VERSION ""

NS_ :

BS_:

BU_: PowertrainControlModule AtmosphericSensor SafetyRestraintSystem2 Aftertreatment_2_GasOutlet Aftertreatment_2_GasIntake DieselParticulateFilterControl Turbocharger SafetyRestraintSystem1 CabDisplay2 Aftertreatment_1_GasOutlet Aftertreatment_1_GasIntake OnBoardDataLogger OffBoardDiagnosticTool2 OffBoardDiagnosticTool1 FileServer ParkingBrakeController SeatController2 FanDriveController SteeringColumnUnit CommunicationUnitRadio CommunicationUnitSatellite CommunicationUnitCellular PropulsionBatteryCharger ChassisController2 ChassisController1 EngineValveControl AuxiliaryHeater2 AuxiliaryHeater1 ClutchUnit RampControl InformationSystem1 SuspensionSystemController2 OilSensor VehicleDynamicStability ExhaustEmissionController TransmissionDisplay2 TransmissionDisplay1 ClimateControl2 WaterPumpController RearAxleSteeringController LightingOperatorControl SeatController1 IgnitionController2 IgnitionController1 TirePressureController CabController2 CabController1 PneumaticSystemController SuspensionSystemController1 HydraulicPumpController EnduranceBrakingSystem RetarderExhaustEngine2 OnBoardDiagnosticUnit HeadwayController RetarderExhaustEngine1 CabDisplay1 ManagementComputer VirtualTerminal OffVehicleGateway PowerTakeOffFront HitchControl AuxiliaryValveControl BodyController TractorTrailerBridge1 StarterSystem ElectricalSystem VehicleSecurity VehicleNavigation AerodynamicControl ElectricalChargingSystem ClimateControl1 TripRecorder InstrumentCluster SuspensionDriveAxle2 SuspensionDriveAxle1 SuspensionSteerAxle SteeringController FuelSystem CruiseControl RetarderDriveline RetarderEngine BrakesDriveAxle2 BrakesDriveAxle1 BrakesSystemController BrakesSteerAxle AxleDrive2 AxleDrive1 AxleSteering PowerTakeOff ShiftConsoleSecondary ShiftConsolePrimary Transmission2 Transmission1 Engine2 Engine1

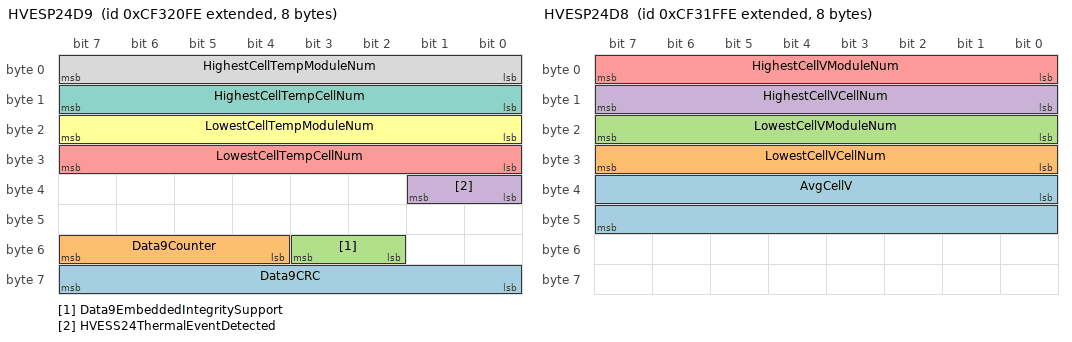
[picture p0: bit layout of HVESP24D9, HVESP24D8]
BO_ 2364743934 HVESP24D9: 8 Vector__XXX
 SG_ Data9CRC : 56|8@1+ (1,0) [0|255] "" Vector__XXX
 SG_ Data9Counter : 52|4@1+ (1,0) [0|15] "" Vector__XXX
 SG_ Data9EmbeddedIntegritySupport : 50|2@1+ (1,0) [0|3] "" Vector__XXX
 SG_ HVESS24ThermalEventDetected : 32|2@1+ (1,0) [0|3] "" Vector__XXX
 SG_ LowestCellTempCellNum : 24|8@1+ (1,0) [0|250] "" Vector__XXX
 SG_ LowestCellTempModuleNum : 16|8@1+ (1,0) [0|250] "" Vector__XXX
 SG_ HighestCellTempCellNum : 8|8@1+ (1,0) [0|250] "" Vector__XXX
 SG_ HighestCellTempModuleNum : 0|8@1+ (1,0) [0|250] "" Vector__XXX

BO_ 2364743678 HVESP24D8: 8 Vector__XXX
 SG_ AvgCellV : 32|16@1+ (0.001,0) [0|64.255] "V" Vector__XXX
 SG_ LowestCellVCellNum : 24|8@1+ (1,0) [0|250] "" Vector__XXX
 SG_ LowestCellVModuleNum : 16|8@1+ (1,0) [0|250] "" Vector__XXX
 SG_ HighestCellVCellNum : 8|8@1+ (1,0) [0|250] "" Vector__XXX
 SG_ HighestCellVModuleNum : 0|8@1+ (1,0) [0|250] "" Vector__XXX

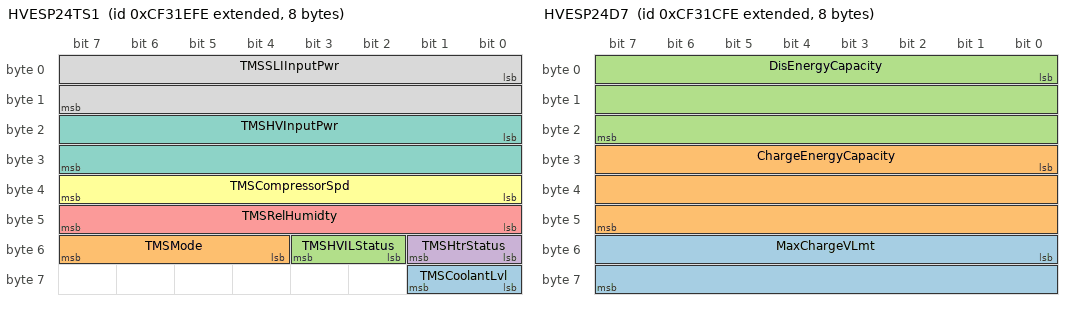
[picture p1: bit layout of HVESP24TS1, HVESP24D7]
BO_ 2364743422 HVESP24TS1: 8 Vector__XXX
 SG_ TMSCoolantLvl : 56|2@1+ (1,0) [0|3] "" Vector__XXX
 SG_ TMSMode : 52|4@1+ (1,0) [0|15] "" Vector__XXX
 SG_ TMSHVILStatus : 50|2@1+ (1,0) [0|3] "" Vector__XXX
 SG_ TMSHtrStatus : 48|2@1+ (1,0) [0|3] "" Vector__XXX
 SG_ TMSRelHumidty : 40|8@1+ (0.4,0) [0|100] "%" Vector__XXX
 SG_ TMSCompressorSpd : 32|8@1+ (32,0) [0|8000] "rpm" Vector__XXX
 SG_ TMSHVInputPwr : 16|16@1+ (0.5,0) [0|32127.5] "W" Vector__XXX
 SG_ TMSSLIInputPwr : 0|16@1+ (0.5,0) [0|32127.5] "W" Vector__XXX

BO_ 2364743166 HVESP24MS1: 8 Vector__XXX
 SG_ Module32OperationalStatus : 62|2@1+ (1,0) [0|3] "" Vector__XXX
 SG_ Module31OperationalStatus : 60|2@1+ (1,0) [0|3] "" Vector__XXX
 SG_ Module30OperationalStatus : 58|2@1+ (1,0) [0|3] "" Vector__XXX
 SG_ Module29OperationalStatus : 56|2@1+ (1,0) [0|3] "" Vector__XXX
 SG_ Module28OperationalStatus : 54|2@1+ (1,0) [0|3] "" Vector__XXX
 SG_ Module27OperationalStatus : 52|2@1+ (1,0) [0|3] "" Vector__XXX
 SG_ Module26OperationalStatus : 50|2@1+ (1,0) [0|3] "" Vector__XXX
 SG_ Module25OperationalStatus : 48|2@1+ (1,0) [0|3] "" Vector__XXX
 SG_ Module24OperationalStatus : 46|2@1+ (1,0) [0|3] "" Vector__XXX
 SG_ Module23OperationalStatus : 44|2@1+ (1,0) [0|3] "" Vector__XXX
 SG_ Module22OperationalStatus : 42|2@1+ (1,0) [0|3] "" Vector__XXX
 SG_ Module21OperationalStatus : 40|2@1+ (1,0) [0|3] "" Vector__XXX
 SG_ Module20OperationalStatus : 38|2@1+ (1,0) [0|3] "" Vector__XXX
 SG_ Module19OperationalStatus : 36|2@1+ (1,0) [0|3] "" Vector__XXX
 SG_ Module18OperationalStatus : 34|2@1+ (1,0) [0|3] "" Vector__XXX
 SG_ Module17OperationalStatus : 32|2@1+ (1,0) [0|3] "" Vector__XXX
 SG_ Module16OperationalStatus : 30|2@1+ (1,0) [0|3] "" Vector__XXX
 SG_ Module15OperationalStatus : 28|2@1+ (1,0) [0|3] "" Vector__XXX
 SG_ Module14OperationalStatus : 26|2@1+ (1,0) [0|3] "" Vector__XXX
 SG_ Module13OperationalStatus : 24|2@1+ (1,0) [0|3] "" Vector__XXX
 SG_ Module12OperationalStatus : 22|2@1+ (1,0) [0|3] "" Vector__XXX
 SG_ Module11OperationalStatus : 20|2@1+ (1,0) [0|3] "" Vector__XXX
 SG_ Module10OperationalStatus : 18|2@1+ (1,0) [0|3] "" Vector__XXX
 SG_ Module9OperationalStatus : 16|2@1+ (1,0) [0|3] "" Vector__XXX
 SG_ Module8OperationalStatus : 14|2@1+ (1,0) [0|3] "" Vector__XXX
 SG_ Module7OperationalStatus : 12|2@1+ (1,0) [0|3] "" Vector__XXX
 SG_ Module6OperationalStatus : 10|2@1+ (1,0) [0|3] "" Vector__XXX
 SG_ Module5OperationalStatus : 8|2@1+ (1,0) [0|3] "" Vector__XXX
 SG_ Module4OperationalStatus : 6|2@1+ (1,0) [0|3] "" Vector__XXX
 SG_ Module3OperationalStatus : 4|2@1+ (1,0) [0|3] "" Vector__XXX
 SG_ Module2OperationalStatus : 2|2@1+ (1,0) [0|3] "" Vector__XXX
 SG_ Module1OperationalStatus : 0|2@1+ (1,0) [0|3] "" Vector__XXX

BO_ 2364742910 HVESP24D7: 8 Vector__XXX
 SG_ MaxChargeVLmt : 48|16@1+ (0.05,0) [0|3212.75] "V" Vector__XXX
 SG_ ChargeEnergyCapacity : 24|24@1+ (0.001,0) [0|16449.535] "kWh" Vector__XXX
 SG_ DisEnergyCapacity : 0|24@1+ (0.001,0) [0|16449.535] "kWh" Vector__XXX

BO_ 2364742654 HVESP24S1: 8 Vector__XXX
 SG_ Status1CRC : 56|8@1+ (1,0) [0|255] "" Vector__XXX
 SG_ Status1Counter : 52|4@1+ (1,0) [0|15] "" Vector__XXX
 SG_ OperationalStatus : 44|4@1+ (1,0) [0|15] "" Vector__XXX
 SG_ HVBusConnectionStatus : 40|4@1+ (1,0) [0|15] "" Vector__XXX
 SG_ InternalChargerStatus : 32|2@1+ (1,0) [0|3] "" Vector__XXX
 SG_ CellBalancingActive : 30|2@1+ (1,0) [0|3] "" Vector__XXX
 SG_ CellBalanceStatus : 28|2@1+ (1,0) [0|3] "" Vector__XXX
 SG_ StOfChargeStatus : 24|4@1+ (1,0) [0|15] "" Vector__XXX
 SG_ InertiaSwStatus : 22|2@1+ (1,0) [0|3] "" Vector__XXX
 SG_ HVILStatus : 20|2@1+ (1,0) [0|3] "" Vector__XXX
 SG_ HVBusPassiveIsolTestStatus : 16|4@1+ (1,0) [0|15] "" Vector__XXX
 SG_ HVBusActiveIsolTestStatus : 12|4@1+ (1,0) [0|15] "" Vector__XXX
 SG_ CenterOfPackContactorSt : 10|2@1+ (1,0) [0|3] "" Vector__XXX
 SG_ HVBusPreChargeRelaySt : 8|2@1+ (1,0) [0|3] "" Vector__XXX
 SG_ HVBusDisconnectForewarning : 4|4@1+ (1,0) [0|15] "" Vector__XXX
 SG_ HVBusContactorSt17164 : 2|2@1+ (1,0) [0|3] "" Vector__XXX
 SG_ HVBusContactorSt : 0|2@1+ (1,0) [0|3] "" Vector__XXX

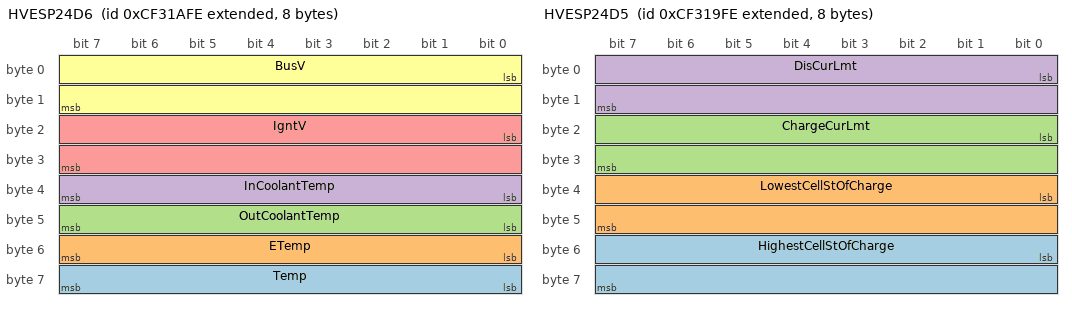
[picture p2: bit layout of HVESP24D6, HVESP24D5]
BO_ 2364742398 HVESP24D6: 8 Vector__XXX
 SG_ Temp : 56|8@1+ (1,-40) [-40|210] "°C" Vector__XXX
 SG_ ETemp : 48|8@1+ (1,-40) [-40|210] "°C" Vector__XXX
 SG_ OutCoolantTemp : 40|8@1+ (1,-40) [-40|210] "°C" Vector__XXX
 SG_ InCoolantTemp : 32|8@1+ (1,-40) [-40|210] "°C" Vector__XXX
 SG_ IgntV : 16|16@1+ (0.01,0) [0|642.55] "V" Vector__XXX
 SG_ BusV : 0|16@1+ (0.05,0) [0|3212.75] "V" Vector__XXX

BO_ 2364742142 HVESP24D5: 8 Vector__XXX
 SG_ HighestCellStOfCharge : 48|16@1+ (0.0015625,0) [0|100.3984375] "%" Vector__XXX
 SG_ LowestCellStOfCharge : 32|16@1+ (0.0015625,0) [0|100.3984375] "%" Vector__XXX
 SG_ ChargeCurLmt : 16|16@1+ (0.05,-1600) [0|1612.75] "A" Vector__XXX
 SG_ DisCurLmt : 0|16@1+ (0.05,-1600) [-1600|0] "A" Vector__XXX

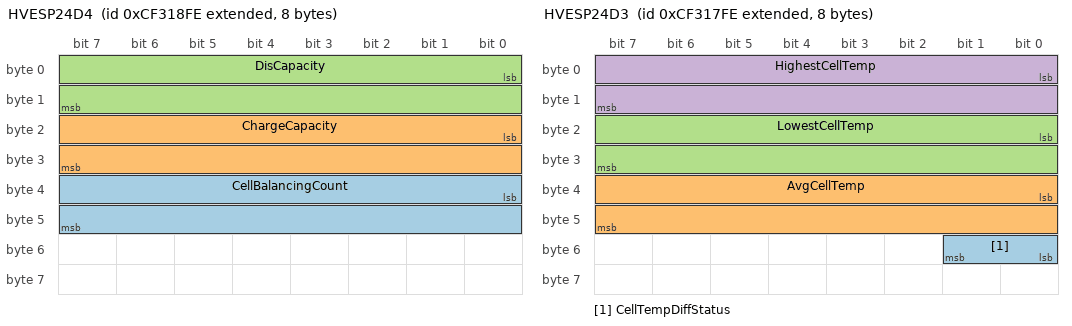
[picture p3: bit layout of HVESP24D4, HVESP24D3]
BO_ 2364741886 HVESP24D4: 8 Vector__XXX
 SG_ CellBalancingCount : 32|16@1+ (1,0) [0|64255] "" Vector__XXX
 SG_ ChargeCapacity : 16|16@1+ (0.01,0) [0|642.55] "Ah" Vector__XXX
 SG_ DisCapacity : 0|16@1+ (0.01,0) [0|642.55] "Ah" Vector__XXX

BO_ 2364741630 HVESP24D3: 8 Vector__XXX
 SG_ CellTempDiffStatus : 48|2@1+ (1,0) [0|3] "" Vector__XXX
 SG_ AvgCellTemp : 32|16@1+ (0.03125,-273) [-273|1734.96875] "°C" Vector__XXX
 SG_ LowestCellTemp : 16|16@1+ (0.03125,-273) [-273|1734.96875] "°C" Vector__XXX
 SG_ HighestCellTemp : 0|16@1+ (0.03125,-273) [-273|1734.96875] "°C" Vector__XXX

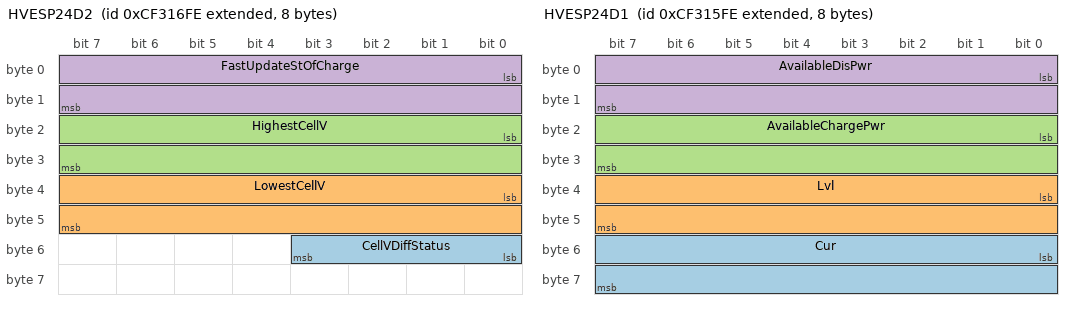
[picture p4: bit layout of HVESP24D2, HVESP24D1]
BO_ 2364741374 HVESP24D2: 8 Vector__XXX
 SG_ CellVDiffStatus : 48|4@1+ (1,0) [0|15] "" Vector__XXX
 SG_ LowestCellV : 32|16@1+ (0.001,0) [0|64.255] "V" Vector__XXX
 SG_ HighestCellV : 16|16@1+ (0.001,0) [0|64.255] "V" Vector__XXX
 SG_ FastUpdateStOfCharge : 0|16@1+ (0.0015625,0) [0|100.3984375] "%" Vector__XXX

BO_ 2364741118 HVESP24D1: 8 Vector__XXX
 SG_ Cur : 48|16@1+ (0.05,-1600) [-1600|1612.75] "A" Vector__XXX
 SG_ Lvl : 32|16@1+ (0.05,0) [0|3212.75] "V" Vector__XXX
 SG_ AvailableChargePwr : 16|16@1+ (0.05,0) [0|3212.75] "kW" Vector__XXX
 SG_ AvailableDisPwr : 0|16@1+ (0.05,0) [0|3212.75] "kW" Vector__XXX

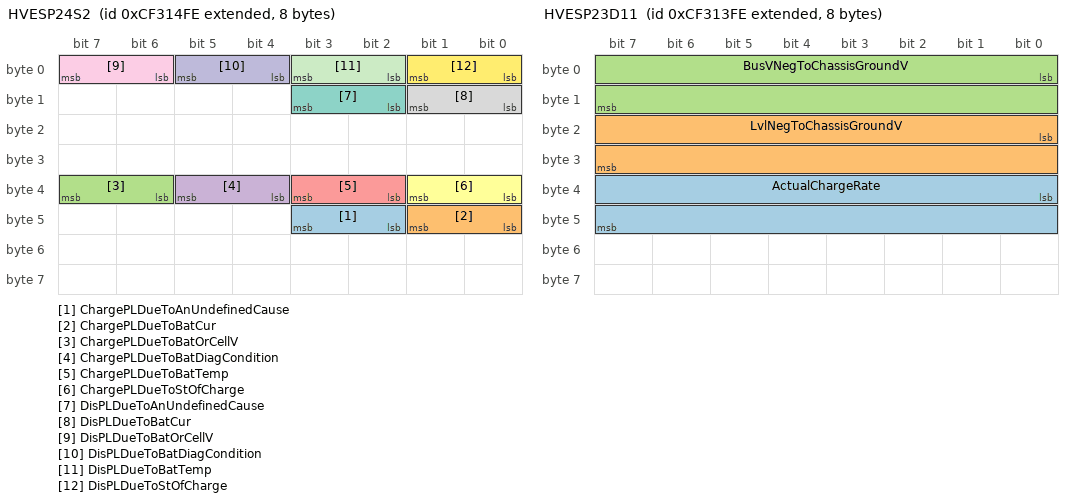
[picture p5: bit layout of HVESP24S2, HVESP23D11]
BO_ 2364740862 HVESP24S2: 8 Vector__XXX
 SG_ ChargePLDueToAnUndefinedCause : 42|2@1+ (1,0) [0|3] "" Vector__XXX
 SG_ ChargePLDueToBatCur : 40|2@1+ (1,0) [0|3] "" Vector__XXX
 SG_ ChargePLDueToBatOrCellV : 38|2@1+ (1,0) [0|3] "" Vector__XXX
 SG_ ChargePLDueToBatDiagCondition : 36|2@1+ (1,0) [0|3] "" Vector__XXX
 SG_ ChargePLDueToBatTemp : 34|2@1+ (1,0) [0|3] "" Vector__XXX
 SG_ ChargePLDueToStOfCharge : 32|2@1+ (1,0) [0|3] "" Vector__XXX
 SG_ DisPLDueToAnUndefinedCause : 10|2@1+ (1,0) [0|3] "" Vector__XXX
 SG_ DisPLDueToBatCur : 8|2@1+ (1,0) [0|3] "" Vector__XXX
 SG_ DisPLDueToBatOrCellV : 6|2@1+ (1,0) [0|3] "" Vector__XXX
 SG_ DisPLDueToBatDiagCondition : 4|2@1+ (1,0) [0|3] "" Vector__XXX
 SG_ DisPLDueToBatTemp : 2|2@1+ (1,0) [0|3] "" Vector__XXX
 SG_ DisPLDueToStOfCharge : 0|2@1+ (1,0) [0|3] "" Vector__XXX

BO_ 2364740606 HVESP23D11: 8 Vector__XXX
 SG_ ActualChargeRate : 32|16@1+ (0.05,0) [0|3212.75] "kW" Vector__XXX
 SG_ LvlNegToChassisGroundV : 16|16@1+ (0.05,0) [0|3212.75] "V" Vector__XXX
 SG_ BusVNegToChassisGroundV : 0|16@1+ (0.05,0) [0|3212.75] "V" Vector__XXX

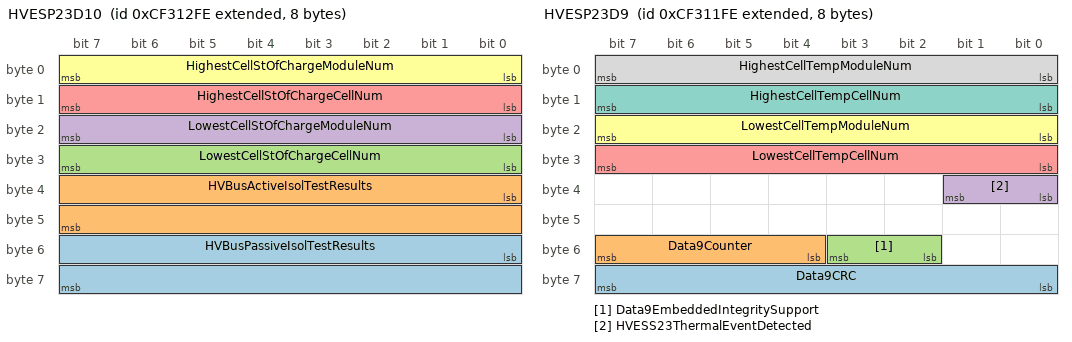
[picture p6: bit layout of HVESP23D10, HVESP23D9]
BO_ 2364740350 HVESP23D10: 8 Vector__XXX
 SG_ HVBusPassiveIsolTestResults : 48|16@1+ (0.1,0) [0|6425.5] "Ohm/V" Vector__XXX
 SG_ HVBusActiveIsolTestResults : 32|16@1+ (0.1,0) [0|6425.5] "Ohm/V" Vector__XXX
 SG_ LowestCellStOfChargeCellNum : 24|8@1+ (1,0) [0|250] "" Vector__XXX
 SG_ LowestCellStOfChargeModuleNum : 16|8@1+ (1,0) [0|250] "" Vector__XXX
 SG_ HighestCellStOfChargeCellNum : 8|8@1+ (1,0) [0|250] "" Vector__XXX
 SG_ HighestCellStOfChargeModuleNum : 0|8@1+ (1,0) [0|250] "" Vector__XXX

BO_ 2364740094 HVESP23D9: 8 Vector__XXX
 SG_ Data9CRC : 56|8@1+ (1,0) [0|255] "" Vector__XXX
 SG_ Data9Counter : 52|4@1+ (1,0) [0|15] "" Vector__XXX
 SG_ Data9EmbeddedIntegritySupport : 50|2@1+ (1,0) [0|3] "" Vector__XXX
 SG_ HVESS23ThermalEventDetected : 32|2@1+ (1,0) [0|3] "" Vector__XXX
 SG_ LowestCellTempCellNum : 24|8@1+ (1,0) [0|250] "" Vector__XXX
 SG_ LowestCellTempModuleNum : 16|8@1+ (1,0) [0|250] "" Vector__XXX
 SG_ HighestCellTempCellNum : 8|8@1+ (1,0) [0|250] "" Vector__XXX
 SG_ HighestCellTempModuleNum : 0|8@1+ (1,0) [0|250] "" Vector__XXX

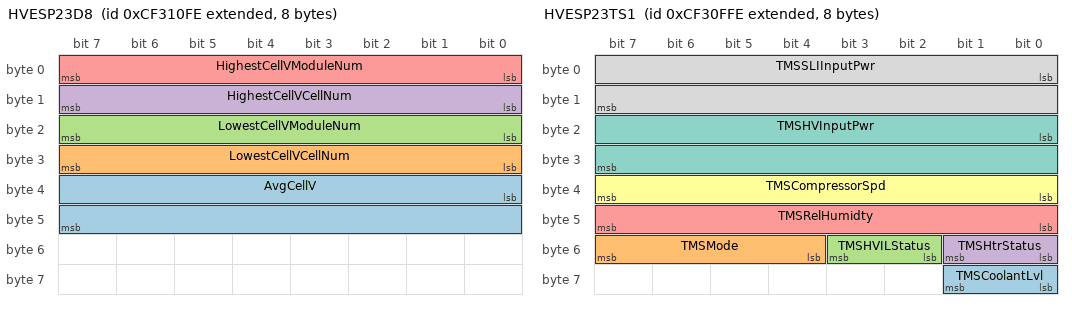
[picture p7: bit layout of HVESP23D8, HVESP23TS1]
BO_ 2364739838 HVESP23D8: 8 Vector__XXX
 SG_ AvgCellV : 32|16@1+ (0.001,0) [0|64.255] "V" Vector__XXX
 SG_ LowestCellVCellNum : 24|8@1+ (1,0) [0|250] "" Vector__XXX
 SG_ LowestCellVModuleNum : 16|8@1+ (1,0) [0|250] "" Vector__XXX
 SG_ HighestCellVCellNum : 8|8@1+ (1,0) [0|250] "" Vector__XXX
 SG_ HighestCellVModuleNum : 0|8@1+ (1,0) [0|250] "" Vector__XXX

BO_ 2364739582 HVESP23TS1: 8 Vector__XXX
 SG_ TMSCoolantLvl : 56|2@1+ (1,0) [0|3] "" Vector__XXX
 SG_ TMSMode : 52|4@1+ (1,0) [0|15] "" Vector__XXX
 SG_ TMSHVILStatus : 50|2@1+ (1,0) [0|3] "" Vector__XXX
 SG_ TMSHtrStatus : 48|2@1+ (1,0) [0|3] "" Vector__XXX
 SG_ TMSRelHumidty : 40|8@1+ (0.4,0) [0|100] "%" Vector__XXX
 SG_ TMSCompressorSpd : 32|8@1+ (32,0) [0|8000] "rpm" Vector__XXX
 SG_ TMSHVInputPwr : 16|16@1+ (0.5,0) [0|32127.5] "W" Vector__XXX
 SG_ TMSSLIInputPwr : 0|16@1+ (0.5,0) [0|32127.5] "W" Vector__XXX

BO_ 2364739326 HVESP23MS1: 8 Vector__XXX
 SG_ Module32OperationalStatus : 62|2@1+ (1,0) [0|3] "" Vector__XXX
 SG_ Module31OperationalStatus : 60|2@1+ (1,0) [0|3] "" Vector__XXX
 SG_ Module30OperationalStatus : 58|2@1+ (1,0) [0|3] "" Vector__XXX
 SG_ Module29OperationalStatus : 56|2@1+ (1,0) [0|3] "" Vector__XXX
 SG_ Module28OperationalStatus : 54|2@1+ (1,0) [0|3] "" Vector__XXX
 SG_ Module27OperationalStatus : 52|2@1+ (1,0) [0|3] "" Vector__XXX
 SG_ Module26OperationalStatus : 50|2@1+ (1,0) [0|3] "" Vector__XXX
 SG_ Module25OperationalStatus : 48|2@1+ (1,0) [0|3] "" Vector__XXX
 SG_ Module24OperationalStatus : 46|2@1+ (1,0) [0|3] "" Vector__XXX
 SG_ Module23OperationalStatus : 44|2@1+ (1,0) [0|3] "" Vector__XXX
 SG_ Module22OperationalStatus : 42|2@1+ (1,0) [0|3] "" Vector__XXX
 SG_ Module21OperationalStatus : 40|2@1+ (1,0) [0|3] "" Vector__XXX
 SG_ Module20OperationalStatus : 38|2@1+ (1,0) [0|3] "" Vector__XXX
 SG_ Module19OperationalStatus : 36|2@1+ (1,0) [0|3] "" Vector__XXX
 SG_ Module18OperationalStatus : 34|2@1+ (1,0) [0|3] "" Vector__XXX
 SG_ Module17OperationalStatus : 32|2@1+ (1,0) [0|3] "" Vector__XXX
 SG_ Module16OperationalStatus : 30|2@1+ (1,0) [0|3] "" Vector__XXX
 SG_ Module15OperationalStatus : 28|2@1+ (1,0) [0|3] "" Vector__XXX
 SG_ Module14OperationalStatus : 26|2@1+ (1,0) [0|3] "" Vector__XXX
 SG_ Module13OperationalStatus : 24|2@1+ (1,0) [0|3] "" Vector__XXX
 SG_ Module12OperationalStatus : 22|2@1+ (1,0) [0|3] "" Vector__XXX
 SG_ Module11OperationalStatus : 20|2@1+ (1,0) [0|3] "" Vector__XXX
 SG_ Module10OperationalStatus : 18|2@1+ (1,0) [0|3] "" Vector__XXX
 SG_ Module9OperationalStatus : 16|2@1+ (1,0) [0|3] "" Vector__XXX
 SG_ Module8OperationalStatus : 14|2@1+ (1,0) [0|3] "" Vector__XXX
 SG_ Module7OperationalStatus : 12|2@1+ (1,0) [0|3] "" Vector__XXX
 SG_ Module6OperationalStatus : 10|2@1+ (1,0) [0|3] "" Vector__XXX
 SG_ Module5OperationalStatus : 8|2@1+ (1,0) [0|3] "" Vector__XXX
 SG_ Module4OperationalStatus : 6|2@1+ (1,0) [0|3] "" Vector__XXX
 SG_ Module3OperationalStatus : 4|2@1+ (1,0) [0|3] "" Vector__XXX
 SG_ Module2OperationalStatus : 2|2@1+ (1,0) [0|3] "" Vector__XXX
 SG_ Module1OperationalStatus : 0|2@1+ (1,0) [0|3] "" Vector__XXX

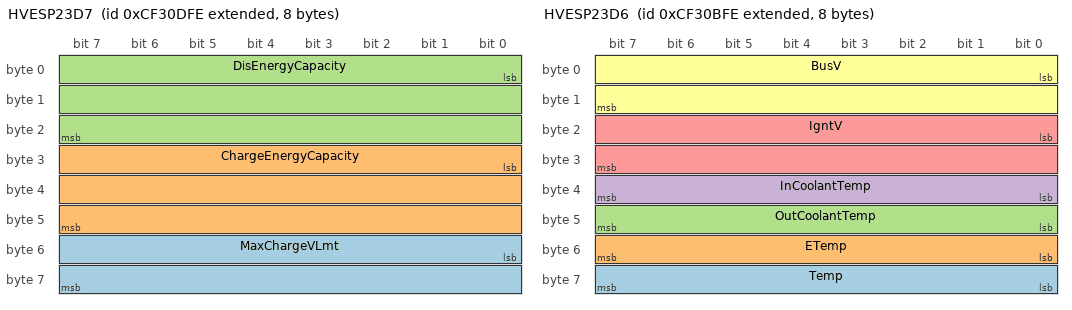
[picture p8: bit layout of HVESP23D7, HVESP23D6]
BO_ 2364739070 HVESP23D7: 8 Vector__XXX
 SG_ MaxChargeVLmt : 48|16@1+ (0.05,0) [0|3212.75] "V" Vector__XXX
 SG_ ChargeEnergyCapacity : 24|24@1+ (0.001,0) [0|16449.535] "kWh" Vector__XXX
 SG_ DisEnergyCapacity : 0|24@1+ (0.001,0) [0|16449.535] "kWh" Vector__XXX

BO_ 2364738814 HVESP23S1: 8 Vector__XXX
 SG_ Status1CRC : 56|8@1+ (1,0) [0|255] "" Vector__XXX
 SG_ Status1Counter : 52|4@1+ (1,0) [0|15] "" Vector__XXX
 SG_ OperationalStatus : 44|4@1+ (1,0) [0|15] "" Vector__XXX
 SG_ HVBusConnectionStatus : 40|4@1+ (1,0) [0|15] "" Vector__XXX
 SG_ InternalChargerStatus : 32|2@1+ (1,0) [0|3] "" Vector__XXX
 SG_ CellBalancingActive : 30|2@1+ (1,0) [0|3] "" Vector__XXX
 SG_ CellBalanceStatus : 28|2@1+ (1,0) [0|3] "" Vector__XXX
 SG_ StOfChargeStatus : 24|4@1+ (1,0) [0|15] "" Vector__XXX
 SG_ InertiaSwStatus : 22|2@1+ (1,0) [0|3] "" Vector__XXX
 SG_ HVILStatus : 20|2@1+ (1,0) [0|3] "" Vector__XXX
 SG_ HVBusPassiveIsolTestStatus : 16|4@1+ (1,0) [0|15] "" Vector__XXX
 SG_ HVBusActiveIsolTestStatus : 12|4@1+ (1,0) [0|15] "" Vector__XXX
 SG_ CenterOfPackContactorSt : 10|2@1+ (1,0) [0|3] "" Vector__XXX
 SG_ HVBusPreChargeRelaySt : 8|2@1+ (1,0) [0|3] "" Vector__XXX
 SG_ HVBusDisconnectForewarning : 4|4@1+ (1,0) [0|15] "" Vector__XXX
 SG_ HVBusContactorSt17022 : 2|2@1+ (1,0) [0|3] "" Vector__XXX
 SG_ HVBusContactorSt : 0|2@1+ (1,0) [0|3] "" Vector__XXX

BO_ 2364738558 HVESP23D6: 8 Vector__XXX
 SG_ Temp : 56|8@1+ (1,-40) [-40|210] "°C" Vector__XXX
 SG_ ETemp : 48|8@1+ (1,-40) [-40|210] "°C" Vector__XXX
 SG_ OutCoolantTemp : 40|8@1+ (1,-40) [-40|210] "°C" Vector__XXX
 SG_ InCoolantTemp : 32|8@1+ (1,-40) [-40|210] "°C" Vector__XXX
 SG_ IgntV : 16|16@1+ (0.01,0) [0|642.55] "V" Vector__XXX
 SG_ BusV : 0|16@1+ (0.05,0) [0|3212.75] "V" Vector__XXX

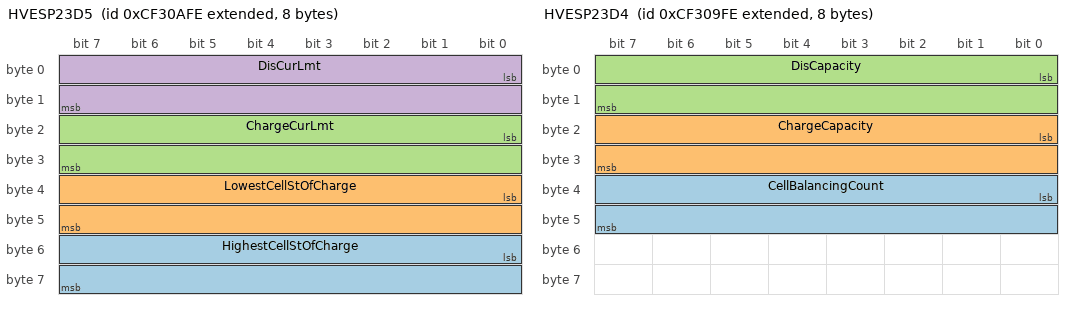
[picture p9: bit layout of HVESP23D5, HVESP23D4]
BO_ 2364738302 HVESP23D5: 8 Vector__XXX
 SG_ HighestCellStOfCharge : 48|16@1+ (0.0015625,0) [0|100.3984375] "%" Vector__XXX
 SG_ LowestCellStOfCharge : 32|16@1+ (0.0015625,0) [0|100.3984375] "%" Vector__XXX
 SG_ ChargeCurLmt : 16|16@1+ (0.05,-1600) [0|1612.75] "A" Vector__XXX
 SG_ DisCurLmt : 0|16@1+ (0.05,-1600) [-1600|0] "A" Vector__XXX

BO_ 2364738046 HVESP23D4: 8 Vector__XXX
 SG_ CellBalancingCount : 32|16@1+ (1,0) [0|64255] "" Vector__XXX
 SG_ ChargeCapacity : 16|16@1+ (0.01,0) [0|642.55] "Ah" Vector__XXX
 SG_ DisCapacity : 0|16@1+ (0.01,0) [0|642.55] "Ah" Vector__XXX

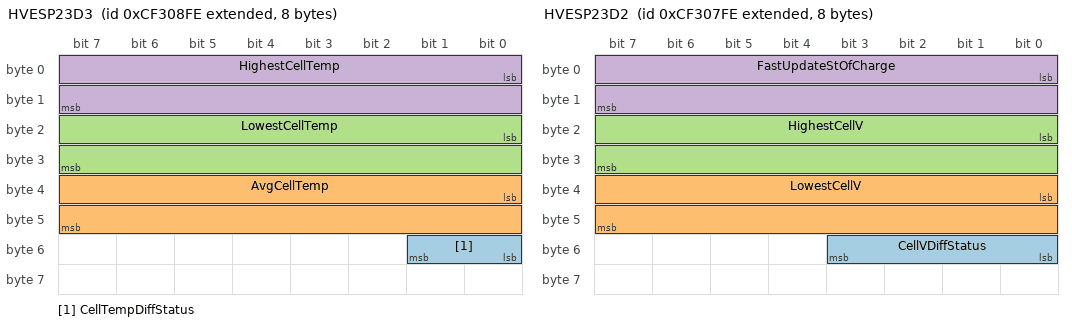
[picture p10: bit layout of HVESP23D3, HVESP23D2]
BO_ 2364737790 HVESP23D3: 8 Vector__XXX
 SG_ CellTempDiffStatus : 48|2@1+ (1,0) [0|3] "" Vector__XXX
 SG_ AvgCellTemp : 32|16@1+ (0.03125,-273) [-273|1734.96875] "°C" Vector__XXX
 SG_ LowestCellTemp : 16|16@1+ (0.03125,-273) [-273|1734.96875] "°C" Vector__XXX
 SG_ HighestCellTemp : 0|16@1+ (0.03125,-273) [-273|1734.96875] "°C" Vector__XXX

BO_ 2364737534 HVESP23D2: 8 Vector__XXX
 SG_ CellVDiffStatus : 48|4@1+ (1,0) [0|15] "" Vector__XXX
 SG_ LowestCellV : 32|16@1+ (0.001,0) [0|64.255] "V" Vector__XXX
 SG_ HighestCellV : 16|16@1+ (0.001,0) [0|64.255] "V" Vector__XXX
 SG_ FastUpdateStOfCharge : 0|16@1+ (0.0015625,0) [0|100.3984375] "%" Vector__XXX

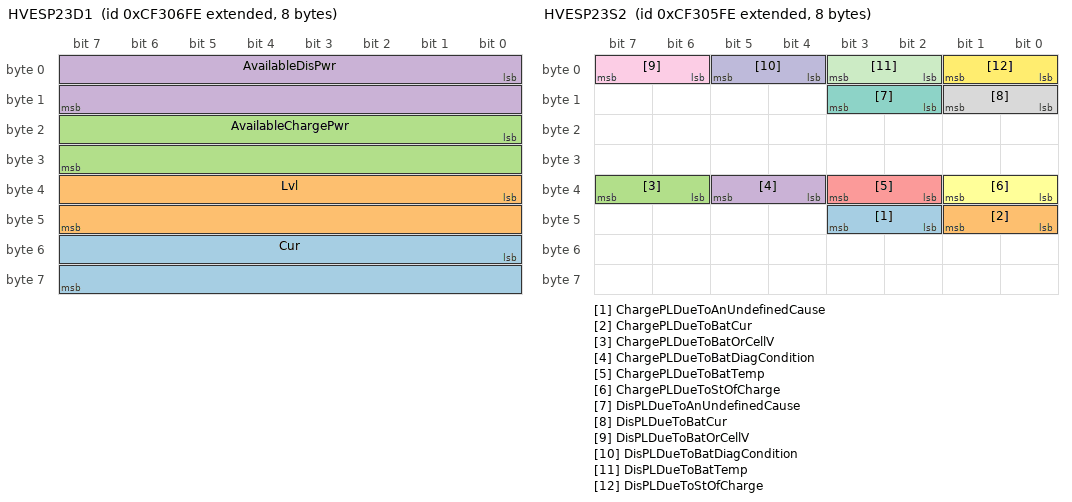
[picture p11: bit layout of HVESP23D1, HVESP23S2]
BO_ 2364737278 HVESP23D1: 8 Vector__XXX
 SG_ Cur : 48|16@1+ (0.05,-1600) [-1600|1612.75] "A" Vector__XXX
 SG_ Lvl : 32|16@1+ (0.05,0) [0|3212.75] "V" Vector__XXX
 SG_ AvailableChargePwr : 16|16@1+ (0.05,0) [0|3212.75] "kW" Vector__XXX
 SG_ AvailableDisPwr : 0|16@1+ (0.05,0) [0|3212.75] "kW" Vector__XXX

BO_ 2364737022 HVESP23S2: 8 Vector__XXX
 SG_ ChargePLDueToAnUndefinedCause : 42|2@1+ (1,0) [0|3] "" Vector__XXX
 SG_ ChargePLDueToBatCur : 40|2@1+ (1,0) [0|3] "" Vector__XXX
 SG_ ChargePLDueToBatOrCellV : 38|2@1+ (1,0) [0|3] "" Vector__XXX
 SG_ ChargePLDueToBatDiagCondition : 36|2@1+ (1,0) [0|3] "" Vector__XXX
 SG_ ChargePLDueToBatTemp : 34|2@1+ (1,0) [0|3] "" Vector__XXX
 SG_ ChargePLDueToStOfCharge : 32|2@1+ (1,0) [0|3] "" Vector__XXX
 SG_ DisPLDueToAnUndefinedCause : 10|2@1+ (1,0) [0|3] "" Vector__XXX
 SG_ DisPLDueToBatCur : 8|2@1+ (1,0) [0|3] "" Vector__XXX
 SG_ DisPLDueToBatOrCellV : 6|2@1+ (1,0) [0|3] "" Vector__XXX
 SG_ DisPLDueToBatDiagCondition : 4|2@1+ (1,0) [0|3] "" Vector__XXX
 SG_ DisPLDueToBatTemp : 2|2@1+ (1,0) [0|3] "" Vector__XXX
 SG_ DisPLDueToStOfCharge : 0|2@1+ (1,0) [0|3] "" Vector__XXX

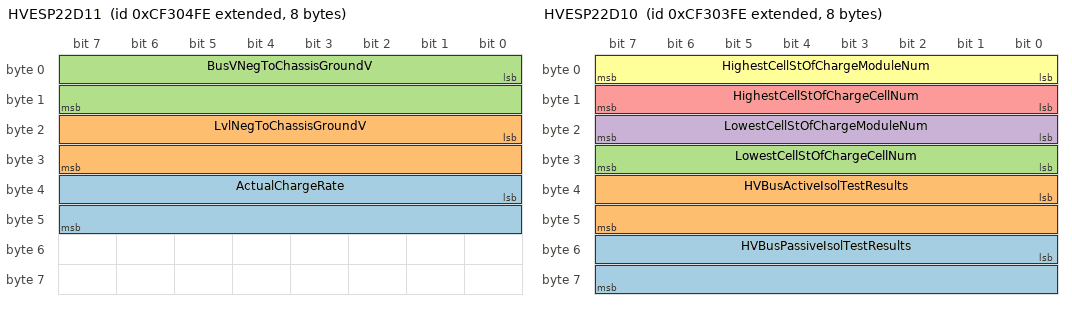
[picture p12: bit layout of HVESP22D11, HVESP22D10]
BO_ 2364736766 HVESP22D11: 8 Vector__XXX
 SG_ ActualChargeRate : 32|16@1+ (0.05,0) [0|3212.75] "kW" Vector__XXX
 SG_ LvlNegToChassisGroundV : 16|16@1+ (0.05,0) [0|3212.75] "V" Vector__XXX
 SG_ BusVNegToChassisGroundV : 0|16@1+ (0.05,0) [0|3212.75] "V" Vector__XXX

BO_ 2364736510 HVESP22D10: 8 Vector__XXX
 SG_ HVBusPassiveIsolTestResults : 48|16@1+ (0.1,0) [0|6425.5] "Ohm/V" Vector__XXX
 SG_ HVBusActiveIsolTestResults : 32|16@1+ (0.1,0) [0|6425.5] "Ohm/V" Vector__XXX
 SG_ LowestCellStOfChargeCellNum : 24|8@1+ (1,0) [0|250] "" Vector__XXX
 SG_ LowestCellStOfChargeModuleNum : 16|8@1+ (1,0) [0|250] "" Vector__XXX
 SG_ HighestCellStOfChargeCellNum : 8|8@1+ (1,0) [0|250] "" Vector__XXX
 SG_ HighestCellStOfChargeModuleNum : 0|8@1+ (1,0) [0|250] "" Vector__XXX

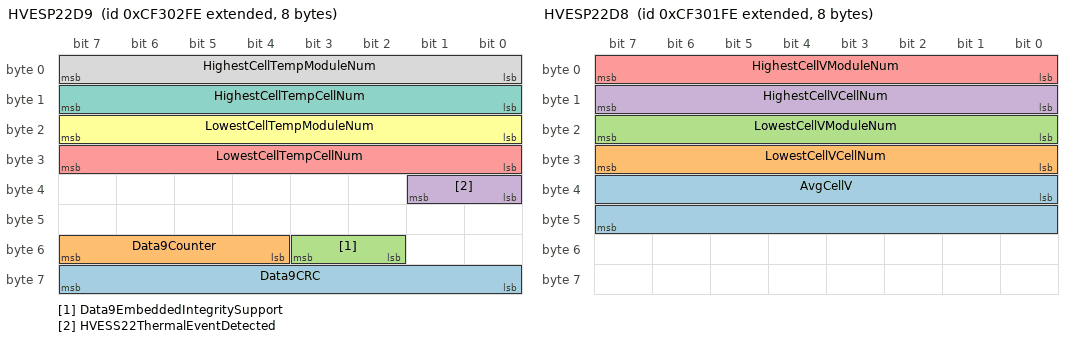
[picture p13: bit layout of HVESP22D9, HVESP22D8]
BO_ 2364736254 HVESP22D9: 8 Vector__XXX
 SG_ Data9CRC : 56|8@1+ (1,0) [0|255] "" Vector__XXX
 SG_ Data9Counter : 52|4@1+ (1,0) [0|15] "" Vector__XXX
 SG_ Data9EmbeddedIntegritySupport : 50|2@1+ (1,0) [0|3] "" Vector__XXX
 SG_ HVESS22ThermalEventDetected : 32|2@1+ (1,0) [0|3] "" Vector__XXX
 SG_ LowestCellTempCellNum : 24|8@1+ (1,0) [0|250] "" Vector__XXX
 SG_ LowestCellTempModuleNum : 16|8@1+ (1,0) [0|250] "" Vector__XXX
 SG_ HighestCellTempCellNum : 8|8@1+ (1,0) [0|250] "" Vector__XXX
 SG_ HighestCellTempModuleNum : 0|8@1+ (1,0) [0|250] "" Vector__XXX

BO_ 2364735998 HVESP22D8: 8 Vector__XXX
 SG_ AvgCellV : 32|16@1+ (0.001,0) [0|64.255] "V" Vector__XXX
 SG_ LowestCellVCellNum : 24|8@1+ (1,0) [0|250] "" Vector__XXX
 SG_ LowestCellVModuleNum : 16|8@1+ (1,0) [0|250] "" Vector__XXX
 SG_ HighestCellVCellNum : 8|8@1+ (1,0) [0|250] "" Vector__XXX
 SG_ HighestCellVModuleNum : 0|8@1+ (1,0) [0|250] "" Vector__XXX

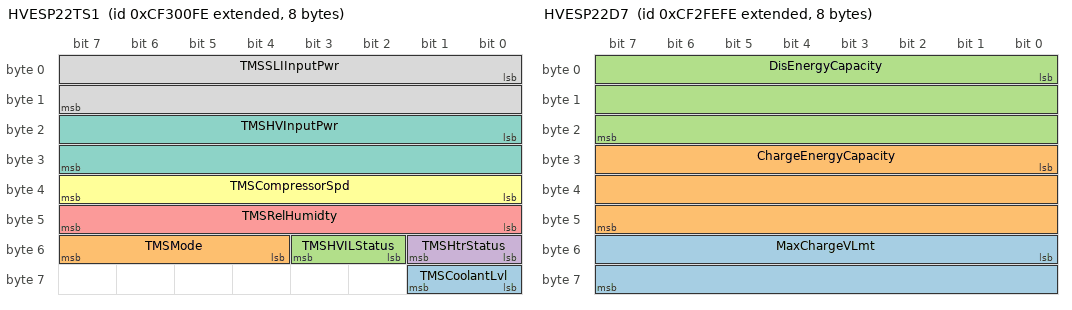
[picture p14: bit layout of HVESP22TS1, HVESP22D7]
BO_ 2364735742 HVESP22TS1: 8 Vector__XXX
 SG_ TMSCoolantLvl : 56|2@1+ (1,0) [0|3] "" Vector__XXX
 SG_ TMSMode : 52|4@1+ (1,0) [0|15] "" Vector__XXX
 SG_ TMSHVILStatus : 50|2@1+ (1,0) [0|3] "" Vector__XXX
 SG_ TMSHtrStatus : 48|2@1+ (1,0) [0|3] "" Vector__XXX
 SG_ TMSRelHumidty : 40|8@1+ (0.4,0) [0|100] "%" Vector__XXX
 SG_ TMSCompressorSpd : 32|8@1+ (32,0) [0|8000] "rpm" Vector__XXX
 SG_ TMSHVInputPwr : 16|16@1+ (0.5,0) [0|32127.5] "W" Vector__XXX
 SG_ TMSSLIInputPwr : 0|16@1+ (0.5,0) [0|32127.5] "W" Vector__XXX

BO_ 2364735486 HVESP22MS1: 8 Vector__XXX
 SG_ Module32OperationalStatus : 62|2@1+ (1,0) [0|3] "" Vector__XXX
 SG_ Module31OperationalStatus : 60|2@1+ (1,0) [0|3] "" Vector__XXX
 SG_ Module30OperationalStatus : 58|2@1+ (1,0) [0|3] "" Vector__XXX
 SG_ Module29OperationalStatus : 56|2@1+ (1,0) [0|3] "" Vector__XXX
 SG_ Module28OperationalStatus : 54|2@1+ (1,0) [0|3] "" Vector__XXX
 SG_ Module27OperationalStatus : 52|2@1+ (1,0) [0|3] "" Vector__XXX
 SG_ Module26OperationalStatus : 50|2@1+ (1,0) [0|3] "" Vector__XXX
 SG_ Module25OperationalStatus : 48|2@1+ (1,0) [0|3] "" Vector__XXX
 SG_ Module24OperationalStatus : 46|2@1+ (1,0) [0|3] "" Vector__XXX
 SG_ Module23OperationalStatus : 44|2@1+ (1,0) [0|3] "" Vector__XXX
 SG_ Module22OperationalStatus : 42|2@1+ (1,0) [0|3] "" Vector__XXX
 SG_ Module21OperationalStatus : 40|2@1+ (1,0) [0|3] "" Vector__XXX
 SG_ Module20OperationalStatus : 38|2@1+ (1,0) [0|3] "" Vector__XXX
 SG_ Module19OperationalStatus : 36|2@1+ (1,0) [0|3] "" Vector__XXX
 SG_ Module18OperationalStatus : 34|2@1+ (1,0) [0|3] "" Vector__XXX
 SG_ Module17OperationalStatus : 32|2@1+ (1,0) [0|3] "" Vector__XXX
 SG_ Module16OperationalStatus : 30|2@1+ (1,0) [0|3] "" Vector__XXX
 SG_ Module15OperationalStatus : 28|2@1+ (1,0) [0|3] "" Vector__XXX
 SG_ Module14OperationalStatus : 26|2@1+ (1,0) [0|3] "" Vector__XXX
 SG_ Module13OperationalStatus : 24|2@1+ (1,0) [0|3] "" Vector__XXX
 SG_ Module12OperationalStatus : 22|2@1+ (1,0) [0|3] "" Vector__XXX
 SG_ Module11OperationalStatus : 20|2@1+ (1,0) [0|3] "" Vector__XXX
 SG_ Module10OperationalStatus : 18|2@1+ (1,0) [0|3] "" Vector__XXX
 SG_ Module9OperationalStatus : 16|2@1+ (1,0) [0|3] "" Vector__XXX
 SG_ Module8OperationalStatus : 14|2@1+ (1,0) [0|3] "" Vector__XXX
 SG_ Module7OperationalStatus : 12|2@1+ (1,0) [0|3] "" Vector__XXX
 SG_ Module6OperationalStatus : 10|2@1+ (1,0) [0|3] "" Vector__XXX
 SG_ Module5OperationalStatus : 8|2@1+ (1,0) [0|3] "" Vector__XXX
 SG_ Module4OperationalStatus : 6|2@1+ (1,0) [0|3] "" Vector__XXX
 SG_ Module3OperationalStatus : 4|2@1+ (1,0) [0|3] "" Vector__XXX
 SG_ Module2OperationalStatus : 2|2@1+ (1,0) [0|3] "" Vector__XXX
 SG_ Module1OperationalStatus : 0|2@1+ (1,0) [0|3] "" Vector__XXX

BO_ 2364735230 HVESP22D7: 8 Vector__XXX
 SG_ MaxChargeVLmt : 48|16@1+ (0.05,0) [0|3212.75] "V" Vector__XXX
 SG_ ChargeEnergyCapacity : 24|24@1+ (0.001,0) [0|16449.535] "kWh" Vector__XXX
 SG_ DisEnergyCapacity : 0|24@1+ (0.001,0) [0|16449.535] "kWh" Vector__XXX

BO_ 2364734974 HVESP22S1: 8 Vector__XXX
 SG_ Status1CRC : 56|8@1+ (1,0) [0|255] "" Vector__XXX
 SG_ Status1Counter : 52|4@1+ (1,0) [0|15] "" Vector__XXX
 SG_ OperationalStatus : 44|4@1+ (1,0) [0|15] "" Vector__XXX
 SG_ HVBusConnectionStatus : 40|4@1+ (1,0) [0|15] "" Vector__XXX
 SG_ InternalChargerStatus : 32|2@1+ (1,0) [0|3] "" Vector__XXX
 SG_ CellBalancingActive : 30|2@1+ (1,0) [0|3] "" Vector__XXX
 SG_ CellBalanceStatus : 28|2@1+ (1,0) [0|3] "" Vector__XXX
 SG_ StOfChargeStatus : 24|4@1+ (1,0) [0|15] "" Vector__XXX
 SG_ InertiaSwStatus : 22|2@1+ (1,0) [0|3] "" Vector__XXX
 SG_ HVILStatus : 20|2@1+ (1,0) [0|3] "" Vector__XXX
 SG_ HVBusPassiveIsolTestStatus : 16|4@1+ (1,0) [0|15] "" Vector__XXX
 SG_ HVBusActiveIsolTestStatus : 12|4@1+ (1,0) [0|15] "" Vector__XXX
 SG_ CenterOfPackContactorSt : 10|2@1+ (1,0) [0|3] "" Vector__XXX
 SG_ HVBusPreChargeRelaySt : 8|2@1+ (1,0) [0|3] "" Vector__XXX
 SG_ HVBusDisconnectForewarning : 4|4@1+ (1,0) [0|15] "" Vector__XXX
 SG_ HVBusContactorSt16880 : 2|2@1+ (1,0) [0|3] "" Vector__XXX
 SG_ HVBusContactorSt : 0|2@1+ (1,0) [0|3] "" Vector__XXX

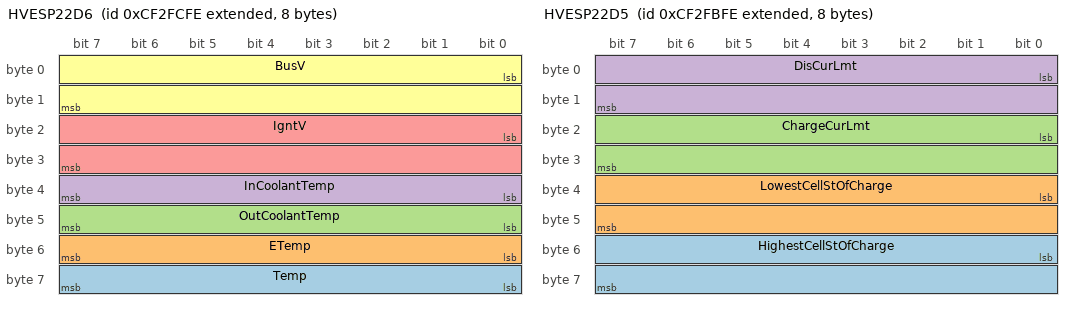
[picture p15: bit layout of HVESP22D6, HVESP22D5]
BO_ 2364734718 HVESP22D6: 8 Vector__XXX
 SG_ Temp : 56|8@1+ (1,-40) [-40|210] "°C" Vector__XXX
 SG_ ETemp : 48|8@1+ (1,-40) [-40|210] "°C" Vector__XXX
 SG_ OutCoolantTemp : 40|8@1+ (1,-40) [-40|210] "°C" Vector__XXX
 SG_ InCoolantTemp : 32|8@1+ (1,-40) [-40|210] "°C" Vector__XXX
 SG_ IgntV : 16|16@1+ (0.01,0) [0|642.55] "V" Vector__XXX
 SG_ BusV : 0|16@1+ (0.05,0) [0|3212.75] "V" Vector__XXX

BO_ 2364734462 HVESP22D5: 8 Vector__XXX
 SG_ HighestCellStOfCharge : 48|16@1+ (0.0015625,0) [0|100.3984375] "%" Vector__XXX
 SG_ LowestCellStOfCharge : 32|16@1+ (0.0015625,0) [0|100.3984375] "%" Vector__XXX
 SG_ ChargeCurLmt : 16|16@1+ (0.05,-1600) [0|1612.75] "A" Vector__XXX
 SG_ DisCurLmt : 0|16@1+ (0.05,-1600) [-1600|0] "A" Vector__XXX

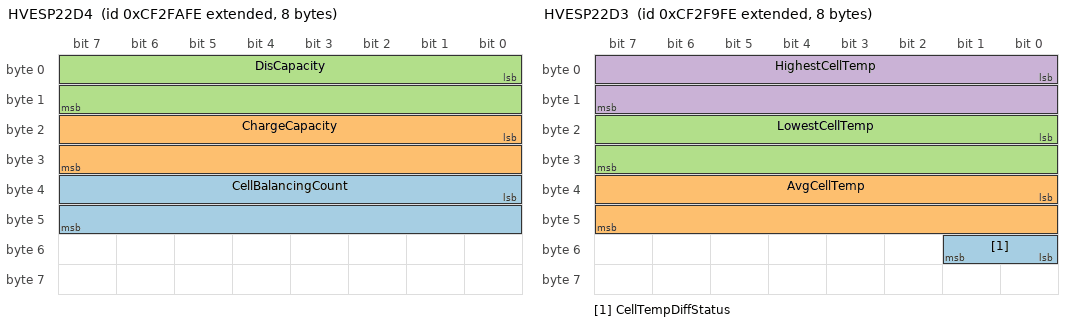
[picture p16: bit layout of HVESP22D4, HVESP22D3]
BO_ 2364734206 HVESP22D4: 8 Vector__XXX
 SG_ CellBalancingCount : 32|16@1+ (1,0) [0|64255] "" Vector__XXX
 SG_ ChargeCapacity : 16|16@1+ (0.01,0) [0|642.55] "Ah" Vector__XXX
 SG_ DisCapacity : 0|16@1+ (0.01,0) [0|642.55] "Ah" Vector__XXX

BO_ 2364733950 HVESP22D3: 8 Vector__XXX
 SG_ CellTempDiffStatus : 48|2@1+ (1,0) [0|3] "" Vector__XXX
 SG_ AvgCellTemp : 32|16@1+ (0.03125,-273) [-273|1734.96875] "°C" Vector__XXX
 SG_ LowestCellTemp : 16|16@1+ (0.03125,-273) [-273|1734.96875] "°C" Vector__XXX
 SG_ HighestCellTemp : 0|16@1+ (0.03125,-273) [-273|1734.96875] "°C" Vector__XXX

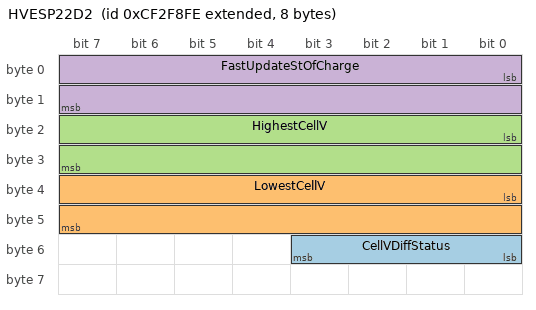
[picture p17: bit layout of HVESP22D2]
BO_ 2364733694 HVESP22D2: 8 Vector__XXX
 SG_ CellVDiffStatus : 48|4@1+ (1,0) [0|15] "" Vector__XXX
 SG_ LowestCellV : 32|16@1+ (0.001,0) [0|64.255] "V" Vector__XXX
 SG_ HighestCellV : 16|16@1+ (0.001,0) [0|64.255] "V" Vector__XXX
 SG_ FastUpdateStOfCharge : 0|16@1+ (0.0015625,0) [0|100.3984375] "%" Vector__XXX

CM_ BO_ 2364743934 "High Voltage Energy Storage Pack 24 Data 9
Data set 9 (thermal) for High Voltage Energy Storage Pack 24.";
CM_ SG_ 2364743934 Data9CRC "The CRC is defined as follows:
• Length: 8 bits
• Polynomial: x^8+x^5+x^3+x^2+x+1
• Initial Value: FFh
• Input Data Reflection: Not reflected
• Result Data Reflection: Not reflected
• XOR value: FFh
SAE makes no claim of the functional safety ...";
CM_ SG_ 2364743934 Data9Counter "The message counter is used to detect situations where the transmitting ECU malfunction repeats the same frame all the time. The receiver of the information may use the counter parameter to detect this situation. The transmitting device will ...";
CM_ SG_ 2364743934 Data9EmbeddedIntegritySupport "Indicates SPN 23045 (HVESP24 Data 9 CRC) and SPN 23044 (HVESP24 Data 9 Counter) are supported by the sender.
00b = Embedded CRC and Counter are supported by the sender
01b = Protection is supported using J1939-76 SHM
10b = Reserved
11b = CRC and ...";
CM_ SG_ 2364743934 HVESS24ThermalEventDetected "A sensor has detected the presence of a thermal event at or near High Voltage Energy Storage Pack instance.
00b = No Thermal Event Detected
01b = Thermal Event Detected
10b = Error
11b = Not available
This parameter is for one of multiple packs ...";
CM_ SG_ 2364743934 LowestCellTempCellNum "Identifies the location of SPN 17147 (HVESP24 Lowest Cell Temperature) within SPN 17230 (HVESP24 Lowest Cell Temperature Module Number).
This parameter is for one of multiple packs in an HVESS. If there is only one pack in the system, the HVESS ...";
CM_ SG_ 2364743934 LowestCellTempModuleNum "Identifies the location of the module containing SPN 17147 (HVESP24 Lowest Cell Temperature).
This parameter is for one of multiple packs in an HVESS. If there is only one pack in the system, the HVESS parameters should be used. If there are ...";
CM_ SG_ 2364743934 HighestCellTempCellNum "Identifies the location of SPN 17146 (HVESP24 Highest Cell Temperature) within SPN 17228 (HVESP24 Highest Cell Temperature Module Number).
This parameter is for one of multiple packs in an HVESS. If there is only one pack in the system, the HVESS ...";
CM_ SG_ 2364743934 HighestCellTempModuleNum "Identifies the location of the module containing SPN 17146 (HVESP24 Highest Cell Temperature).
This parameter is for one of multiple packs in an HVESS. If there is only one pack in the system, the HVESS parameters should be used. If there are ...";
CM_ BO_ 2364743678 "High Voltage Energy Storage Pack 24 Data 8
Data set 8 (electrical data) for High Voltage Energy Storage Pack 24.";
CM_ SG_ 2364743678 AvgCellV "The average cell voltage in this High Voltage Energy Storage Pack instance.
This parameter is for one of multiple packs in an HVESS.  If there is only one pack in the system, the HVESS parameters should be used. If there are multiple packs in the ...";
CM_ SG_ 2364743678 LowestCellVCellNum "Identifies the location of SPN 17144 (HVESP24 Lowest Cell Voltage) within SPN 17225 (HVESP24 Lowest Cell Voltage Module Number).
This parameter is for one of multiple packs in an HVESS. If there is only one pack in the system, the HVESS parameters ...";
CM_ SG_ 2364743678 LowestCellVModuleNum "Identifies the location of the module containing SPN 17144 (HVESP24 Lowest Cell Voltage).
This parameter is for one of multiple packs in an HVESS. If there is only one pack in the system, the HVESS parameters should be used. If there are multiple ...";
CM_ SG_ 2364743678 HighestCellVCellNum "Identifies the location of SPN 17143 (HVESP24 Highest Cell Voltage) within SPN 17223 (HVESP24 Highest Cell Voltage Module Number).
This parameter is for one of multiple packs in an HVESS. If there is only one pack in the system, the HVESS ...";
CM_ SG_ 2364743678 HighestCellVModuleNum "Identifies the location of the module containing SPN 17143 (HVESP24 Highest Cell Voltage).
This parameter is for one of multiple packs in an HVESS. If there is only one pack in the system, the HVESS parameters should be used. If there are multiple ...";
CM_ BO_ 2364743422 "High Voltage Energy Storage Pack 24 Thermal Management System Status 1
Collection of data the High Voltage Energy Storage Pack 24 Thermal Management System sends to the Hybrid Controller.";
CM_ SG_ 2364743422 TMSCoolantLvl "Indicates the coolant level in this HVES Thermal Management System (TMS).
This parameter is for one of multiple packs in an HVESS.  If there is only one pack in the system, the HVESS parameters should be used. If there are multiple packs in the ...";
CM_ SG_ 2364743422 TMSMode "Indicates the operating mode of the Thermal Management System.  The heat transfer medium may be (e.g. liquid or air).  The cooling system may be fans, liquid coolant, or a combination of mediums.  The system may include an air and/or liquid ...";
CM_ SG_ 2364743422 TMSHVILStatus "In multiple HVES configurations, this is the status of the High Voltage Interlock Loop from the viewpoint of this Thermal Management System.
00b = HVIL Closed
01b = HVIL Open
10b = Error
11b = Not Available
This parameter is for one of multiple ...";
CM_ SG_ 2364743422 TMSHtrStatus "The state of this High Voltage Energy Storage Pack heater
This parameter is for one of multiple packs in an HVESS.  If there is only one pack in the system, the HVESS parameters should be used. If there are multiple packs in the system, then both ...";
CM_ SG_ 2364743422 TMSRelHumidty "When this High Voltage Energy Storage Pack Thermal Management System is equipped with a relative humidity sensor, this is the  measured Relative Humidity.
This parameter is for one of multiple packs in an HVESS.  If there is only one pack in the ...";
CM_ SG_ 2364743422 TMSCompressorSpd "When this High Voltage Energy Storage Pack Thermal Management System is equipped with an active cooling system (e.g. air conditioner), this is the Compressor Speed.
This parameter is for one of multiple packs in an HVESS.  If there is only one pack ...";
CM_ SG_ 2364743422 TMSHVInputPwr "This is the high-voltage power consumed by this HVES Thermal Management System (TMS).
This parameter is for one of multiple packs in an HVESS.  If there is only one pack in the system, the HVESS parameters should be used. If there are multiple ...";
CM_ SG_ 2364743422 TMSSLIInputPwr "This is the low-voltage power consumed by this HVES Thermal Management System (TMS).
This parameter is for one of multiple packs in an HVESS.  If there is only one pack in the system, the HVESS parameters should be used.  If there are multiple ...";
CM_ BO_ 2364743166 "High Voltage Energy Storage Pack 24 Module Status 1
Module Status message 1 for High Voltage Energy Storage Pack 24.";
CM_ SG_ 2364743166 Module32OperationalStatus "Operational Status of Module 32 in this High Voltage Energy Storage Pack Instance.  Not Operational is used when the module is initializing or not able to function (e.g. internal module level monitors have failed).  Operational indicates that the ...";
CM_ SG_ 2364743166 Module31OperationalStatus "Operational Status of Module 31 in this High Voltage Energy Storage Pack Instance.  Not Operational is used when the module is initializing or not able to function (e.g. internal module level monitors have failed).  Operational indicates that the ...";
CM_ SG_ 2364743166 Module30OperationalStatus "Operational Status of Module 30 in this High Voltage Energy Storage Pack Instance.  Not Operational is used when the module is initializing or not able to function (e.g. internal module level monitors have failed).  Operational indicates that the ...";
CM_ SG_ 2364743166 Module29OperationalStatus "Operational Status of Module 29 in this High Voltage Energy Storage Pack Instance.  Not Operational is used when the module is initializing or not able to function (e.g. internal module level monitors have failed).  Operational indicates that the ...";
CM_ SG_ 2364743166 Module28OperationalStatus "Operational Status of Module 28 in this High Voltage Energy Storage Pack Instance.  Not Operational is used when the module is initializing or not able to function (e.g. internal module level monitors have failed).  Operational indicates that the ...";
CM_ SG_ 2364743166 Module27OperationalStatus "Operational Status of Module 27 in this High Voltage Energy Storage Pack Instance.  Not Operational is used when the module is initializing or not able to function (e.g. internal module level monitors have failed).  Operational indicates that the ...";
CM_ SG_ 2364743166 Module26OperationalStatus "Operational Status of Module 26 in this High Voltage Energy Storage Pack Instance.  Not Operational is used when the module is initializing or not able to function (e.g. internal module level monitors have failed).  Operational indicates that the ...";
CM_ SG_ 2364743166 Module25OperationalStatus "Operational Status of Module 25 in this High Voltage Energy Storage Pack Instance.  Not Operational is used when the module is initializing or not able to function (e.g. internal module level monitors have failed).  Operational indicates that the ...";
CM_ SG_ 2364743166 Module24OperationalStatus "Operational Status of Module 24 in this High Voltage Energy Storage Pack Instance.  Not Operational is used when the module is initializing or not able to function (e.g. internal module level monitors have failed).  Operational indicates that the ...";
CM_ SG_ 2364743166 Module23OperationalStatus "Operational Status of Module 23 in this High Voltage Energy Storage Pack Instance.  Not Operational is used when the module is initializing or not able to function (e.g. internal module level monitors have failed).  Operational indicates that the ...";
CM_ SG_ 2364743166 Module22OperationalStatus "Operational Status of Module 22 in this High Voltage Energy Storage Pack Instance.  Not Operational is used when the module is initializing or not able to function (e.g. internal module level monitors have failed).  Operational indicates that the ...";
CM_ SG_ 2364743166 Module21OperationalStatus "Operational Status of Module 21 in this High Voltage Energy Storage Pack Instance.  Not Operational is used when the module is initializing or not able to function (e.g. internal module level monitors have failed).  Operational indicates that the ...";
CM_ SG_ 2364743166 Module20OperationalStatus "Operational Status of Module 20 in this High Voltage Energy Storage Pack Instance.  Not Operational is used when the module is initializing or not able to function (e.g. internal module level monitors have failed).  Operational indicates that the ...";
CM_ SG_ 2364743166 Module19OperationalStatus "Operational Status of Module 19 in this High Voltage Energy Storage Pack Instance.  Not Operational is used when the module is initializing or not able to function (e.g. internal module level monitors have failed).  Operational indicates that the ...";
CM_ SG_ 2364743166 Module18OperationalStatus "Operational Status of Module 18 in this High Voltage Energy Storage Pack Instance.  Not Operational is used when the module is initializing or not able to function (e.g. internal module level monitors have failed).  Operational indicates that the ...";
CM_ SG_ 2364743166 Module17OperationalStatus "Operational Status of Module 17 in this High Voltage Energy Storage Pack Instance.  Not Operational is used when the module is initializing or not able to function (e.g. internal module level monitors have failed).  Operational indicates that the ...";
CM_ SG_ 2364743166 Module16OperationalStatus "Operational Status of Module 16 in this High Voltage Energy Storage Pack Instance.  Not Operational is used when the module is initializing or not able to function (e.g. internal module level monitors have failed).  Operational indicates that the ...";
CM_ SG_ 2364743166 Module15OperationalStatus "Operational Status of Module 15 in this High Voltage Energy Storage Pack Instance.  Not Operational is used when the module is initializing or not able to function (e.g. internal module level monitors have failed).  Operational indicates that the ...";
CM_ SG_ 2364743166 Module14OperationalStatus "Operational Status of Module 14 in this High Voltage Energy Storage Pack Instance.  Not Operational is used when the module is initializing or not able to function (e.g. internal module level monitors have failed).  Operational indicates that the ...";
CM_ SG_ 2364743166 Module13OperationalStatus "Operational Status of Module 13 in this High Voltage Energy Storage Pack Instance.  Not Operational is used when the module is initializing or not able to function (e.g. internal module level monitors have failed).  Operational indicates that the ...";
CM_ SG_ 2364743166 Module12OperationalStatus "Operational Status of Module 12 in this High Voltage Energy Storage Pack Instance.  Not Operational is used when the module is initializing or not able to function (e.g. internal module level monitors have failed).  Operational indicates that the ...";
CM_ SG_ 2364743166 Module11OperationalStatus "Operational Status of Module 11 in this High Voltage Energy Storage Pack Instance.  Not Operational is used when the module is initializing or not able to function (e.g. internal module level monitors have failed).  Operational indicates that the ...";
CM_ SG_ 2364743166 Module10OperationalStatus "Operational Status of Module 10 in this High Voltage Energy Storage Pack Instance.  Not Operational is used when the module is initializing or not able to function (e.g. internal module level monitors have failed).  Operational indicates that the ...";
CM_ SG_ 2364743166 Module9OperationalStatus "Operational Status of Module 9 in this High Voltage Energy Storage Pack Instance.  Not Operational is used when the module is initializing or not able to function (e.g. internal module level monitors have failed).  Operational indicates that the ...";
CM_ SG_ 2364743166 Module8OperationalStatus "Operational Status of Module 8 in this High Voltage Energy Storage Pack Instance.  Not Operational is used when the module is initializing or not able to function (e.g. internal module level monitors have failed).  Operational indicates that the ...";
CM_ SG_ 2364743166 Module7OperationalStatus "Operational Status of Module 7 in this High Voltage Energy Storage Pack Instance.  Not Operational is used when the module is initializing or not able to function (e.g. internal module level monitors have failed).  Operational indicates that the ...";
CM_ SG_ 2364743166 Module6OperationalStatus "Operational Status of Module 6 in this High Voltage Energy Storage Pack Instance.  Not Operational is used when the module is initializing or not able to function (e.g. internal module level monitors have failed).  Operational indicates that the ...";
CM_ SG_ 2364743166 Module5OperationalStatus "Operational Status of Module 5 in this High Voltage Energy Storage Pack Instance.  Not Operational is used when the module is initializing or not able to function (e.g. internal module level monitors have failed).  Operational indicates that the ...";
CM_ SG_ 2364743166 Module4OperationalStatus "Operational Status of Module 4 in this High Voltage Energy Storage Pack Instance.  Not Operational is used when the module is initializing or not able to function (e.g. internal module level monitors have failed).  Operational indicates that the ...";
CM_ SG_ 2364743166 Module3OperationalStatus "Operational Status of Module 3 in this High Voltage Energy Storage Pack Instance.  Not Operational is used when the module is initializing or not able to function (e.g. internal module level monitors have failed).  Operational indicates that the ...";
CM_ SG_ 2364743166 Module2OperationalStatus "Operational Status of Module 2 in this High Voltage Energy Storage Pack Instance.  Not Operational is used when the module is initializing or not able to function (e.g. internal module level monitors have failed).  Operational indicates that the ...";
CM_ SG_ 2364743166 Module1OperationalStatus "Operational Status of Module 1 in this High Voltage Energy Storage Pack Instance.  Not Operational is used when the module is initializing or not able to function (e.g. internal module level monitors have failed).  Operational indicates that the ...";
CM_ BO_ 2364742910 "High Voltage Energy Storage Pack 24 Data 7
Data set 7 (electrical) for High Voltage Energy Storage Pack 24.";
CM_ SG_ 2364742910 MaxChargeVLmt "The maximum voltage level not to be exceeded while charging this High Voltage Energy Storage Pack instance. If this parameter is not supported, the maximum charge voltage should be limited to SPN 17249 (HVESP24 Recommended Maximum Operating ...";
CM_ SG_ 2364742910 ChargeEnergyCapacity "The amount of unused electrical energy storage available to be filled by charging this High Voltage Energy Storage Pack instance, i.e. “how much empty space is remaining in the tank”. See SPN 17151 (HVESP24 Charge Capacity) for Ampere-hours (Ah).
 ...";
CM_ SG_ 2364742910 DisEnergyCapacity "The amount of stored electrical energy in this High Voltage Energy Storage Pack instance that is available for use by the hybrid system, i.e. “how full is the tank”. See SPN 17150 (HVESP24 Discharge Capacity) for Ampere-hours (Ah).
This parameter ...";
CM_ BO_ 2364742654 "High Voltage Energy Storage Pack 24 Status 1
Status data set 1 for High Voltage Energy Storage Pack 24.";
CM_ SG_ 2364742654 Status1CRC "The CRC is defined as follows:
• Length: 8 bits
• Polynomial: x^8+x^5+x^3+x^2+x+1
• Initial Value: FFh
• Input Data Reflection: Not reflected
• Result Data Reflection: Not reflected
• XOR value: FFh
SAE makes no claim of the functional safety ...";
CM_ SG_ 2364742654 Status1Counter "The message counter is used to detect situations where the transmitting ECU malfunction repeats the same frame all the time. The receiver of the information may use the counter parameter to detect this situation. The transmitting device will ...";
CM_ SG_ 2364742654 OperationalStatus "Provides feedback on where this High Voltage Energy Storage Pack instance is in its operating spectrum, and includes feedback in response to the Operation Consent [i.e. SPN 17121 (HVESP24 Operation Consent)] and Power Down Command [i.e. SPN 17116 ...";
CM_ SG_ 2364742654 HVBusConnectionStatus "This parameter provides high level feedback on this High Voltage Energy Storage Pack instance high voltage bus connection. For specific contactor information, see SPN 17163 (HVESP24 High-Voltage Bus (Positive) Contactor State), SPN 17164 (HVESP24 ...";
CM_ SG_ 2364742654 InternalChargerStatus "Indicates that the charger in this HVES instance is on.  External chargers may use the External Energy Source Connection Status (SPN 7898) and related SPs.
This parameter is for one of multiple packs in an HVESS. If there is only one pack in the ...";
CM_ SG_ 2364742654 CellBalancingActive "Indicates whether or not the cells in this High Voltage Energy Storage Pack instance are currently being balanced.
This parameter is for one of multiple packs in an HVESS.  If there is only one pack in the system, the HVESS parameters should be ...";
CM_ SG_ 2364742654 CellBalanceStatus "Indicates whether or not the cells in this High Voltage Energy Storage Pack instance are balanced.
This parameter is for one of multiple packs in an HVESS.  If there is only one pack in the system, the HVESS parameters should be used. If there are ...";
CM_ SG_ 2364742654 StOfChargeStatus "Status of this High Voltage Energy Storage Pack instance State of Charge (SOC).  Note:  A given HVES controller may not support all of the states.
This parameter is for one of multiple packs in an HVESS.  If there is only one pack in the system, ...";
CM_ SG_ 2364742654 InertiaSwStatus "Switch indicating that an impact has been sensed by this High Voltage Energy Storage Pack instance. The impact indication may require action by another controller, or by this HVES instance itself.  For example, a controller may elect to take this ...";
CM_ SG_ 2364742654 HVILStatus "Status of the High Voltage Interlock Loop from the viewpoint of this High Voltage Energy Storage Pack instance.
This parameter is for one of multiple packs in an HVESS. If there is only one pack in the system, the HVESS parameters should be used ...";
CM_ SG_ 2364742654 HVBusPassiveIsolTestStatus "Status of the high-voltage bus electrical passive isolation test as performed by this High Voltage Energy Storage Pack instance.
This parameter is for one of multiple packs in an HVESS. If there is only one pack in the system, the HVESS parameters ...";
CM_ SG_ 2364742654 HVBusActiveIsolTestStatus "Status of the high-voltage bus electrical active isolation test as performed by this High Voltage Energy Storage Pack instance.
This parameter is for one of multiple packs in an HVESS. If there is only one pack in the system, the HVESS parameters ...";
CM_ SG_ 2364742654 CenterOfPackContactorSt "Position of the center high-voltage contactor. When this contactor is closed, the positive half of this High Voltage Energy Storage Pack instance is connected to the negative half. If a system controls the positive, negative, and center contactors ...";
CM_ SG_ 2364742654 HVBusPreChargeRelaySt "Position of the high-voltage bus contactor pre-charge relay.  When this relay is closed, this High Voltage Energy Storage Pack instance is bringing the high-voltage bus up to its operating level.
This parameter is for one of multiple packs in an ...";
CM_ SG_ 2364742654 HVBusDisconnectForewarning "Indicates that this High Voltage Energy Storage Pack instance is about to disconnect from the high voltage bus due to unacceptable conditions.
This parameter is for one of multiple packs in an HVESS. If there is only one pack in the system, the ...";
CM_ SG_ 2364742654 HVBusContactorSt17164 "Position of this High Voltage Energy Storage Pack instance negative side bus contactor. When this contactor is closed, the negative side of this HVES instance is connected to the negative side of the high-voltage bus. If a system controls the ...";
CM_ SG_ 2364742654 HVBusContactorSt "Position of this High Voltage Energy Storage Pack instance positive side bus contactor.  When this contactor is closed, the positive side of this HVES instance is connected to the positive side of the high-voltage bus.  In systems where all ...";
CM_ BO_ 2364742398 "High Voltage Energy Storage Pack 24 Data 6
Data set 6 (external or interface data) for High Voltage Energy Storage Pack 24.";
CM_ SG_ 2364742398 Temp "The temperature of this High Voltage Energy Storage Pack instance. The value may be determined from a unique sensor specifically for this purpose, or by aggregating various temperature sensor readings within the pack.
This parameter is for one of ...";
CM_ SG_ 2364742398 ETemp "The temperature of the electronics or control modules in this High Voltage Energy Storage Pack instance.  If there are multiple temperature sensors then this parameter would be set to the maximum sensor reading.
This parameter is for one of ...";
CM_ SG_ 2364742398 OutCoolantTemp "The temperature of liquid coolant as it exits this High Voltage Energy Storage Pack instance.
This parameter is for one of multiple packs in an HVESS.  If there is only one pack in the system, the HVESS parameters should be used. If there are ...";
CM_ SG_ 2364742398 InCoolantTemp "The temperature of liquid coolant as it enters this High Voltage Energy Storage Pack instance.
This parameter is for one of multiple packs in an HVESS.  If there is only one pack in the system, the HVESS parameters should be used. If there are ...";
CM_ SG_ 2364742398 IgntV "The voltage level at the ignition input of this High Voltage Energy Storage Pack controller.
This parameter is for one of multiple packs in an HVESS.  If there is only one pack in the system, the HVESS parameters should be used.  If there are ...";
CM_ SG_ 2364742398 BusV "The voltage level of the high voltage bus, as measured by this High Voltage Energy Storage Pack instance on the bus side (not the battery side) of its contactors.
This parameter is for one of multiple packs in an HVESS.  If there is only one pack ...";
CM_ BO_ 2364742142 "High Voltage Energy Storage Pack 24 Data 5
Data set 5 (electrical data) for High Voltage Energy Storage Pack 24.";
CM_ SG_ 2364742142 HighestCellStOfCharge "Indicates the state of charge of the highest-charged cell in this High Voltage Energy Storage Pack instance. 0% means no charge remaining, 100% means the cell is fully charged. If a single state of charge value covers more than one cell, the value ...";
CM_ SG_ 2364742142 LowestCellStOfCharge "Indicates the state of charge of the lowest-charged cell in this High Voltage Energy Storage Pack instance. 0% means no charge remaining, 100% means the cell is fully charged. If a single state of charge value covers more than one cell, the value in ...";
CM_ SG_ 2364742142 ChargeCurLmt "The maximum instantaneous current flow limit into this High Voltage Energy Storage Pack instance. This parameter is defined from the high voltage energy storage pack's point of view and should reflect the instantaneous capability of the pack.  The ...";
CM_ SG_ 2364742142 DisCurLmt "The maximum instantaneous current flow limit out of this High Voltage Energy Storage Pack instance. This parameter is defined from the high voltage energy storage pack's point of view and should reflect the instantaneous capability of the pack.  The ...";
CM_ BO_ 2364741886 "High Voltage Energy Storage Pack 24 Data 4
Data set 4 (electrical data) for High Voltage Energy Storage Pack 24.";
CM_ SG_ 2364741886 CellBalancingCount "The number of cells that are currently being balanced in this High Voltage Energy Storage Pack instance.
This parameter is for one of multiple packs in an HVESS.  If there is only one pack in the system, the HVESS parameters should be used.  If ...";
CM_ SG_ 2364741886 ChargeCapacity "The amount of unused electrical charge storage in this High Voltage Energy Storage Pack instance that is available to be filled by charging, i.e. “how much empty space is remaining in the tank”. See SPN 17181 (HVESP24 Charge Energy Capacity) for ...";
CM_ SG_ 2364741886 DisCapacity "The amount of stored electrical charge in this High Voltage Energy Storage Pack instance that is available for use by the hybrid system, i.e. “how full is the tank”. See SPN 17180 (HVESP24 Discharge Energy Capacity) for kilowatt-hours (kWh).
This ...";
CM_ BO_ 2364741630 "High Voltage Energy Storage Pack 24 Data 3
Data set 3 (thermal data) for High Voltage Energy Storage Pack 24.";
CM_ SG_ 2364741630 CellTempDiffStatus "Indicates whether or not the differential between the highest and lowest cell temperatures are within acceptable limits per this High Voltage Energy Storage Pack instance. The actual temperature differential can be calculated by subtracting SPN ...";
CM_ SG_ 2364741630 AvgCellTemp "The average temperature level of all cells in this High Voltage Energy Storage Pack instance.
This parameter is for one of multiple packs in an HVESS.  If there is only one pack in the system, the HVESS parameters should be used.  If there are ...";
CM_ SG_ 2364741630 LowestCellTemp "The lowest temperature level reported by any cell in this High Voltage Energy Storage Pack instance. If a single temperature sensor covers more than one cell, the value in this parameter is for the smallest group of cells measured. See SPN 17230 ...";
CM_ SG_ 2364741630 HighestCellTemp "The highest temperature level reported by any cell in this High Voltage Energy Storage Pack instance. If a single temperature sensor covers more than one cell, the value in this parameter is for the smallest group of cells measured. See SPN 17228 ...";
CM_ BO_ 2364741374 "High Voltage Energy Storage Pack 24 Data 2
Data set 2 (electrical data) for High Voltage Energy Storage Pack 24.";
CM_ SG_ 2364741374 CellVDiffStatus "Indicates whether or not the differential between the highest and lowest cell voltages are within acceptable limits, according to this High Voltage Energy Storage Pack instance. The actual voltage differential can be calculated by subtracting SPN ...";
CM_ SG_ 2364741374 LowestCellV "The lowest voltage level reported by any cell in this High Voltage Energy Storage Pack instance. If a single voltage sensor covers more than one cell, the value in this parameter is for the smallest group of cells measured. See SPN 17225 (HVESP24 ...";
CM_ SG_ 2364741374 HighestCellV "The highest voltage level reported by any cell in this High Voltage Energy Storage Pack instance. If a single voltage sensor covers more than one cell, the value in this parameter is for the smallest group of cells measured. See SPN 17223 (HVESP24 ...";
CM_ SG_ 2364741374 FastUpdateStOfCharge "Indicates this High Voltage Energy Storage Pack instance state of charge. 0% means no charge remaining, 100% means the system is fully charged in terms of physical limits of this energy storage pack instance. Acceptable state of charge upper and ...";
CM_ BO_ 2364741118 "High Voltage Energy Storage Pack 24 Data 1
Data set 1 (electrical data) for High Voltage Energy Storage Pack 24.";
CM_ SG_ 2364741118 Cur "The current in or out of this High Voltage Energy Storage Pack instance. This parameter should be synchronized with SPN 17140 (HVESP24 Voltage Level) such that a realized power value can be calculated. This parameter is defined from the high voltage ...";
CM_ SG_ 2364741118 Lvl "The voltage level of this High Voltage Energy Storage Pack instance. This parameter should be synchronized with SPN 17141 (HVESP24 Current) such that a realized power value can be calculated. If the HVES component physically contains the contactors ...";
CM_ SG_ 2364741118 AvailableChargePwr "The rate at which this High Voltage Energy Storage Pack instance can currently receive energy from a regenerative or recharging system.
This parameter is for one of multiple packs in an HVESS.  If there is only one pack in the system, the HVESS ...";
CM_ SG_ 2364741118 AvailableDisPwr "The rate at which this High Voltage Energy Storage Pack instance can currently provide energy for propulsion or other uses.
This parameter is for one of multiple packs in an HVESS.  If there is only one pack in the system, the HVESS parameters ...";
CM_ BO_ 2364740862 "High Voltage Energy Storage Pack 24 Status 2
Status data set 2 for High Voltage Energy Storage Pack 24.";
CM_ SG_ 2364740862 ChargePLDueToAnUndefinedCause "Indicates whether or not charge power of this HVES instance is being limited due to an undefined cause.
This parameter is for one of multiple packs in an HVESS.  If there is only one pack in the system, the HVESS parameters should be used. If there ...";
CM_ SG_ 2364740862 ChargePLDueToBatCur "Indicates whether or not charge power of this HVES instance is being limited due to battery current.
This parameter is for one of multiple packs in an HVESS.  If there is only one pack in the system, the HVESS parameters should be used. If there ...";
CM_ SG_ 2364740862 ChargePLDueToBatOrCellV "Indicates whether or not charge power of this HVES instance is being limited due to a battery or cell voltage level.
This parameter is for one of multiple packs in an HVESS.  If there is only one pack in the system, the HVESS parameters should be ...";
CM_ SG_ 2364740862 ChargePLDueToBatDiagCondition "Indicates whether or not charge power of this HVES instance is being limited due to a battery diagnostic condition.
This parameter is for one of multiple packs in an HVESS.  If there is only one pack in the system, the HVESS parameters should be ...";
CM_ SG_ 2364740862 ChargePLDueToBatTemp "Indicates whether or not charge power of this HVES instance is being limited due to battery temperature.
This parameter is for one of multiple packs in an HVESS.  If there is only one pack in the system, the HVESS parameters should be used. If ...";
CM_ SG_ 2364740862 ChargePLDueToStOfCharge "Indicates whether or not charge power of this HVES instance is being limited due to state of charge.
This parameter is for one of multiple packs in an HVESS.  If there is only one pack in the system, the HVESS parameters should be used. If there ...";
CM_ SG_ 2364740862 DisPLDueToAnUndefinedCause "Indicates whether or not discharge power of this HVES instance is being limited due to an undefined cause.
This parameter is for one of multiple packs in an HVESS.  If there is only one pack in the system, the HVESS parameters should be used. If ...";
CM_ SG_ 2364740862 DisPLDueToBatCur "Indicates whether or not discharge power of this HVES instance is being limited due to battery current.
This parameter is for one of multiple packs in an HVESS.  If there is only one pack in the system, the HVESS parameters should be used. If there ...";
CM_ SG_ 2364740862 DisPLDueToBatOrCellV "Indicates whether or not discharge power of this HVES instance is being limited due to a battery or cell voltage level.
This parameter is for one of multiple packs in an HVESS.  If there is only one pack in the system, the HVESS parameters should ...";
CM_ SG_ 2364740862 DisPLDueToBatDiagCondition "Indicates whether or not discharge power of this HVES instance is being limited due to a battery diagnostic condition.
This parameter is for one of multiple packs in an HVESS.  If there is only one pack in the system, the HVESS parameters should be ...";
CM_ SG_ 2364740862 DisPLDueToBatTemp "Indicates whether or not discharge power of this HVES instance is being limited due to battery temperature.
This parameter is for one of multiple packs in an HVESS.  If there is only one pack in the system, the HVESS parameters should be used. If ...";
CM_ SG_ 2364740862 DisPLDueToStOfCharge "Indicates whether or not discharge power of this HVES instance is being limited due to state of charge.
This parameter is for one of multiple packs in an HVESS.  If there is only one pack in the system, the HVESS parameters should be used. If there ...";
CM_ BO_ 2364740606 "High Voltage Energy Storage Pack 23 Data 11
Data set 11 (electrical data) for High Voltage Energy Storage Pack 23.";
CM_ SG_ 2364740606 ActualChargeRate "This signal represents the actual present charge rate of this High Voltage Energy Storage Pack instance.
This parameter is for one of multiple packs in an HVESS. If there is only one pack in the system, the HVESS parameters should be used. If there ...";
CM_ SG_ 2364740606 LvlNegToChassisGroundV "Voltage difference between the most negative terminal of the HVES battery and chassis measured at the battery side of any HVES contained output contactor.  This voltage may be used for system level monitoring of battery shorts to chassis within the ...";
CM_ SG_ 2364740606 BusVNegToChassisGroundV "Voltage difference between the most negative terminal of the HVES battery and chassis measured on the hybrid system bus side (not the battery side) of any HVES contained output contactor.  This voltage may be used for system level monitoring of ...";
CM_ BO_ 2364740350 "High Voltage Energy Storage Pack 23 Data 10
Data set 10 (electrical) for High Voltage Energy Storage Pack 23.";
CM_ SG_ 2364740350 HVBusPassiveIsolTestResults "The isolation resistance expressed in Ohms per Volt that resulted from the High-Voltage Bus Passive Isolation Test.
See SPN 17027 (HVESP23 High-Voltage Bus Passive Isolation Test Status) for test status and SPN 16976 (HVESP23 High-Voltage Bus ...";
CM_ SG_ 2364740350 HVBusActiveIsolTestResults "The isolation resistance expressed in Ohms per Volt that resulted from the High-Voltage Bus Active Isolation Test.
See SPN 17026 (HVESP23 High-Voltage Bus Active Isolation Test Status) for test status and SPN 16975 (HVESP23 High-Voltage Bus Active ...";
CM_ SG_ 2364740350 LowestCellStOfChargeCellNum "Identifies the location of SPN 17013 (HVESP23 Lowest Cell State of Charge) within SPN 17092 (HVESP23 Lowest Cell State of Charge Module Number).
This parameter is for one of multiple packs in an HVESS. If there is only one pack in the system, the ...";
CM_ SG_ 2364740350 LowestCellStOfChargeModuleNum "Identifies the location of the module containing SPN 17013 (HVESP23 Lowest Cell State of Charge).
This parameter is for one of multiple packs in an HVESS. If there is only one pack in the system, the HVESS parameters should be used. If there are ...";
CM_ SG_ 2364740350 HighestCellStOfChargeCellNum "Identifies the location of SPN 17014 (HVESP23 Highest Cell State of Charge) within SPN 17090 (HVESP23 Highest Cell State of Charge Module Number).
This parameter is for one of multiple packs in an HVESS. If there is only one pack in the system, the ...";
CM_ SG_ 2364740350 HighestCellStOfChargeModuleNum "Identifies the location of the module containing SPN 17014 (HVESP23 Highest Cell State of Charge).
This parameter is for one of multiple packs in an HVESS. If there is only one pack in the system, the HVESS parameters should be used. If there are ...";
CM_ BO_ 2364740094 "High Voltage Energy Storage Pack 23 Data 9
Data set 9 (thermal) for High Voltage Energy Storage Pack 23.";
CM_ SG_ 2364740094 Data9CRC "The CRC is defined as follows:
• Length: 8 bits
• Polynomial: x^8+x^5+x^3+x^2+x+1
• Initial Value: FFh
• Input Data Reflection: Not reflected
• Result Data Reflection: Not reflected
• XOR value: FFh
SAE makes no claim of the functional safety ...";
CM_ SG_ 2364740094 Data9Counter "The message counter is used to detect situations where the transmitting ECU malfunction repeats the same frame all the time. The receiver of the information may use the counter parameter to detect this situation. The transmitting device will ...";
CM_ SG_ 2364740094 Data9EmbeddedIntegritySupport "Indicates SPN 23042 (HVESP23 Data 9 CRC) and SPN 23041 (HVESP23 Data 9 Counter) are supported by the sender.
00b = Embedded CRC and Counter are supported by the sender
01b = Protection is supported using J1939-76 SHM
10b = Reserved
11b = CRC and ...";
CM_ SG_ 2364740094 HVESS23ThermalEventDetected "A sensor has detected the presence of a thermal event at or near High Voltage Energy Storage Pack instance.
00b = No Thermal Event Detected
01b = Thermal Event Detected
10b = Error
11b = Not available
This parameter is for one of multiple packs ...";
CM_ SG_ 2364740094 LowestCellTempCellNum "Identifies the location of SPN 17005 (HVESP23 Lowest Cell Temperature) within SPN 17088 (HVESP23 Lowest Cell Temperature Module Number).
This parameter is for one of multiple packs in an HVESS. If there is only one pack in the system, the HVESS ...";
CM_ SG_ 2364740094 LowestCellTempModuleNum "Identifies the location of the module containing SPN 17005 (HVESP23 Lowest Cell Temperature).
This parameter is for one of multiple packs in an HVESS. If there is only one pack in the system, the HVESS parameters should be used. If there are ...";
CM_ SG_ 2364740094 HighestCellTempCellNum "Identifies the location of SPN 17004 (HVESP23 Highest Cell Temperature) within SPN 17086 (HVESP23 Highest Cell Temperature Module Number).
This parameter is for one of multiple packs in an HVESS. If there is only one pack in the system, the HVESS ...";
CM_ SG_ 2364740094 HighestCellTempModuleNum "Identifies the location of the module containing SPN 17004 (HVESP23 Highest Cell Temperature).
This parameter is for one of multiple packs in an HVESS. If there is only one pack in the system, the HVESS parameters should be used. If there are ...";
CM_ BO_ 2364739838 "High Voltage Energy Storage Pack 23 Data 8
Data set 8 (electrical data) for High Voltage Energy Storage Pack 23.";
CM_ SG_ 2364739838 AvgCellV "The average cell voltage in this High Voltage Energy Storage Pack instance.
This parameter is for one of multiple packs in an HVESS.  If there is only one pack in the system, the HVESS parameters should be used. If there are multiple packs in the ...";
CM_ SG_ 2364739838 LowestCellVCellNum "Identifies the location of SPN 17002 (HVESP23 Lowest Cell Voltage) within SPN 17083 (HVESP23 Lowest Cell Voltage Module Number).
This parameter is for one of multiple packs in an HVESS. If there is only one pack in the system, the HVESS parameters ...";
CM_ SG_ 2364739838 LowestCellVModuleNum "Identifies the location of the module containing SPN 17002 (HVESP23 Lowest Cell Voltage).
This parameter is for one of multiple packs in an HVESS. If there is only one pack in the system, the HVESS parameters should be used. If there are multiple ...";
CM_ SG_ 2364739838 HighestCellVCellNum "Identifies the location of SPN 17001 (HVESP23 Highest Cell Voltage) within SPN 17081 (HVESP23 Highest Cell Voltage Module Number).
This parameter is for one of multiple packs in an HVESS. If there is only one pack in the system, the HVESS ...";
CM_ SG_ 2364739838 HighestCellVModuleNum "Identifies the location of the module containing SPN 17001 (HVESP23 Highest Cell Voltage).
This parameter is for one of multiple packs in an HVESS. If there is only one pack in the system, the HVESS parameters should be used. If there are multiple ...";
CM_ BO_ 2364739582 "High Voltage Energy Storage Pack 23 Thermal Management System Status 1
Collection of data the High Voltage Energy Storage Pack 23 Thermal Management System sends to the Hybrid Controller.";
CM_ SG_ 2364739582 TMSCoolantLvl "Indicates the coolant level in this HVES Thermal Management System (TMS).
This parameter is for one of multiple packs in an HVESS.  If there is only one pack in the system, the HVESS parameters should be used. If there are multiple packs in the ...";
CM_ SG_ 2364739582 TMSMode "Indicates the operating mode of the Thermal Management System.  The heat transfer medium may be (e.g. liquid or air).  The cooling system may be fans, liquid coolant, or a combination of mediums.  The system may include an air and/or liquid ...";
CM_ SG_ 2364739582 TMSHVILStatus "In multiple HVES configurations, this is the status of the High Voltage Interlock Loop from the viewpoint of this Thermal Management System.
00b = HVIL Closed
01b = HVIL Open
10b = Error
11b = Not Available
This parameter is for one of multiple ...";
CM_ SG_ 2364739582 TMSHtrStatus "The state of this High Voltage Energy Storage Pack heater
This parameter is for one of multiple packs in an HVESS.  If there is only one pack in the system, the HVESS parameters should be used. If there are multiple packs in the system, then both ...";
CM_ SG_ 2364739582 TMSRelHumidty "When this High Voltage Energy Storage Pack Thermal Management System is equipped with a relative humidity sensor, this is the  measured Relative Humidity.
This parameter is for one of multiple packs in an HVESS.  If there is only one pack in the ...";
CM_ SG_ 2364739582 TMSCompressorSpd "When this High Voltage Energy Storage Pack Thermal Management System is equipped with an active cooling system (e.g. air conditioner), this is the Compressor Speed.
This parameter is for one of multiple packs in an HVESS.  If there is only one pack ...";
CM_ SG_ 2364739582 TMSHVInputPwr "This is the high-voltage power consumed by this HVES Thermal Management System (TMS).
This parameter is for one of multiple packs in an HVESS.  If there is only one pack in the system, the HVESS parameters should be used. If there are multiple ...";
CM_ SG_ 2364739582 TMSSLIInputPwr "This is the low-voltage power consumed by this HVES Thermal Management System (TMS).
This parameter is for one of multiple packs in an HVESS.  If there is only one pack in the system, the HVESS parameters should be used.  If there are multiple ...";
CM_ BO_ 2364739326 "High Voltage Energy Storage Pack 23 Module Status 1
Module Status message 1 for High Voltage Energy Storage Pack 23.";
CM_ SG_ 2364739326 Module32OperationalStatus "Operational Status of Module 32 in this High Voltage Energy Storage Pack Instance.  Not Operational is used when the module is initializing or not able to function (e.g. internal module level monitors have failed).  Operational indicates that the ...";
CM_ SG_ 2364739326 Module31OperationalStatus "Operational Status of Module 31 in this High Voltage Energy Storage Pack Instance.  Not Operational is used when the module is initializing or not able to function (e.g. internal module level monitors have failed).  Operational indicates that the ...";
CM_ SG_ 2364739326 Module30OperationalStatus "Operational Status of Module 30 in this High Voltage Energy Storage Pack Instance.  Not Operational is used when the module is initializing or not able to function (e.g. internal module level monitors have failed).  Operational indicates that the ...";
CM_ SG_ 2364739326 Module29OperationalStatus "Operational Status of Module 29 in this High Voltage Energy Storage Pack Instance.  Not Operational is used when the module is initializing or not able to function (e.g. internal module level monitors have failed).  Operational indicates that the ...";
CM_ SG_ 2364739326 Module28OperationalStatus "Operational Status of Module 28 in this High Voltage Energy Storage Pack Instance.  Not Operational is used when the module is initializing or not able to function (e.g. internal module level monitors have failed).  Operational indicates that the ...";
CM_ SG_ 2364739326 Module27OperationalStatus "Operational Status of Module 27 in this High Voltage Energy Storage Pack Instance.  Not Operational is used when the module is initializing or not able to function (e.g. internal module level monitors have failed).  Operational indicates that the ...";
CM_ SG_ 2364739326 Module26OperationalStatus "Operational Status of Module 26 in this High Voltage Energy Storage Pack Instance.  Not Operational is used when the module is initializing or not able to function (e.g. internal module level monitors have failed).  Operational indicates that the ...";
CM_ SG_ 2364739326 Module25OperationalStatus "Operational Status of Module 25 in this High Voltage Energy Storage Pack Instance.  Not Operational is used when the module is initializing or not able to function (e.g. internal module level monitors have failed).  Operational indicates that the ...";
CM_ SG_ 2364739326 Module24OperationalStatus "Operational Status of Module 24 in this High Voltage Energy Storage Pack Instance.  Not Operational is used when the module is initializing or not able to function (e.g. internal module level monitors have failed).  Operational indicates that the ...";
CM_ SG_ 2364739326 Module23OperationalStatus "Operational Status of Module 23 in this High Voltage Energy Storage Pack Instance.  Not Operational is used when the module is initializing or not able to function (e.g. internal module level monitors have failed).  Operational indicates that the ...";
CM_ SG_ 2364739326 Module22OperationalStatus "Operational Status of Module 22 in this High Voltage Energy Storage Pack Instance.  Not Operational is used when the module is initializing or not able to function (e.g. internal module level monitors have failed).  Operational indicates that the ...";
CM_ SG_ 2364739326 Module21OperationalStatus "Operational Status of Module 21 in this High Voltage Energy Storage Pack Instance.  Not Operational is used when the module is initializing or not able to function (e.g. internal module level monitors have failed).  Operational indicates that the ...";
CM_ SG_ 2364739326 Module20OperationalStatus "Operational Status of Module 20 in this High Voltage Energy Storage Pack Instance.  Not Operational is used when the module is initializing or not able to function (e.g. internal module level monitors have failed).  Operational indicates that the ...";
CM_ SG_ 2364739326 Module19OperationalStatus "Operational Status of Module 19 in this High Voltage Energy Storage Pack Instance.  Not Operational is used when the module is initializing or not able to function (e.g. internal module level monitors have failed).  Operational indicates that the ...";
CM_ SG_ 2364739326 Module18OperationalStatus "Operational Status of Module 18 in this High Voltage Energy Storage Pack Instance.  Not Operational is used when the module is initializing or not able to function (e.g. internal module level monitors have failed).  Operational indicates that the ...";
CM_ SG_ 2364739326 Module17OperationalStatus "Operational Status of Module 17 in this High Voltage Energy Storage Pack Instance.  Not Operational is used when the module is initializing or not able to function (e.g. internal module level monitors have failed).  Operational indicates that the ...";
CM_ SG_ 2364739326 Module16OperationalStatus "Operational Status of Module 16 in this High Voltage Energy Storage Pack Instance.  Not Operational is used when the module is initializing or not able to function (e.g. internal module level monitors have failed).  Operational indicates that the ...";
CM_ SG_ 2364739326 Module15OperationalStatus "Operational Status of Module 15 in this High Voltage Energy Storage Pack Instance.  Not Operational is used when the module is initializing or not able to function (e.g. internal module level monitors have failed).  Operational indicates that the ...";
CM_ SG_ 2364739326 Module14OperationalStatus "Operational Status of Module 14 in this High Voltage Energy Storage Pack Instance.  Not Operational is used when the module is initializing or not able to function (e.g. internal module level monitors have failed).  Operational indicates that the ...";
CM_ SG_ 2364739326 Module13OperationalStatus "Operational Status of Module 13 in this High Voltage Energy Storage Pack Instance.  Not Operational is used when the module is initializing or not able to function (e.g. internal module level monitors have failed).  Operational indicates that the ...";
CM_ SG_ 2364739326 Module12OperationalStatus "Operational Status of Module 12 in this High Voltage Energy Storage Pack Instance.  Not Operational is used when the module is initializing or not able to function (e.g. internal module level monitors have failed).  Operational indicates that the ...";
CM_ SG_ 2364739326 Module11OperationalStatus "Operational Status of Module 11 in this High Voltage Energy Storage Pack Instance.  Not Operational is used when the module is initializing or not able to function (e.g. internal module level monitors have failed).  Operational indicates that the ...";
CM_ SG_ 2364739326 Module10OperationalStatus "Operational Status of Module 10 in this High Voltage Energy Storage Pack Instance.  Not Operational is used when the module is initializing or not able to function (e.g. internal module level monitors have failed).  Operational indicates that the ...";
CM_ SG_ 2364739326 Module9OperationalStatus "Operational Status of Module 9 in this High Voltage Energy Storage Pack Instance.  Not Operational is used when the module is initializing or not able to function (e.g. internal module level monitors have failed).  Operational indicates that the ...";
CM_ SG_ 2364739326 Module8OperationalStatus "Operational Status of Module 8 in this High Voltage Energy Storage Pack Instance.  Not Operational is used when the module is initializing or not able to function (e.g. internal module level monitors have failed).  Operational indicates that the ...";
CM_ SG_ 2364739326 Module7OperationalStatus "Operational Status of Module 7 in this High Voltage Energy Storage Pack Instance.  Not Operational is used when the module is initializing or not able to function (e.g. internal module level monitors have failed).  Operational indicates that the ...";
CM_ SG_ 2364739326 Module6OperationalStatus "Operational Status of Module 6 in this High Voltage Energy Storage Pack Instance.  Not Operational is used when the module is initializing or not able to function (e.g. internal module level monitors have failed).  Operational indicates that the ...";
CM_ SG_ 2364739326 Module5OperationalStatus "Operational Status of Module 5 in this High Voltage Energy Storage Pack Instance.  Not Operational is used when the module is initializing or not able to function (e.g. internal module level monitors have failed).  Operational indicates that the ...";
CM_ SG_ 2364739326 Module4OperationalStatus "Operational Status of Module 4 in this High Voltage Energy Storage Pack Instance.  Not Operational is used when the module is initializing or not able to function (e.g. internal module level monitors have failed).  Operational indicates that the ...";
CM_ SG_ 2364739326 Module3OperationalStatus "Operational Status of Module 3 in this High Voltage Energy Storage Pack Instance.  Not Operational is used when the module is initializing or not able to function (e.g. internal module level monitors have failed).  Operational indicates that the ...";
CM_ SG_ 2364739326 Module2OperationalStatus "Operational Status of Module 2 in this High Voltage Energy Storage Pack Instance.  Not Operational is used when the module is initializing or not able to function (e.g. internal module level monitors have failed).  Operational indicates that the ...";
CM_ SG_ 2364739326 Module1OperationalStatus "Operational Status of Module 1 in this High Voltage Energy Storage Pack Instance.  Not Operational is used when the module is initializing or not able to function (e.g. internal module level monitors have failed).  Operational indicates that the ...";
CM_ BO_ 2364739070 "High Voltage Energy Storage Pack 23 Data 7
Data set 7 (electrical) for High Voltage Energy Storage Pack 23.";
CM_ SG_ 2364739070 MaxChargeVLmt "The maximum voltage level not to be exceeded while charging this High Voltage Energy Storage Pack instance. If this parameter is not supported, the maximum charge voltage should be limited to SPN 17107 (HVESP23 Recommended Maximum Operating ...";
CM_ SG_ 2364739070 ChargeEnergyCapacity "The amount of unused electrical energy storage available to be filled by charging this High Voltage Energy Storage Pack instance, i.e. “how much empty space is remaining in the tank”. See SPN 17009 (HVESP23 Charge Capacity) for Ampere-hours (Ah).
 ...";
CM_ SG_ 2364739070 DisEnergyCapacity "The amount of stored electrical energy in this High Voltage Energy Storage Pack instance that is available for use by the hybrid system, i.e. “how full is the tank”. See SPN 17008 (HVESP23 Discharge Capacity) for Ampere-hours (Ah).
This parameter ...";
CM_ BO_ 2364738814 "High Voltage Energy Storage Pack 23 Status 1
Status data set 1 for High Voltage Energy Storage Pack 23.";
CM_ SG_ 2364738814 Status1CRC "The CRC is defined as follows:
• Length: 8 bits
• Polynomial: x^8+x^5+x^3+x^2+x+1
• Initial Value: FFh
• Input Data Reflection: Not reflected
• Result Data Reflection: Not reflected
• XOR value: FFh
SAE makes no claim of the functional safety ...";
CM_ SG_ 2364738814 Status1Counter "The message counter is used to detect situations where the transmitting ECU malfunction repeats the same frame all the time. The receiver of the information may use the counter parameter to detect this situation. The transmitting device will ...";
CM_ SG_ 2364738814 OperationalStatus "Provides feedback on where this High Voltage Energy Storage Pack instance is in its operating spectrum, and includes feedback in response to the Operation Consent [i.e. SPN 16979 (HVESP23 Operation Consent)] and Power Down Command [i.e. SPN 16974 ...";
CM_ SG_ 2364738814 HVBusConnectionStatus "This parameter provides high level feedback on this High Voltage Energy Storage Pack instance high voltage bus connection. For specific contactor information, see SPN 17021 (HVESP23 High-Voltage Bus (Positive) Contactor State), SPN 17022 (HVESP23 ...";
CM_ SG_ 2364738814 InternalChargerStatus "Indicates that the charger in this HVES instance is on.  External chargers may use the External Energy Source Connection Status (SPN 7898) and related SPs.
This parameter is for one of multiple packs in an HVESS. If there is only one pack in the ...";
CM_ SG_ 2364738814 CellBalancingActive "Indicates whether or not the cells in this High Voltage Energy Storage Pack instance are currently being balanced.
This parameter is for one of multiple packs in an HVESS.  If there is only one pack in the system, the HVESS parameters should be ...";
CM_ SG_ 2364738814 CellBalanceStatus "Indicates whether or not the cells in this High Voltage Energy Storage Pack instance are balanced.
This parameter is for one of multiple packs in an HVESS.  If there is only one pack in the system, the HVESS parameters should be used. If there are ...";
CM_ SG_ 2364738814 StOfChargeStatus "Status of this High Voltage Energy Storage Pack instance State of Charge (SOC).  Note:  A given HVES controller may not support all of the states.
This parameter is for one of multiple packs in an HVESS.  If there is only one pack in the system, ...";
CM_ SG_ 2364738814 InertiaSwStatus "Switch indicating that an impact has been sensed by this High Voltage Energy Storage Pack instance. The impact indication may require action by another controller, or by this HVES instance itself.  For example, a controller may elect to take this ...";
CM_ SG_ 2364738814 HVILStatus "Status of the High Voltage Interlock Loop from the viewpoint of this High Voltage Energy Storage Pack instance.
This parameter is for one of multiple packs in an HVESS. If there is only one pack in the system, the HVESS parameters should be used ...";
CM_ SG_ 2364738814 HVBusPassiveIsolTestStatus "Status of the high-voltage bus electrical passive isolation test as performed by this High Voltage Energy Storage Pack instance.
This parameter is for one of multiple packs in an HVESS. If there is only one pack in the system, the HVESS parameters ...";
CM_ SG_ 2364738814 HVBusActiveIsolTestStatus "Status of the high-voltage bus electrical active isolation test as performed by this High Voltage Energy Storage Pack instance.
This parameter is for one of multiple packs in an HVESS. If there is only one pack in the system, the HVESS parameters ...";
CM_ SG_ 2364738814 CenterOfPackContactorSt "Position of the center high-voltage contactor. When this contactor is closed, the positive half of this High Voltage Energy Storage Pack instance is connected to the negative half. If a system controls the positive, negative, and center contactors ...";
CM_ SG_ 2364738814 HVBusPreChargeRelaySt "Position of the high-voltage bus contactor pre-charge relay.  When this relay is closed, this High Voltage Energy Storage Pack instance is bringing the high-voltage bus up to its operating level.
This parameter is for one of multiple packs in an ...";
CM_ SG_ 2364738814 HVBusDisconnectForewarning "Indicates that this High Voltage Energy Storage Pack instance is about to disconnect from the high voltage bus due to unacceptable conditions.
This parameter is for one of multiple packs in an HVESS. If there is only one pack in the system, the ...";
CM_ SG_ 2364738814 HVBusContactorSt17022 "Position of this High Voltage Energy Storage Pack instance negative side bus contactor. When this contactor is closed, the negative side of this HVES instance is connected to the negative side of the high-voltage bus. If a system controls the ...";
CM_ SG_ 2364738814 HVBusContactorSt "Position of this High Voltage Energy Storage Pack instance positive side bus contactor.  When this contactor is closed, the positive side of this HVES instance is connected to the positive side of the high-voltage bus.  In systems where all ...";
CM_ BO_ 2364738558 "High Voltage Energy Storage Pack 23 Data 6
Data set 6 (external or interface data) for High Voltage Energy Storage Pack 23.";
CM_ SG_ 2364738558 Temp "The temperature of this High Voltage Energy Storage Pack instance. The value may be determined from a unique sensor specifically for this purpose, or by aggregating various temperature sensor readings within the pack.
This parameter is for one of ...";
CM_ SG_ 2364738558 ETemp "The temperature of the electronics or control modules in this High Voltage Energy Storage Pack instance.  If there are multiple temperature sensors then this parameter would be set to the maximum sensor reading.
This parameter is for one of ...";
CM_ SG_ 2364738558 OutCoolantTemp "The temperature of liquid coolant as it exits this High Voltage Energy Storage Pack instance.
This parameter is for one of multiple packs in an HVESS.  If there is only one pack in the system, the HVESS parameters should be used. If there are ...";
CM_ SG_ 2364738558 InCoolantTemp "The temperature of liquid coolant as it enters this High Voltage Energy Storage Pack instance.
This parameter is for one of multiple packs in an HVESS.  If there is only one pack in the system, the HVESS parameters should be used. If there are ...";
CM_ SG_ 2364738558 IgntV "The voltage level at the ignition input of this High Voltage Energy Storage Pack controller.
This parameter is for one of multiple packs in an HVESS.  If there is only one pack in the system, the HVESS parameters should be used.  If there are ...";
CM_ SG_ 2364738558 BusV "The voltage level of the high voltage bus, as measured by this High Voltage Energy Storage Pack instance on the bus side (not the battery side) of its contactors.
This parameter is for one of multiple packs in an HVESS.  If there is only one pack ...";
CM_ BO_ 2364738302 "High Voltage Energy Storage Pack 23 Data 5
Data set 5 (electrical data) for High Voltage Energy Storage Pack 23.";
CM_ SG_ 2364738302 HighestCellStOfCharge "Indicates the state of charge of the highest-charged cell in this High Voltage Energy Storage Pack instance. 0% means no charge remaining, 100% means the cell is fully charged. If a single state of charge value covers more than one cell, the value ...";
CM_ SG_ 2364738302 LowestCellStOfCharge "Indicates the state of charge of the lowest-charged cell in this High Voltage Energy Storage Pack instance. 0% means no charge remaining, 100% means the cell is fully charged. If a single state of charge value covers more than one cell, the value in ...";
CM_ SG_ 2364738302 ChargeCurLmt "The maximum instantaneous current flow limit into this High Voltage Energy Storage Pack instance. This parameter is defined from the high voltage energy storage pack's point of view and should reflect the instantaneous capability of the pack.  The ...";
CM_ SG_ 2364738302 DisCurLmt "The maximum instantaneous current flow limit out of this High Voltage Energy Storage Pack instance. This parameter is defined from the high voltage energy storage pack's point of view and should reflect the instantaneous capability of the pack.  The ...";
CM_ BO_ 2364738046 "High Voltage Energy Storage Pack 23 Data 4
Data set 4 (electrical data) for High Voltage Energy Storage Pack 23.";
CM_ SG_ 2364738046 CellBalancingCount "The number of cells that are currently being balanced in this High Voltage Energy Storage Pack instance.
This parameter is for one of multiple packs in an HVESS.  If there is only one pack in the system, the HVESS parameters should be used.  If ...";
CM_ SG_ 2364738046 ChargeCapacity "The amount of unused electrical charge storage in this High Voltage Energy Storage Pack instance that is available to be filled by charging, i.e. “how much empty space is remaining in the tank”. See SPN 17039 (HVESP23 Charge Energy Capacity) for ...";
CM_ SG_ 2364738046 DisCapacity "The amount of stored electrical charge in this High Voltage Energy Storage Pack instance that is available for use by the hybrid system, i.e. “how full is the tank”. See SPN 17038 (HVESP23 Discharge Energy Capacity) for kilowatt-hours (kWh).
This ...";
CM_ BO_ 2364737790 "High Voltage Energy Storage Pack 23 Data 3
Data set 3 (thermal data) for High Voltage Energy Storage Pack 23.";
CM_ SG_ 2364737790 CellTempDiffStatus "Indicates whether or not the differential between the highest and lowest cell temperatures are within acceptable limits per this High Voltage Energy Storage Pack instance. The actual temperature differential can be calculated by subtracting SPN ...";
CM_ SG_ 2364737790 AvgCellTemp "The average temperature level of all cells in this High Voltage Energy Storage Pack instance.
This parameter is for one of multiple packs in an HVESS.  If there is only one pack in the system, the HVESS parameters should be used.  If there are ...";
CM_ SG_ 2364737790 LowestCellTemp "The lowest temperature level reported by any cell in this High Voltage Energy Storage Pack instance. If a single temperature sensor covers more than one cell, the value in this parameter is for the smallest group of cells measured. See SPN 17088 ...";
CM_ SG_ 2364737790 HighestCellTemp "The highest temperature level reported by any cell in this High Voltage Energy Storage Pack instance. If a single temperature sensor covers more than one cell, the value in this parameter is for the smallest group of cells measured. See SPN 17086 ...";
CM_ BO_ 2364737534 "High Voltage Energy Storage Pack 23 Data 2
Data set 2 (electrical data) for High Voltage Energy Storage Pack 23.";
CM_ SG_ 2364737534 CellVDiffStatus "Indicates whether or not the differential between the highest and lowest cell voltages are within acceptable limits, according to this High Voltage Energy Storage Pack instance. The actual voltage differential can be calculated by subtracting SPN ...";
CM_ SG_ 2364737534 LowestCellV "The lowest voltage level reported by any cell in this High Voltage Energy Storage Pack instance. If a single voltage sensor covers more than one cell, the value in this parameter is for the smallest group of cells measured. See SPN 17083 (HVESP23 ...";
CM_ SG_ 2364737534 HighestCellV "The highest voltage level reported by any cell in this High Voltage Energy Storage Pack instance. If a single voltage sensor covers more than one cell, the value in this parameter is for the smallest group of cells measured. See SPN 17081 (HVESP23 ...";
CM_ SG_ 2364737534 FastUpdateStOfCharge "Indicates this High Voltage Energy Storage Pack instance state of charge. 0% means no charge remaining, 100% means the system is fully charged in terms of physical limits of this energy storage pack instance. Acceptable state of charge upper and ...";
CM_ BO_ 2364737278 "High Voltage Energy Storage Pack 23 Data 1
Data set 1 (electrical data) for High Voltage Energy Storage Pack 23.";
CM_ SG_ 2364737278 Cur "The current in or out of this High Voltage Energy Storage Pack instance. This parameter should be synchronized with SPN 16998 (HVESP23 Voltage Level) such that a realized power value can be calculated. This parameter is defined from the high voltage ...";
CM_ SG_ 2364737278 Lvl "The voltage level of this High Voltage Energy Storage Pack instance. This parameter should be synchronized with SPN 16999 (HVESP23 Current) such that a realized power value can be calculated. If the HVES component physically contains the contactors ...";
CM_ SG_ 2364737278 AvailableChargePwr "The rate at which this High Voltage Energy Storage Pack instance can currently receive energy from a regenerative or recharging system.
This parameter is for one of multiple packs in an HVESS.  If there is only one pack in the system, the HVESS ...";
CM_ SG_ 2364737278 AvailableDisPwr "The rate at which this High Voltage Energy Storage Pack instance can currently provide energy for propulsion or other uses.
This parameter is for one of multiple packs in an HVESS.  If there is only one pack in the system, the HVESS parameters ...";
CM_ BO_ 2364737022 "High Voltage Energy Storage Pack 23 Status 2
Status data set 2 for High Voltage Energy Storage Pack 23.";
CM_ SG_ 2364737022 ChargePLDueToAnUndefinedCause "Indicates whether or not charge power of this HVES instance is being limited due to an undefined cause.
This parameter is for one of multiple packs in an HVESS.  If there is only one pack in the system, the HVESS parameters should be used. If there ...";
CM_ SG_ 2364737022 ChargePLDueToBatCur "Indicates whether or not charge power of this HVES instance is being limited due to battery current.
This parameter is for one of multiple packs in an HVESS.  If there is only one pack in the system, the HVESS parameters should be used. If there ...";
CM_ SG_ 2364737022 ChargePLDueToBatOrCellV "Indicates whether or not charge power of this HVES instance is being limited due to a battery or cell voltage level.
This parameter is for one of multiple packs in an HVESS.  If there is only one pack in the system, the HVESS parameters should be ...";
CM_ SG_ 2364737022 ChargePLDueToBatDiagCondition "Indicates whether or not charge power of this HVES instance is being limited due to a battery diagnostic condition.
This parameter is for one of multiple packs in an HVESS.  If there is only one pack in the system, the HVESS parameters should be ...";
CM_ SG_ 2364737022 ChargePLDueToBatTemp "Indicates whether or not charge power of this HVES instance is being limited due to battery temperature.
This parameter is for one of multiple packs in an HVESS.  If there is only one pack in the system, the HVESS parameters should be used. If ...";
CM_ SG_ 2364737022 ChargePLDueToStOfCharge "Indicates whether or not charge power of this HVES instance is being limited due to state of charge.
This parameter is for one of multiple packs in an HVESS.  If there is only one pack in the system, the HVESS parameters should be used. If there ...";
CM_ SG_ 2364737022 DisPLDueToAnUndefinedCause "Indicates whether or not discharge power of this HVES instance is being limited due to an undefined cause.
This parameter is for one of multiple packs in an HVESS.  If there is only one pack in the system, the HVESS parameters should be used. If ...";
CM_ SG_ 2364737022 DisPLDueToBatCur "Indicates whether or not discharge power of this HVES instance is being limited due to battery current.
This parameter is for one of multiple packs in an HVESS.  If there is only one pack in the system, the HVESS parameters should be used. If there ...";
CM_ SG_ 2364737022 DisPLDueToBatOrCellV "Indicates whether or not discharge power of this HVES instance is being limited due to a battery or cell voltage level.
This parameter is for one of multiple packs in an HVESS.  If there is only one pack in the system, the HVESS parameters should ...";
CM_ SG_ 2364737022 DisPLDueToBatDiagCondition "Indicates whether or not discharge power of this HVES instance is being limited due to a battery diagnostic condition.
This parameter is for one of multiple packs in an HVESS.  If there is only one pack in the system, the HVESS parameters should be ...";
CM_ SG_ 2364737022 DisPLDueToBatTemp "Indicates whether or not discharge power of this HVES instance is being limited due to battery temperature.
This parameter is for one of multiple packs in an HVESS.  If there is only one pack in the system, the HVESS parameters should be used. If ...";
CM_ SG_ 2364737022 DisPLDueToStOfCharge "Indicates whether or not discharge power of this HVES instance is being limited due to state of charge.
This parameter is for one of multiple packs in an HVESS.  If there is only one pack in the system, the HVESS parameters should be used. If there ...";
CM_ BO_ 2364736766 "High Voltage Energy Storage Pack 22 Data 11
Data set 11 (electrical data) for High Voltage Energy Storage Pack 22.";
CM_ SG_ 2364736766 ActualChargeRate "This signal represents the actual present charge rate of this High Voltage Energy Storage Pack instance.
This parameter is for one of multiple packs in an HVESS. If there is only one pack in the system, the HVESS parameters should be used. If there ...";
CM_ SG_ 2364736766 LvlNegToChassisGroundV "Voltage difference between the most negative terminal of the HVES battery and chassis measured at the battery side of any HVES contained output contactor.  This voltage may be used for system level monitoring of battery shorts to chassis within the ...";
CM_ SG_ 2364736766 BusVNegToChassisGroundV "Voltage difference between the most negative terminal of the HVES battery and chassis measured on the hybrid system bus side (not the battery side) of any HVES contained output contactor.  This voltage may be used for system level monitoring of ...";
CM_ BO_ 2364736510 "High Voltage Energy Storage Pack 22 Data 10
Data set 10 (electrical) for High Voltage Energy Storage Pack 22.";
CM_ SG_ 2364736510 HVBusPassiveIsolTestResults "The isolation resistance expressed in Ohms per Volt that resulted from the High-Voltage Bus Passive Isolation Test.
See SPN 16885 (HVESP22 High-Voltage Bus Passive Isolation Test Status) for test status and SPN 16834 (HVESP22 High-Voltage Bus ...";
CM_ SG_ 2364736510 HVBusActiveIsolTestResults "The isolation resistance expressed in Ohms per Volt that resulted from the High-Voltage Bus Active Isolation Test.
See SPN 16884 (HVESP22 High-Voltage Bus Active Isolation Test Status) for test status and SPN 16833 (HVESP22 High-Voltage Bus Active ...";
CM_ SG_ 2364736510 LowestCellStOfChargeCellNum "Identifies the location of SPN 16871 (HVESP22 Lowest Cell State of Charge) within SPN 16950 (HVESP22 Lowest Cell State of Charge Module Number).
This parameter is for one of multiple packs in an HVESS. If there is only one pack in the system, the ...";
CM_ SG_ 2364736510 LowestCellStOfChargeModuleNum "Identifies the location of the module containing SPN 16871 (HVESP22 Lowest Cell State of Charge).
This parameter is for one of multiple packs in an HVESS. If there is only one pack in the system, the HVESS parameters should be used. If there are ...";
CM_ SG_ 2364736510 HighestCellStOfChargeCellNum "Identifies the location of SPN 16872 (HVESP22 Highest Cell State of Charge) within SPN 16948 (HVESP22 Highest Cell State of Charge Module Number).
This parameter is for one of multiple packs in an HVESS. If there is only one pack in the system, the ...";
CM_ SG_ 2364736510 HighestCellStOfChargeModuleNum "Identifies the location of the module containing SPN 16872 (HVESP22 Highest Cell State of Charge).
This parameter is for one of multiple packs in an HVESS. If there is only one pack in the system, the HVESS parameters should be used. If there are ...";
CM_ BO_ 2364736254 "High Voltage Energy Storage Pack 22 Data 9
Data set 9 (thermal) for High Voltage Energy Storage Pack 22.";
CM_ SG_ 2364736254 Data9CRC "The CRC is defined as follows:
• Length: 8 bits
• Polynomial: x^8+x^5+x^3+x^2+x+1
• Initial Value: FFh
• Input Data Reflection: Not reflected
• Result Data Reflection: Not reflected
• XOR value: FFh
SAE makes no claim of the functional safety ...";
CM_ SG_ 2364736254 Data9Counter "The message counter is used to detect situations where the transmitting ECU malfunction repeats the same frame all the time. The receiver of the information may use the counter parameter to detect this situation. The transmitting device will ...";
CM_ SG_ 2364736254 Data9EmbeddedIntegritySupport "Indicates SPN 23039 (HVESP22 Data 9 CRC) and SPN 23038 (HVESP22 Data 9 Counter) are supported by the sender.
00b = Embedded CRC and Counter are supported by the sender
01b = Protection is supported using J1939-76 SHM
10b = Reserved
11b = CRC and ...";
CM_ SG_ 2364736254 HVESS22ThermalEventDetected "A sensor has detected the presence of a thermal event at or near High Voltage Energy Storage Pack instance.
00b = No Thermal Event Detected
01b = Thermal Event Detected
10b = Error
11b = Not available
This parameter is for one of multiple packs ...";
CM_ SG_ 2364736254 LowestCellTempCellNum "Identifies the location of SPN 16863 (HVESP22 Lowest Cell Temperature) within SPN 16946 (HVESP22 Lowest Cell Temperature Module Number).
This parameter is for one of multiple packs in an HVESS. If there is only one pack in the system, the HVESS ...";
CM_ SG_ 2364736254 LowestCellTempModuleNum "Identifies the location of the module containing SPN 16863 (HVESP22 Lowest Cell Temperature).
This parameter is for one of multiple packs in an HVESS. If there is only one pack in the system, the HVESS parameters should be used. If there are ...";
CM_ SG_ 2364736254 HighestCellTempCellNum "Identifies the location of SPN 16862 (HVESP22 Highest Cell Temperature) within SPN 16944 (HVESP22 Highest Cell Temperature Module Number).
This parameter is for one of multiple packs in an HVESS. If there is only one pack in the system, the HVESS ...";
CM_ SG_ 2364736254 HighestCellTempModuleNum "Identifies the location of the module containing SPN 16862 (HVESP22 Highest Cell Temperature).
This parameter is for one of multiple packs in an HVESS. If there is only one pack in the system, the HVESS parameters should be used. If there are ...";
CM_ BO_ 2364735998 "High Voltage Energy Storage Pack 22 Data 8
Data set 8 (electrical data) for High Voltage Energy Storage Pack 22.";
CM_ SG_ 2364735998 AvgCellV "The average cell voltage in this High Voltage Energy Storage Pack instance.
This parameter is for one of multiple packs in an HVESS.  If there is only one pack in the system, the HVESS parameters should be used. If there are multiple packs in the ...";
CM_ SG_ 2364735998 LowestCellVCellNum "Identifies the location of SPN 16860 (HVESP22 Lowest Cell Voltage) within SPN 16941 (HVESP22 Lowest Cell Voltage Module Number).
This parameter is for one of multiple packs in an HVESS. If there is only one pack in the system, the HVESS parameters ...";
CM_ SG_ 2364735998 LowestCellVModuleNum "Identifies the location of the module containing SPN 16860 (HVESP22 Lowest Cell Voltage).
This parameter is for one of multiple packs in an HVESS. If there is only one pack in the system, the HVESS parameters should be used. If there are multiple ...";
CM_ SG_ 2364735998 HighestCellVCellNum "Identifies the location of SPN 16859 (HVESP22 Highest Cell Voltage) within SPN 16939 (HVESP22 Highest Cell Voltage Module Number).
This parameter is for one of multiple packs in an HVESS. If there is only one pack in the system, the HVESS ...";
CM_ SG_ 2364735998 HighestCellVModuleNum "Identifies the location of the module containing SPN 16859 (HVESP22 Highest Cell Voltage).
This parameter is for one of multiple packs in an HVESS. If there is only one pack in the system, the HVESS parameters should be used. If there are multiple ...";
CM_ BO_ 2364735742 "High Voltage Energy Storage Pack 22 Thermal Management System Status 1
Collection of data the High Voltage Energy Storage Pack 22 Thermal Management System sends to the Hybrid Controller.";
CM_ SG_ 2364735742 TMSCoolantLvl "Indicates the coolant level in this HVES Thermal Management System (TMS).
This parameter is for one of multiple packs in an HVESS.  If there is only one pack in the system, the HVESS parameters should be used. If there are multiple packs in the ...";
CM_ SG_ 2364735742 TMSMode "Indicates the operating mode of the Thermal Management System.  The heat transfer medium may be (e.g. liquid or air).  The cooling system may be fans, liquid coolant, or a combination of mediums.  The system may include an air and/or liquid ...";
CM_ SG_ 2364735742 TMSHVILStatus "In multiple HVES configurations, this is the status of the High Voltage Interlock Loop from the viewpoint of this Thermal Management System.
00b = HVIL Closed
01b = HVIL Open
10b = Error
11b = Not Available
This parameter is for one of multiple ...";
CM_ SG_ 2364735742 TMSHtrStatus "The state of this High Voltage Energy Storage Pack heater
This parameter is for one of multiple packs in an HVESS.  If there is only one pack in the system, the HVESS parameters should be used. If there are multiple packs in the system, then both ...";
CM_ SG_ 2364735742 TMSRelHumidty "When this High Voltage Energy Storage Pack Thermal Management System is equipped with a relative humidity sensor, this is the  measured Relative Humidity.
This parameter is for one of multiple packs in an HVESS.  If there is only one pack in the ...";
CM_ SG_ 2364735742 TMSCompressorSpd "When this High Voltage Energy Storage Pack Thermal Management System is equipped with an active cooling system (e.g. air conditioner), this is the Compressor Speed.
This parameter is for one of multiple packs in an HVESS.  If there is only one pack ...";
CM_ SG_ 2364735742 TMSHVInputPwr "This is the high-voltage power consumed by this HVES Thermal Management System (TMS).
This parameter is for one of multiple packs in an HVESS.  If there is only one pack in the system, the HVESS parameters should be used. If there are multiple ...";
CM_ SG_ 2364735742 TMSSLIInputPwr "This is the low-voltage power consumed by this HVES Thermal Management System (TMS).
This parameter is for one of multiple packs in an HVESS.  If there is only one pack in the system, the HVESS parameters should be used.  If there are multiple ...";
CM_ BO_ 2364735486 "High Voltage Energy Storage Pack 22 Module Status 1
Module Status message 1 for High Voltage Energy Storage Pack 22.";
CM_ SG_ 2364735486 Module32OperationalStatus "Operational Status of Module 32 in this High Voltage Energy Storage Pack Instance.  Not Operational is used when the module is initializing or not able to function (e.g. internal module level monitors have failed).  Operational indicates that the ...";
CM_ SG_ 2364735486 Module31OperationalStatus "Operational Status of Module 31 in this High Voltage Energy Storage Pack Instance.  Not Operational is used when the module is initializing or not able to function (e.g. internal module level monitors have failed).  Operational indicates that the ...";
CM_ SG_ 2364735486 Module30OperationalStatus "Operational Status of Module 30 in this High Voltage Energy Storage Pack Instance.  Not Operational is used when the module is initializing or not able to function (e.g. internal module level monitors have failed).  Operational indicates that the ...";
CM_ SG_ 2364735486 Module29OperationalStatus "Operational Status of Module 29 in this High Voltage Energy Storage Pack Instance.  Not Operational is used when the module is initializing or not able to function (e.g. internal module level monitors have failed).  Operational indicates that the ...";
CM_ SG_ 2364735486 Module28OperationalStatus "Operational Status of Module 28 in this High Voltage Energy Storage Pack Instance.  Not Operational is used when the module is initializing or not able to function (e.g. internal module level monitors have failed).  Operational indicates that the ...";
CM_ SG_ 2364735486 Module27OperationalStatus "Operational Status of Module 27 in this High Voltage Energy Storage Pack Instance.  Not Operational is used when the module is initializing or not able to function (e.g. internal module level monitors have failed).  Operational indicates that the ...";
CM_ SG_ 2364735486 Module26OperationalStatus "Operational Status of Module 26 in this High Voltage Energy Storage Pack Instance.  Not Operational is used when the module is initializing or not able to function (e.g. internal module level monitors have failed).  Operational indicates that the ...";
CM_ SG_ 2364735486 Module25OperationalStatus "Operational Status of Module 25 in this High Voltage Energy Storage Pack Instance.  Not Operational is used when the module is initializing or not able to function (e.g. internal module level monitors have failed).  Operational indicates that the ...";
CM_ SG_ 2364735486 Module24OperationalStatus "Operational Status of Module 24 in this High Voltage Energy Storage Pack Instance.  Not Operational is used when the module is initializing or not able to function (e.g. internal module level monitors have failed).  Operational indicates that the ...";
CM_ SG_ 2364735486 Module23OperationalStatus "Operational Status of Module 23 in this High Voltage Energy Storage Pack Instance.  Not Operational is used when the module is initializing or not able to function (e.g. internal module level monitors have failed).  Operational indicates that the ...";
CM_ SG_ 2364735486 Module22OperationalStatus "Operational Status of Module 22 in this High Voltage Energy Storage Pack Instance.  Not Operational is used when the module is initializing or not able to function (e.g. internal module level monitors have failed).  Operational indicates that the ...";
CM_ SG_ 2364735486 Module21OperationalStatus "Operational Status of Module 21 in this High Voltage Energy Storage Pack Instance.  Not Operational is used when the module is initializing or not able to function (e.g. internal module level monitors have failed).  Operational indicates that the ...";
CM_ SG_ 2364735486 Module20OperationalStatus "Operational Status of Module 20 in this High Voltage Energy Storage Pack Instance.  Not Operational is used when the module is initializing or not able to function (e.g. internal module level monitors have failed).  Operational indicates that the ...";
CM_ SG_ 2364735486 Module19OperationalStatus "Operational Status of Module 19 in this High Voltage Energy Storage Pack Instance.  Not Operational is used when the module is initializing or not able to function (e.g. internal module level monitors have failed).  Operational indicates that the ...";
CM_ SG_ 2364735486 Module18OperationalStatus "Operational Status of Module 18 in this High Voltage Energy Storage Pack Instance.  Not Operational is used when the module is initializing or not able to function (e.g. internal module level monitors have failed).  Operational indicates that the ...";
CM_ SG_ 2364735486 Module17OperationalStatus "Operational Status of Module 17 in this High Voltage Energy Storage Pack Instance.  Not Operational is used when the module is initializing or not able to function (e.g. internal module level monitors have failed).  Operational indicates that the ...";
CM_ SG_ 2364735486 Module16OperationalStatus "Operational Status of Module 16 in this High Voltage Energy Storage Pack Instance.  Not Operational is used when the module is initializing or not able to function (e.g. internal module level monitors have failed).  Operational indicates that the ...";
CM_ SG_ 2364735486 Module15OperationalStatus "Operational Status of Module 15 in this High Voltage Energy Storage Pack Instance.  Not Operational is used when the module is initializing or not able to function (e.g. internal module level monitors have failed).  Operational indicates that the ...";
CM_ SG_ 2364735486 Module14OperationalStatus "Operational Status of Module 14 in this High Voltage Energy Storage Pack Instance.  Not Operational is used when the module is initializing or not able to function (e.g. internal module level monitors have failed).  Operational indicates that the ...";
CM_ SG_ 2364735486 Module13OperationalStatus "Operational Status of Module 13 in this High Voltage Energy Storage Pack Instance.  Not Operational is used when the module is initializing or not able to function (e.g. internal module level monitors have failed).  Operational indicates that the ...";
CM_ SG_ 2364735486 Module12OperationalStatus "Operational Status of Module 12 in this High Voltage Energy Storage Pack Instance.  Not Operational is used when the module is initializing or not able to function (e.g. internal module level monitors have failed).  Operational indicates that the ...";
CM_ SG_ 2364735486 Module11OperationalStatus "Operational Status of Module 11 in this High Voltage Energy Storage Pack Instance.  Not Operational is used when the module is initializing or not able to function (e.g. internal module level monitors have failed).  Operational indicates that the ...";
CM_ SG_ 2364735486 Module10OperationalStatus "Operational Status of Module 10 in this High Voltage Energy Storage Pack Instance.  Not Operational is used when the module is initializing or not able to function (e.g. internal module level monitors have failed).  Operational indicates that the ...";
CM_ SG_ 2364735486 Module9OperationalStatus "Operational Status of Module 9 in this High Voltage Energy Storage Pack Instance.  Not Operational is used when the module is initializing or not able to function (e.g. internal module level monitors have failed).  Operational indicates that the ...";
CM_ SG_ 2364735486 Module8OperationalStatus "Operational Status of Module 8 in this High Voltage Energy Storage Pack Instance.  Not Operational is used when the module is initializing or not able to function (e.g. internal module level monitors have failed).  Operational indicates that the ...";
CM_ SG_ 2364735486 Module7OperationalStatus "Operational Status of Module 7 in this High Voltage Energy Storage Pack Instance.  Not Operational is used when the module is initializing or not able to function (e.g. internal module level monitors have failed).  Operational indicates that the ...";
CM_ SG_ 2364735486 Module6OperationalStatus "Operational Status of Module 6 in this High Voltage Energy Storage Pack Instance.  Not Operational is used when the module is initializing or not able to function (e.g. internal module level monitors have failed).  Operational indicates that the ...";
CM_ SG_ 2364735486 Module5OperationalStatus "Operational Status of Module 5 in this High Voltage Energy Storage Pack Instance.  Not Operational is used when the module is initializing or not able to function (e.g. internal module level monitors have failed).  Operational indicates that the ...";
CM_ SG_ 2364735486 Module4OperationalStatus "Operational Status of Module 4 in this High Voltage Energy Storage Pack Instance.  Not Operational is used when the module is initializing or not able to function (e.g. internal module level monitors have failed).  Operational indicates that the ...";
CM_ SG_ 2364735486 Module3OperationalStatus "Operational Status of Module 3 in this High Voltage Energy Storage Pack Instance.  Not Operational is used when the module is initializing or not able to function (e.g. internal module level monitors have failed).  Operational indicates that the ...";
CM_ SG_ 2364735486 Module2OperationalStatus "Operational Status of Module 2 in this High Voltage Energy Storage Pack Instance.  Not Operational is used when the module is initializing or not able to function (e.g. internal module level monitors have failed).  Operational indicates that the ...";
CM_ SG_ 2364735486 Module1OperationalStatus "Operational Status of Module 1 in this High Voltage Energy Storage Pack Instance.  Not Operational is used when the module is initializing or not able to function (e.g. internal module level monitors have failed).  Operational indicates that the ...";
CM_ BO_ 2364735230 "High Voltage Energy Storage Pack 22 Data 7
Data set 7 (electrical) for High Voltage Energy Storage Pack 22.";
CM_ SG_ 2364735230 MaxChargeVLmt "The maximum voltage level not to be exceeded while charging this High Voltage Energy Storage Pack instance. If this parameter is not supported, the maximum charge voltage should be limited to SPN 16965 (HVESP22 Recommended Maximum Operating ...";
CM_ SG_ 2364735230 ChargeEnergyCapacity "The amount of unused electrical energy storage available to be filled by charging this High Voltage Energy Storage Pack instance, i.e. “how much empty space is remaining in the tank”. See SPN 16867 (HVESP22 Charge Capacity) for Ampere-hours (Ah).
 ...";
CM_ SG_ 2364735230 DisEnergyCapacity "The amount of stored electrical energy in this High Voltage Energy Storage Pack instance that is available for use by the hybrid system, i.e. “how full is the tank”. See SPN 16866 (HVESP22 Discharge Capacity) for Ampere-hours (Ah).
This parameter ...";
CM_ BO_ 2364734974 "High Voltage Energy Storage Pack 22 Status 1
Status data set 1 for High Voltage Energy Storage Pack 22.";
CM_ SG_ 2364734974 Status1CRC "The CRC is defined as follows:
• Length: 8 bits
• Polynomial: x^8+x^5+x^3+x^2+x+1
• Initial Value: FFh
• Input Data Reflection: Not reflected
• Result Data Reflection: Not reflected
• XOR value: FFh
SAE makes no claim of the functional safety ...";
CM_ SG_ 2364734974 Status1Counter "The message counter is used to detect situations where the transmitting ECU malfunction repeats the same frame all the time. The receiver of the information may use the counter parameter to detect this situation. The transmitting device will ...";
CM_ SG_ 2364734974 OperationalStatus "Provides feedback on where this High Voltage Energy Storage Pack instance is in its operating spectrum, and includes feedback in response to the Operation Consent [i.e. SPN 16837 (HVESP22 Operation Consent)] and Power Down Command [i.e. SPN 16832 ...";
CM_ SG_ 2364734974 HVBusConnectionStatus "This parameter provides high level feedback on this High Voltage Energy Storage Pack instance high voltage bus connection. For specific contactor information, see SPN 16879 (HVESP22 High-Voltage Bus (Positive) Contactor State), SPN 16880 (HVESP22 ...";
CM_ SG_ 2364734974 InternalChargerStatus "Indicates that the charger in this HVES instance is on.  External chargers may use the External Energy Source Connection Status (SPN 7898) and related SPs.
This parameter is for one of multiple packs in an HVESS. If there is only one pack in the ...";
CM_ SG_ 2364734974 CellBalancingActive "Indicates whether or not the cells in this High Voltage Energy Storage Pack instance are currently being balanced.
This parameter is for one of multiple packs in an HVESS.  If there is only one pack in the system, the HVESS parameters should be ...";
CM_ SG_ 2364734974 CellBalanceStatus "Indicates whether or not the cells in this High Voltage Energy Storage Pack instance are balanced.
This parameter is for one of multiple packs in an HVESS.  If there is only one pack in the system, the HVESS parameters should be used. If there are ...";
CM_ SG_ 2364734974 StOfChargeStatus "Status of this High Voltage Energy Storage Pack instance State of Charge (SOC).  Note:  A given HVES controller may not support all of the states.
This parameter is for one of multiple packs in an HVESS.  If there is only one pack in the system, ...";
CM_ SG_ 2364734974 InertiaSwStatus "Switch indicating that an impact has been sensed by this High Voltage Energy Storage Pack instance. The impact indication may require action by another controller, or by this HVES instance itself.  For example, a controller may elect to take this ...";
CM_ SG_ 2364734974 HVILStatus "Status of the High Voltage Interlock Loop from the viewpoint of this High Voltage Energy Storage Pack instance.
This parameter is for one of multiple packs in an HVESS. If there is only one pack in the system, the HVESS parameters should be used ...";
CM_ SG_ 2364734974 HVBusPassiveIsolTestStatus "Status of the high-voltage bus electrical passive isolation test as performed by this High Voltage Energy Storage Pack instance.
This parameter is for one of multiple packs in an HVESS. If there is only one pack in the system, the HVESS parameters ...";
CM_ SG_ 2364734974 HVBusActiveIsolTestStatus "Status of the high-voltage bus electrical active isolation test as performed by this High Voltage Energy Storage Pack instance.
This parameter is for one of multiple packs in an HVESS. If there is only one pack in the system, the HVESS parameters ...";
CM_ SG_ 2364734974 CenterOfPackContactorSt "Position of the center high-voltage contactor. When this contactor is closed, the positive half of this High Voltage Energy Storage Pack instance is connected to the negative half. If a system controls the positive, negative, and center contactors ...";
CM_ SG_ 2364734974 HVBusPreChargeRelaySt "Position of the high-voltage bus contactor pre-charge relay.  When this relay is closed, this High Voltage Energy Storage Pack instance is bringing the high-voltage bus up to its operating level.
This parameter is for one of multiple packs in an ...";
CM_ SG_ 2364734974 HVBusDisconnectForewarning "Indicates that this High Voltage Energy Storage Pack instance is about to disconnect from the high voltage bus due to unacceptable conditions.
This parameter is for one of multiple packs in an HVESS. If there is only one pack in the system, the ...";
CM_ SG_ 2364734974 HVBusContactorSt16880 "Position of this High Voltage Energy Storage Pack instance negative side bus contactor. When this contactor is closed, the negative side of this HVES instance is connected to the negative side of the high-voltage bus. If a system controls the ...";
CM_ SG_ 2364734974 HVBusContactorSt "Position of this High Voltage Energy Storage Pack instance positive side bus contactor.  When this contactor is closed, the positive side of this HVES instance is connected to the positive side of the high-voltage bus.  In systems where all ...";
CM_ BO_ 2364734718 "High Voltage Energy Storage Pack 22 Data 6
Data set 6 (external or interface data) for High Voltage Energy Storage Pack 22.";
CM_ SG_ 2364734718 Temp "The temperature of this High Voltage Energy Storage Pack instance. The value may be determined from a unique sensor specifically for this purpose, or by aggregating various temperature sensor readings within the pack.
This parameter is for one of ...";
CM_ SG_ 2364734718 ETemp "The temperature of the electronics or control modules in this High Voltage Energy Storage Pack instance.  If there are multiple temperature sensors then this parameter would be set to the maximum sensor reading.
This parameter is for one of ...";
CM_ SG_ 2364734718 OutCoolantTemp "The temperature of liquid coolant as it exits this High Voltage Energy Storage Pack instance.
This parameter is for one of multiple packs in an HVESS.  If there is only one pack in the system, the HVESS parameters should be used. If there are ...";
CM_ SG_ 2364734718 InCoolantTemp "The temperature of liquid coolant as it enters this High Voltage Energy Storage Pack instance.
This parameter is for one of multiple packs in an HVESS.  If there is only one pack in the system, the HVESS parameters should be used. If there are ...";
CM_ SG_ 2364734718 IgntV "The voltage level at the ignition input of this High Voltage Energy Storage Pack controller.
This parameter is for one of multiple packs in an HVESS.  If there is only one pack in the system, the HVESS parameters should be used.  If there are ...";
CM_ SG_ 2364734718 BusV "The voltage level of the high voltage bus, as measured by this High Voltage Energy Storage Pack instance on the bus side (not the battery side) of its contactors.
This parameter is for one of multiple packs in an HVESS.  If there is only one pack ...";
CM_ BO_ 2364734462 "High Voltage Energy Storage Pack 22 Data 5
Data set 5 (electrical data) for High Voltage Energy Storage Pack 22.";
CM_ SG_ 2364734462 HighestCellStOfCharge "Indicates the state of charge of the highest-charged cell in this High Voltage Energy Storage Pack instance. 0% means no charge remaining, 100% means the cell is fully charged. If a single state of charge value covers more than one cell, the value ...";
CM_ SG_ 2364734462 LowestCellStOfCharge "Indicates the state of charge of the lowest-charged cell in this High Voltage Energy Storage Pack instance. 0% means no charge remaining, 100% means the cell is fully charged. If a single state of charge value covers more than one cell, the value in ...";
CM_ SG_ 2364734462 ChargeCurLmt "The maximum instantaneous current flow limit into this High Voltage Energy Storage Pack instance. This parameter is defined from the high voltage energy storage pack's point of view and should reflect the instantaneous capability of the pack.  The ...";
CM_ SG_ 2364734462 DisCurLmt "The maximum instantaneous current flow limit out of this High Voltage Energy Storage Pack instance. This parameter is defined from the high voltage energy storage pack's point of view and should reflect the instantaneous capability of the pack.  The ...";
CM_ BO_ 2364734206 "High Voltage Energy Storage Pack 22 Data 4
Data set 4 (electrical data) for High Voltage Energy Storage Pack 22.";
CM_ SG_ 2364734206 CellBalancingCount "The number of cells that are currently being balanced in this High Voltage Energy Storage Pack instance.
This parameter is for one of multiple packs in an HVESS.  If there is only one pack in the system, the HVESS parameters should be used.  If ...";
CM_ SG_ 2364734206 ChargeCapacity "The amount of unused electrical charge storage in this High Voltage Energy Storage Pack instance that is available to be filled by charging, i.e. “how much empty space is remaining in the tank”. See SPN 16897 (HVESP22 Charge Energy Capacity) for ...";
CM_ SG_ 2364734206 DisCapacity "The amount of stored electrical charge in this High Voltage Energy Storage Pack instance that is available for use by the hybrid system, i.e. “how full is the tank”. See SPN 16896 (HVESP22 Discharge Energy Capacity) for kilowatt-hours (kWh).
This ...";
CM_ BO_ 2364733950 "High Voltage Energy Storage Pack 22 Data 3
Data set 3 (thermal data) for High Voltage Energy Storage Pack 22.";
CM_ SG_ 2364733950 CellTempDiffStatus "Indicates whether or not the differential between the highest and lowest cell temperatures are within acceptable limits per this High Voltage Energy Storage Pack instance. The actual temperature differential can be calculated by subtracting SPN ...";
CM_ SG_ 2364733950 AvgCellTemp "The average temperature level of all cells in this High Voltage Energy Storage Pack instance.
This parameter is for one of multiple packs in an HVESS.  If there is only one pack in the system, the HVESS parameters should be used.  If there are ...";
CM_ SG_ 2364733950 LowestCellTemp "The lowest temperature level reported by any cell in this High Voltage Energy Storage Pack instance. If a single temperature sensor covers more than one cell, the value in this parameter is for the smallest group of cells measured. See SPN 16946 ...";
CM_ SG_ 2364733950 HighestCellTemp "The highest temperature level reported by any cell in this High Voltage Energy Storage Pack instance. If a single temperature sensor covers more than one cell, the value in this parameter is for the smallest group of cells measured. See SPN 16944 ...";
CM_ BO_ 2364733694 "High Voltage Energy Storage Pack 22 Data 2
Data set 2 (electrical data) for High Voltage Energy Storage Pack 22.";
CM_ SG_ 2364733694 CellVDiffStatus "Indicates whether or not the differential between the highest and lowest cell voltages are within acceptable limits, according to this High Voltage Energy Storage Pack instance. The actual voltage differential can be calculated by subtracting SPN ...";
CM_ SG_ 2364733694 LowestCellV "The lowest voltage level reported by any cell in this High Voltage Energy Storage Pack instance. If a single voltage sensor covers more than one cell, the value in this parameter is for the smallest group of cells measured. See SPN 16941 (HVESP22 ...";
CM_ SG_ 2364733694 HighestCellV "The highest voltage level reported by any cell in this High Voltage Energy Storage Pack instance. If a single voltage sensor covers more than one cell, the value in this parameter is for the smallest group of cells measured. See SPN 16939 (HVESP22 ...";
CM_ SG_ 2364733694 FastUpdateStOfCharge "Indicates this High Voltage Energy Storage Pack instance state of charge. 0% means no charge remaining, 100% means the system is fully charged in terms of physical limits of this energy storage pack instance. Acceptable state of charge upper and ...";
BA_DEF_ SG_  "GenSigInactiveValue" INT 0 0;
BA_DEF_ SG_  "SigType" ENUM  "Default","Range","RangeSigned","ASCII","Discrete","Control","ReferencePGN","DTC","StringDelimiter","StringLength","StringLengthControl","MessageCounter","MessageChecksum";
BA_DEF_ SG_  "GenSigStartValue" INT 0 2147483647;
BA_DEF_ SG_  "GenSigSendType" ENUM  "Cyclic","OnWrite","OnWriteWithRepetition","OnChange","OnChangeWithRepetition","IfActive","IfActiveWithRepetition","NoSigSendType";
BA_DEF_ SG_  "GenSigILSupport" ENUM  "No","Yes";
BA_DEF_ SG_  "SPN" INT 0 524287;
BA_DEF_ BO_  "J1939CPgSendTimeout" INT -1 3600000;
BA_DEF_ BO_  "J1939CPgTOS" INT 0 7;
BA_DEF_ BO_  "J1939PgAppearanceOnBus" ENUM  "Default","CAN_Extended","CANFD_Extended";
BA_DEF_ BO_  "FsJ1939UseCrcAndCounter" STRING ;
BA_DEF_ BO_  "TpJ1939VarDlc" ENUM  "No","Yes";
BA_DEF_ BO_  "GenMsgNrOfRepetition" INT 0 1000000;
BA_DEF_ BO_  "GenMsgCycleTimeFast" INT 0 3600000;
BA_DEF_ BO_  "GenMsgFastOnStart" INT 0 100000;
BA_DEF_ BO_  "GenMsgStartDelayTime" INT 0 100000;
BA_DEF_ BO_  "GenMsgILSupport" ENUM  "No","Yes";
BA_DEF_ BO_  "GenMsgDelayTime" INT 0 1000;
BA_DEF_ BO_  "GenMsgRequestable" INT 0 1;
BA_DEF_ BO_  "GenMsgSendType" ENUM  "cyclic","NotUsed","NotUsed","NotUsed","NotUsed","NotUsed","NotUsed","IfActive","noMsgSendType";
BA_DEF_ BO_  "VFrameFormat" ENUM  "StandardCAN","ExtendedCAN","reserved","J1939PG","reserved","reserved","reserved","reserved","reserved","reserved","reserved","reserved","reserved","reserved","StandardCAN_FD","ExtendedCAN_FD";
BA_DEF_ BO_  "SingleFrame" INT 0 1;
BA_DEF_ BO_  "GenMsgCycleTime" INT 0 3600000;
BA_DEF_ SG_  "SystemSignalLongSymbol" STRING ;
BA_DEF_DEF_  "GenSigInactiveValue" 0;
BA_DEF_DEF_  "SigType" "Default";
BA_DEF_DEF_  "GenSigStartValue" 0;
BA_DEF_DEF_  "GenSigSendType" "NoSigSendType";
BA_DEF_DEF_  "GenSigILSupport" "Yes";
BA_DEF_DEF_  "SPN" 0;
BA_DEF_DEF_  "J1939CPgSendTimeout" -1;
BA_DEF_DEF_  "J1939CPgTOS" 2;
BA_DEF_DEF_  "J1939PgAppearanceOnBus" "Default";
BA_DEF_DEF_  "FsJ1939UseCrcAndCounter" "";
BA_DEF_DEF_  "TpJ1939VarDlc" "No";
BA_DEF_DEF_  "GenMsgNrOfRepetition" 0;
BA_DEF_DEF_  "GenMsgCycleTimeFast" 0;
BA_DEF_DEF_  "GenMsgFastOnStart" 0;
BA_DEF_DEF_  "GenMsgStartDelayTime" 0;
BA_DEF_DEF_  "GenMsgILSupport" "Yes";
BA_DEF_DEF_  "GenMsgDelayTime" 0;
BA_DEF_DEF_  "GenMsgRequestable" 1;
BA_DEF_DEF_  "GenMsgSendType" "noMsgSendType";
BA_DEF_DEF_  "VFrameFormat" "J1939PG";
BA_DEF_DEF_  "SingleFrame" 1;
BA_DEF_DEF_  "GenMsgCycleTime" 0;
BA_DEF_DEF_  "SystemSignalLongSymbol" "";
BA_ "FsJ1939UseCrcAndCounter" BO_ 2364743934 "Aa";
BA_ "GenMsgSendType" BO_ 2364743934 0;
BA_ "GenMsgCycleTime" BO_ 2364743934 100;
BA_ "GenMsgSendType" BO_ 2364743678 0;
BA_ "GenMsgCycleTime" BO_ 2364743678 100;
BA_ "GenMsgSendType" BO_ 2364743422 0;
BA_ "GenMsgCycleTime" BO_ 2364743422 100;
BA_ "GenMsgSendType" BO_ 2364743166 0;
BA_ "GenMsgCycleTime" BO_ 2364743166 100;
BA_ "GenMsgSendType" BO_ 2364742910 0;
BA_ "GenMsgCycleTime" BO_ 2364742910 100;
BA_ "FsJ1939UseCrcAndCounter" BO_ 2364742654 "Aa";
BA_ "GenMsgDelayTime" BO_ 2364742654 20;
BA_ "GenMsgSendType" BO_ 2364742654 0;
BA_ "GenMsgCycleTime" BO_ 2364742654 100;
BA_ "GenMsgSendType" BO_ 2364742398 0;
BA_ "GenMsgCycleTime" BO_ 2364742398 100;
BA_ "GenMsgSendType" BO_ 2364742142 0;
BA_ "GenMsgCycleTime" BO_ 2364742142 20;
BA_ "GenMsgSendType" BO_ 2364741886 0;
BA_ "GenMsgCycleTime" BO_ 2364741886 100;
BA_ "GenMsgSendType" BO_ 2364741630 0;
BA_ "GenMsgCycleTime" BO_ 2364741630 20;
BA_ "GenMsgSendType" BO_ 2364741374 0;
BA_ "GenMsgCycleTime" BO_ 2364741374 20;
BA_ "GenMsgSendType" BO_ 2364741118 0;
BA_ "GenMsgCycleTime" BO_ 2364741118 20;
BA_ "GenMsgSendType" BO_ 2364740862 0;
BA_ "GenMsgCycleTime" BO_ 2364740862 100;
BA_ "GenMsgSendType" BO_ 2364740606 0;
BA_ "GenMsgCycleTime" BO_ 2364740606 100;
BA_ "GenMsgSendType" BO_ 2364740350 0;
BA_ "GenMsgCycleTime" BO_ 2364740350 100;
BA_ "FsJ1939UseCrcAndCounter" BO_ 2364740094 "Aa";
BA_ "GenMsgSendType" BO_ 2364740094 0;
BA_ "GenMsgCycleTime" BO_ 2364740094 100;
BA_ "GenMsgSendType" BO_ 2364739838 0;
BA_ "GenMsgCycleTime" BO_ 2364739838 100;
BA_ "GenMsgSendType" BO_ 2364739582 0;
BA_ "GenMsgCycleTime" BO_ 2364739582 100;
BA_ "GenMsgSendType" BO_ 2364739326 0;
BA_ "GenMsgCycleTime" BO_ 2364739326 100;
BA_ "GenMsgSendType" BO_ 2364739070 0;
BA_ "GenMsgCycleTime" BO_ 2364739070 100;
BA_ "FsJ1939UseCrcAndCounter" BO_ 2364738814 "Aa";
BA_ "GenMsgDelayTime" BO_ 2364738814 20;
BA_ "GenMsgSendType" BO_ 2364738814 0;
BA_ "GenMsgCycleTime" BO_ 2364738814 100;
BA_ "GenMsgSendType" BO_ 2364738558 0;
BA_ "GenMsgCycleTime" BO_ 2364738558 100;
BA_ "GenMsgSendType" BO_ 2364738302 0;
BA_ "GenMsgCycleTime" BO_ 2364738302 20;
BA_ "GenMsgSendType" BO_ 2364738046 0;
BA_ "GenMsgCycleTime" BO_ 2364738046 100;
BA_ "GenMsgSendType" BO_ 2364737790 0;
BA_ "GenMsgCycleTime" BO_ 2364737790 20;
BA_ "GenMsgSendType" BO_ 2364737534 0;
BA_ "GenMsgCycleTime" BO_ 2364737534 20;
BA_ "GenMsgSendType" BO_ 2364737278 0;
BA_ "GenMsgCycleTime" BO_ 2364737278 20;
BA_ "GenMsgSendType" BO_ 2364737022 0;
BA_ "GenMsgCycleTime" BO_ 2364737022 100;
BA_ "GenMsgSendType" BO_ 2364736766 0;
BA_ "GenMsgCycleTime" BO_ 2364736766 100;
BA_ "GenMsgSendType" BO_ 2364736510 0;
BA_ "GenMsgCycleTime" BO_ 2364736510 100;
BA_ "FsJ1939UseCrcAndCounter" BO_ 2364736254 "Aa";
BA_ "GenMsgSendType" BO_ 2364736254 0;
BA_ "GenMsgCycleTime" BO_ 2364736254 100;
BA_ "GenMsgSendType" BO_ 2364735998 0;
BA_ "GenMsgCycleTime" BO_ 2364735998 100;
BA_ "GenMsgSendType" BO_ 2364735742 0;
BA_ "GenMsgCycleTime" BO_ 2364735742 100;
BA_ "GenMsgSendType" BO_ 2364735486 0;
BA_ "GenMsgCycleTime" BO_ 2364735486 100;
BA_ "GenMsgSendType" BO_ 2364735230 0;
BA_ "GenMsgCycleTime" BO_ 2364735230 100;
BA_ "FsJ1939UseCrcAndCounter" BO_ 2364734974 "Aa";
BA_ "GenMsgDelayTime" BO_ 2364734974 20;
BA_ "GenMsgSendType" BO_ 2364734974 0;
BA_ "GenMsgCycleTime" BO_ 2364734974 100;
BA_ "GenMsgSendType" BO_ 2364734718 0;
BA_ "GenMsgCycleTime" BO_ 2364734718 100;
BA_ "GenMsgSendType" BO_ 2364734462 0;
BA_ "GenMsgCycleTime" BO_ 2364734462 20;
BA_ "GenMsgSendType" BO_ 2364734206 0;
BA_ "GenMsgCycleTime" BO_ 2364734206 100;
BA_ "GenMsgSendType" BO_ 2364733950 0;
BA_ "GenMsgCycleTime" BO_ 2364733950 20;
BA_ "GenMsgSendType" BO_ 2364733694 0;
BA_ "GenMsgCycleTime" BO_ 2364733694 20;
BA_ "SigType" SG_ 2364743934 Data9CRC 12;
BA_ "SPN" SG_ 2364743934 Data9CRC 23045;
BA_ "SigType" SG_ 2364743934 Data9Counter 11;
BA_ "SPN" SG_ 2364743934 Data9Counter 23044;
BA_ "SigType" SG_ 2364743934 Data9EmbeddedIntegritySupport 5;
BA_ "SPN" SG_ 2364743934 Data9EmbeddedIntegritySupport 23043;
BA_ "SigType" SG_ 2364743934 HVESS24ThermalEventDetected 4;
BA_ "SPN" SG_ 2364743934 HVESS24ThermalEventDetected 21311;
BA_ "SigType" SG_ 2364743934 LowestCellTempCellNum 1;
BA_ "SPN" SG_ 2364743934 LowestCellTempCellNum 17231;
BA_ "SigType" SG_ 2364743934 LowestCellTempModuleNum 1;
BA_ "SPN" SG_ 2364743934 LowestCellTempModuleNum 17230;
BA_ "SigType" SG_ 2364743934 HighestCellTempCellNum 1;
BA_ "SPN" SG_ 2364743934 HighestCellTempCellNum 17229;
BA_ "SigType" SG_ 2364743934 HighestCellTempModuleNum 1;
BA_ "SPN" SG_ 2364743934 HighestCellTempModuleNum 17228;
BA_ "SigType" SG_ 2364743678 AvgCellV 1;
BA_ "SPN" SG_ 2364743678 AvgCellV 17227;
BA_ "SigType" SG_ 2364743678 LowestCellVCellNum 1;
BA_ "SPN" SG_ 2364743678 LowestCellVCellNum 17226;
BA_ "SigType" SG_ 2364743678 LowestCellVModuleNum 1;
BA_ "SPN" SG_ 2364743678 LowestCellVModuleNum 17225;
BA_ "SigType" SG_ 2364743678 HighestCellVCellNum 1;
BA_ "SPN" SG_ 2364743678 HighestCellVCellNum 17224;
BA_ "SigType" SG_ 2364743678 HighestCellVModuleNum 1;
BA_ "SPN" SG_ 2364743678 HighestCellVModuleNum 17223;
BA_ "SigType" SG_ 2364743422 TMSCoolantLvl 4;
BA_ "SPN" SG_ 2364743422 TMSCoolantLvl 17222;
BA_ "SPN" SG_ 2364743422 TMSMode 17221;
BA_ "SigType" SG_ 2364743422 TMSHVILStatus 4;
BA_ "SPN" SG_ 2364743422 TMSHVILStatus 17220;
BA_ "SigType" SG_ 2364743422 TMSHtrStatus 5;
BA_ "SPN" SG_ 2364743422 TMSHtrStatus 17219;
BA_ "SigType" SG_ 2364743422 TMSRelHumidty 1;
BA_ "SPN" SG_ 2364743422 TMSRelHumidty 17218;
BA_ "SigType" SG_ 2364743422 TMSCompressorSpd 1;
BA_ "SPN" SG_ 2364743422 TMSCompressorSpd 17217;
BA_ "SigType" SG_ 2364743422 TMSHVInputPwr 1;
BA_ "SPN" SG_ 2364743422 TMSHVInputPwr 17216;
BA_ "SigType" SG_ 2364743422 TMSSLIInputPwr 1;
BA_ "SPN" SG_ 2364743422 TMSSLIInputPwr 17215;
BA_ "SigType" SG_ 2364743166 Module32OperationalStatus 5;
BA_ "SPN" SG_ 2364743166 Module32OperationalStatus 17214;
BA_ "SigType" SG_ 2364743166 Module31OperationalStatus 5;
BA_ "SPN" SG_ 2364743166 Module31OperationalStatus 17213;
BA_ "SigType" SG_ 2364743166 Module30OperationalStatus 5;
BA_ "SPN" SG_ 2364743166 Module30OperationalStatus 17212;
BA_ "SigType" SG_ 2364743166 Module29OperationalStatus 5;
BA_ "SPN" SG_ 2364743166 Module29OperationalStatus 17211;
BA_ "SigType" SG_ 2364743166 Module28OperationalStatus 5;
BA_ "SPN" SG_ 2364743166 Module28OperationalStatus 17210;
BA_ "SigType" SG_ 2364743166 Module27OperationalStatus 5;
BA_ "SPN" SG_ 2364743166 Module27OperationalStatus 17209;
BA_ "SigType" SG_ 2364743166 Module26OperationalStatus 5;
BA_ "SPN" SG_ 2364743166 Module26OperationalStatus 17208;
BA_ "SigType" SG_ 2364743166 Module25OperationalStatus 5;
BA_ "SPN" SG_ 2364743166 Module25OperationalStatus 17207;
BA_ "SigType" SG_ 2364743166 Module24OperationalStatus 5;
BA_ "SPN" SG_ 2364743166 Module24OperationalStatus 17206;
BA_ "SigType" SG_ 2364743166 Module23OperationalStatus 5;
BA_ "SPN" SG_ 2364743166 Module23OperationalStatus 17205;
BA_ "SigType" SG_ 2364743166 Module22OperationalStatus 5;
BA_ "SPN" SG_ 2364743166 Module22OperationalStatus 17204;
BA_ "SigType" SG_ 2364743166 Module21OperationalStatus 5;
BA_ "SPN" SG_ 2364743166 Module21OperationalStatus 17203;
BA_ "SigType" SG_ 2364743166 Module20OperationalStatus 5;
BA_ "SPN" SG_ 2364743166 Module20OperationalStatus 17202;
BA_ "SigType" SG_ 2364743166 Module19OperationalStatus 5;
BA_ "SPN" SG_ 2364743166 Module19OperationalStatus 17201;
BA_ "SigType" SG_ 2364743166 Module18OperationalStatus 5;
BA_ "SPN" SG_ 2364743166 Module18OperationalStatus 17200;
BA_ "SigType" SG_ 2364743166 Module17OperationalStatus 5;
BA_ "SPN" SG_ 2364743166 Module17OperationalStatus 17199;
BA_ "SigType" SG_ 2364743166 Module16OperationalStatus 5;
BA_ "SPN" SG_ 2364743166 Module16OperationalStatus 17198;
BA_ "SigType" SG_ 2364743166 Module15OperationalStatus 5;
BA_ "SPN" SG_ 2364743166 Module15OperationalStatus 17197;
BA_ "SigType" SG_ 2364743166 Module14OperationalStatus 5;
BA_ "SPN" SG_ 2364743166 Module14OperationalStatus 17196;
BA_ "SigType" SG_ 2364743166 Module13OperationalStatus 5;
BA_ "SPN" SG_ 2364743166 Module13OperationalStatus 17195;
BA_ "SigType" SG_ 2364743166 Module12OperationalStatus 5;
BA_ "SPN" SG_ 2364743166 Module12OperationalStatus 17194;
BA_ "SigType" SG_ 2364743166 Module11OperationalStatus 5;
BA_ "SPN" SG_ 2364743166 Module11OperationalStatus 17193;
BA_ "SigType" SG_ 2364743166 Module10OperationalStatus 5;
BA_ "SPN" SG_ 2364743166 Module10OperationalStatus 17192;
BA_ "SigType" SG_ 2364743166 Module9OperationalStatus 5;
BA_ "SPN" SG_ 2364743166 Module9OperationalStatus 17191;
BA_ "SigType" SG_ 2364743166 Module8OperationalStatus 5;
BA_ "SPN" SG_ 2364743166 Module8OperationalStatus 17190;
BA_ "SigType" SG_ 2364743166 Module7OperationalStatus 5;
BA_ "SPN" SG_ 2364743166 Module7OperationalStatus 17189;
BA_ "SigType" SG_ 2364743166 Module6OperationalStatus 5;
BA_ "SPN" SG_ 2364743166 Module6OperationalStatus 17188;
BA_ "SigType" SG_ 2364743166 Module5OperationalStatus 5;
BA_ "SPN" SG_ 2364743166 Module5OperationalStatus 17187;
BA_ "SigType" SG_ 2364743166 Module4OperationalStatus 5;
BA_ "SPN" SG_ 2364743166 Module4OperationalStatus 17186;
BA_ "SigType" SG_ 2364743166 Module3OperationalStatus 5;
BA_ "SPN" SG_ 2364743166 Module3OperationalStatus 17185;
BA_ "SigType" SG_ 2364743166 Module2OperationalStatus 5;
BA_ "SPN" SG_ 2364743166 Module2OperationalStatus 17184;
BA_ "SigType" SG_ 2364743166 Module1OperationalStatus 5;
BA_ "SPN" SG_ 2364743166 Module1OperationalStatus 17183;
BA_ "SigType" SG_ 2364742910 MaxChargeVLmt 1;
BA_ "SPN" SG_ 2364742910 MaxChargeVLmt 17182;
BA_ "SPN" SG_ 2364742910 ChargeEnergyCapacity 17181;
BA_ "SPN" SG_ 2364742910 DisEnergyCapacity 17180;
BA_ "SigType" SG_ 2364742654 Status1CRC 12;
BA_ "SPN" SG_ 2364742654 Status1CRC 17179;
BA_ "SigType" SG_ 2364742654 Status1Counter 11;
BA_ "SPN" SG_ 2364742654 Status1Counter 17178;
BA_ "SPN" SG_ 2364742654 OperationalStatus 17177;
BA_ "SPN" SG_ 2364742654 HVBusConnectionStatus 17176;
BA_ "SigType" SG_ 2364742654 InternalChargerStatus 5;
BA_ "SPN" SG_ 2364742654 InternalChargerStatus 17175;
BA_ "SigType" SG_ 2364742654 CellBalancingActive 4;
BA_ "SPN" SG_ 2364742654 CellBalancingActive 17174;
BA_ "SigType" SG_ 2364742654 CellBalanceStatus 4;
BA_ "SPN" SG_ 2364742654 CellBalanceStatus 17173;
BA_ "SPN" SG_ 2364742654 StOfChargeStatus 17172;
BA_ "SigType" SG_ 2364742654 InertiaSwStatus 4;
BA_ "SPN" SG_ 2364742654 InertiaSwStatus 17171;
BA_ "SigType" SG_ 2364742654 HVILStatus 4;
BA_ "SPN" SG_ 2364742654 HVILStatus 17170;
BA_ "SPN" SG_ 2364742654 HVBusPassiveIsolTestStatus 17169;
BA_ "SPN" SG_ 2364742654 HVBusActiveIsolTestStatus 17168;
BA_ "SigType" SG_ 2364742654 CenterOfPackContactorSt 4;
BA_ "SPN" SG_ 2364742654 CenterOfPackContactorSt 17167;
BA_ "SigType" SG_ 2364742654 HVBusPreChargeRelaySt 4;
BA_ "SPN" SG_ 2364742654 HVBusPreChargeRelaySt 17166;
BA_ "SPN" SG_ 2364742654 HVBusDisconnectForewarning 17165;
BA_ "SigType" SG_ 2364742654 HVBusContactorSt17164 4;
BA_ "SPN" SG_ 2364742654 HVBusContactorSt17164 17164;
BA_ "SigType" SG_ 2364742654 HVBusContactorSt 4;
BA_ "SPN" SG_ 2364742654 HVBusContactorSt 17163;
BA_ "SigType" SG_ 2364742398 Temp 1;
BA_ "SPN" SG_ 2364742398 Temp 17162;
BA_ "SigType" SG_ 2364742398 ETemp 1;
BA_ "SPN" SG_ 2364742398 ETemp 17161;
BA_ "SigType" SG_ 2364742398 OutCoolantTemp 1;
BA_ "SPN" SG_ 2364742398 OutCoolantTemp 17160;
BA_ "SigType" SG_ 2364742398 InCoolantTemp 1;
BA_ "SPN" SG_ 2364742398 InCoolantTemp 17159;
BA_ "SigType" SG_ 2364742398 IgntV 1;
BA_ "SPN" SG_ 2364742398 IgntV 17158;
BA_ "SigType" SG_ 2364742398 BusV 1;
BA_ "SPN" SG_ 2364742398 BusV 17157;
BA_ "SigType" SG_ 2364742142 HighestCellStOfCharge 1;
BA_ "SPN" SG_ 2364742142 HighestCellStOfCharge 17156;
BA_ "SigType" SG_ 2364742142 LowestCellStOfCharge 1;
BA_ "SPN" SG_ 2364742142 LowestCellStOfCharge 17155;
BA_ "SigType" SG_ 2364742142 ChargeCurLmt 1;
BA_ "GenSigStartValue" SG_ 2364742142 ChargeCurLmt 32000;
BA_ "SPN" SG_ 2364742142 ChargeCurLmt 17154;
BA_ "SigType" SG_ 2364742142 DisCurLmt 1;
BA_ "SPN" SG_ 2364742142 DisCurLmt 17153;
BA_ "SigType" SG_ 2364741886 CellBalancingCount 1;
BA_ "SPN" SG_ 2364741886 CellBalancingCount 17152;
BA_ "SigType" SG_ 2364741886 ChargeCapacity 1;
BA_ "SPN" SG_ 2364741886 ChargeCapacity 17151;
BA_ "SigType" SG_ 2364741886 DisCapacity 1;
BA_ "SPN" SG_ 2364741886 DisCapacity 17150;
BA_ "SigType" SG_ 2364741630 CellTempDiffStatus 4;
BA_ "SPN" SG_ 2364741630 CellTempDiffStatus 17149;
BA_ "SigType" SG_ 2364741630 AvgCellTemp 1;
BA_ "SPN" SG_ 2364741630 AvgCellTemp 17148;
BA_ "SigType" SG_ 2364741630 LowestCellTemp 1;
BA_ "SPN" SG_ 2364741630 LowestCellTemp 17147;
BA_ "SigType" SG_ 2364741630 HighestCellTemp 1;
BA_ "SPN" SG_ 2364741630 HighestCellTemp 17146;
BA_ "SPN" SG_ 2364741374 CellVDiffStatus 17145;
BA_ "SigType" SG_ 2364741374 LowestCellV 1;
BA_ "SPN" SG_ 2364741374 LowestCellV 17144;
BA_ "SigType" SG_ 2364741374 HighestCellV 1;
BA_ "SPN" SG_ 2364741374 HighestCellV 17143;
BA_ "SigType" SG_ 2364741374 FastUpdateStOfCharge 1;
BA_ "SPN" SG_ 2364741374 FastUpdateStOfCharge 17142;
BA_ "SigType" SG_ 2364741118 Cur 1;
BA_ "SPN" SG_ 2364741118 Cur 17141;
BA_ "SigType" SG_ 2364741118 Lvl 1;
BA_ "SPN" SG_ 2364741118 Lvl 17140;
BA_ "SigType" SG_ 2364741118 AvailableChargePwr 1;
BA_ "SPN" SG_ 2364741118 AvailableChargePwr 17139;
BA_ "SigType" SG_ 2364741118 AvailableDisPwr 1;
BA_ "SPN" SG_ 2364741118 AvailableDisPwr 17138;
BA_ "SigType" SG_ 2364740862 ChargePLDueToAnUndefinedCause 4;
BA_ "SPN" SG_ 2364740862 ChargePLDueToAnUndefinedCause 17137;
BA_ "SigType" SG_ 2364740862 ChargePLDueToBatCur 4;
BA_ "SPN" SG_ 2364740862 ChargePLDueToBatCur 17136;
BA_ "SigType" SG_ 2364740862 ChargePLDueToBatOrCellV 4;
BA_ "SPN" SG_ 2364740862 ChargePLDueToBatOrCellV 17135;
BA_ "SigType" SG_ 2364740862 ChargePLDueToBatDiagCondition 4;
BA_ "SPN" SG_ 2364740862 ChargePLDueToBatDiagCondition 17134;
BA_ "SigType" SG_ 2364740862 ChargePLDueToBatTemp 4;
BA_ "SPN" SG_ 2364740862 ChargePLDueToBatTemp 17133;
BA_ "SigType" SG_ 2364740862 ChargePLDueToStOfCharge 4;
BA_ "SPN" SG_ 2364740862 ChargePLDueToStOfCharge 17132;
BA_ "SigType" SG_ 2364740862 DisPLDueToAnUndefinedCause 4;
BA_ "SPN" SG_ 2364740862 DisPLDueToAnUndefinedCause 17131;
BA_ "SigType" SG_ 2364740862 DisPLDueToBatCur 4;
BA_ "SPN" SG_ 2364740862 DisPLDueToBatCur 17130;
BA_ "SigType" SG_ 2364740862 DisPLDueToBatOrCellV 4;
BA_ "SPN" SG_ 2364740862 DisPLDueToBatOrCellV 17129;
BA_ "SigType" SG_ 2364740862 DisPLDueToBatDiagCondition 4;
BA_ "SPN" SG_ 2364740862 DisPLDueToBatDiagCondition 17128;
BA_ "SigType" SG_ 2364740862 DisPLDueToBatTemp 4;
BA_ "SPN" SG_ 2364740862 DisPLDueToBatTemp 17127;
BA_ "SigType" SG_ 2364740862 DisPLDueToStOfCharge 4;
BA_ "SPN" SG_ 2364740862 DisPLDueToStOfCharge 17126;
BA_ "SigType" SG_ 2364740606 ActualChargeRate 1;
BA_ "SPN" SG_ 2364740606 ActualChargeRate 17098;
BA_ "SigType" SG_ 2364740606 LvlNegToChassisGroundV 1;
BA_ "SPN" SG_ 2364740606 LvlNegToChassisGroundV 17097;
BA_ "SigType" SG_ 2364740606 BusVNegToChassisGroundV 1;
BA_ "SPN" SG_ 2364740606 BusVNegToChassisGroundV 17096;
BA_ "SigType" SG_ 2364740350 HVBusPassiveIsolTestResults 1;
BA_ "SPN" SG_ 2364740350 HVBusPassiveIsolTestResults 17095;
BA_ "SigType" SG_ 2364740350 HVBusActiveIsolTestResults 1;
BA_ "SPN" SG_ 2364740350 HVBusActiveIsolTestResults 17094;
BA_ "SigType" SG_ 2364740350 LowestCellStOfChargeCellNum 1;
BA_ "SPN" SG_ 2364740350 LowestCellStOfChargeCellNum 17093;
BA_ "SigType" SG_ 2364740350 LowestCellStOfChargeModuleNum 1;
BA_ "SPN" SG_ 2364740350 LowestCellStOfChargeModuleNum 17092;
BA_ "SigType" SG_ 2364740350 HighestCellStOfChargeCellNum 1;
BA_ "SPN" SG_ 2364740350 HighestCellStOfChargeCellNum 17091;
BA_ "SigType" SG_ 2364740350 HighestCellStOfChargeModuleNum 1;
BA_ "SPN" SG_ 2364740350 HighestCellStOfChargeModuleNum 17090;
BA_ "SigType" SG_ 2364740094 Data9CRC 12;
BA_ "SPN" SG_ 2364740094 Data9CRC 23042;
BA_ "SigType" SG_ 2364740094 Data9Counter 11;
BA_ "SPN" SG_ 2364740094 Data9Counter 23041;
BA_ "SigType" SG_ 2364740094 Data9EmbeddedIntegritySupport 5;
BA_ "SPN" SG_ 2364740094 Data9EmbeddedIntegritySupport 23040;
BA_ "SigType" SG_ 2364740094 HVESS23ThermalEventDetected 4;
BA_ "SPN" SG_ 2364740094 HVESS23ThermalEventDetected 21310;
BA_ "SigType" SG_ 2364740094 LowestCellTempCellNum 1;
BA_ "SPN" SG_ 2364740094 LowestCellTempCellNum 17089;
BA_ "SigType" SG_ 2364740094 LowestCellTempModuleNum 1;
BA_ "SPN" SG_ 2364740094 LowestCellTempModuleNum 17088;
BA_ "SigType" SG_ 2364740094 HighestCellTempCellNum 1;
BA_ "SPN" SG_ 2364740094 HighestCellTempCellNum 17087;
BA_ "SigType" SG_ 2364740094 HighestCellTempModuleNum 1;
BA_ "SPN" SG_ 2364740094 HighestCellTempModuleNum 17086;
BA_ "SigType" SG_ 2364739838 AvgCellV 1;
BA_ "SPN" SG_ 2364739838 AvgCellV 17085;
BA_ "SigType" SG_ 2364739838 LowestCellVCellNum 1;
BA_ "SPN" SG_ 2364739838 LowestCellVCellNum 17084;
BA_ "SigType" SG_ 2364739838 LowestCellVModuleNum 1;
BA_ "SPN" SG_ 2364739838 LowestCellVModuleNum 17083;
BA_ "SigType" SG_ 2364739838 HighestCellVCellNum 1;
BA_ "SPN" SG_ 2364739838 HighestCellVCellNum 17082;
BA_ "SigType" SG_ 2364739838 HighestCellVModuleNum 1;
BA_ "SPN" SG_ 2364739838 HighestCellVModuleNum 17081;
BA_ "SigType" SG_ 2364739582 TMSCoolantLvl 4;
BA_ "SPN" SG_ 2364739582 TMSCoolantLvl 17080;
BA_ "SPN" SG_ 2364739582 TMSMode 17079;
BA_ "SigType" SG_ 2364739582 TMSHVILStatus 4;
BA_ "SPN" SG_ 2364739582 TMSHVILStatus 17078;
BA_ "SigType" SG_ 2364739582 TMSHtrStatus 5;
BA_ "SPN" SG_ 2364739582 TMSHtrStatus 17077;
BA_ "SigType" SG_ 2364739582 TMSRelHumidty 1;
BA_ "SPN" SG_ 2364739582 TMSRelHumidty 17076;
BA_ "SigType" SG_ 2364739582 TMSCompressorSpd 1;
BA_ "SPN" SG_ 2364739582 TMSCompressorSpd 17075;
BA_ "SigType" SG_ 2364739582 TMSHVInputPwr 1;
BA_ "SPN" SG_ 2364739582 TMSHVInputPwr 17074;
BA_ "SigType" SG_ 2364739582 TMSSLIInputPwr 1;
BA_ "SPN" SG_ 2364739582 TMSSLIInputPwr 17073;
BA_ "SigType" SG_ 2364739326 Module32OperationalStatus 5;
BA_ "SPN" SG_ 2364739326 Module32OperationalStatus 17072;
BA_ "SigType" SG_ 2364739326 Module31OperationalStatus 5;
BA_ "SPN" SG_ 2364739326 Module31OperationalStatus 17071;
BA_ "SigType" SG_ 2364739326 Module30OperationalStatus 5;
BA_ "SPN" SG_ 2364739326 Module30OperationalStatus 17070;
BA_ "SigType" SG_ 2364739326 Module29OperationalStatus 5;
BA_ "SPN" SG_ 2364739326 Module29OperationalStatus 17069;
BA_ "SigType" SG_ 2364739326 Module28OperationalStatus 5;
BA_ "SPN" SG_ 2364739326 Module28OperationalStatus 17068;
BA_ "SigType" SG_ 2364739326 Module27OperationalStatus 5;
BA_ "SPN" SG_ 2364739326 Module27OperationalStatus 17067;
BA_ "SigType" SG_ 2364739326 Module26OperationalStatus 5;
BA_ "SPN" SG_ 2364739326 Module26OperationalStatus 17066;
BA_ "SigType" SG_ 2364739326 Module25OperationalStatus 5;
BA_ "SPN" SG_ 2364739326 Module25OperationalStatus 17065;
BA_ "SigType" SG_ 2364739326 Module24OperationalStatus 5;
BA_ "SPN" SG_ 2364739326 Module24OperationalStatus 17064;
BA_ "SigType" SG_ 2364739326 Module23OperationalStatus 5;
BA_ "SPN" SG_ 2364739326 Module23OperationalStatus 17063;
BA_ "SigType" SG_ 2364739326 Module22OperationalStatus 5;
BA_ "SPN" SG_ 2364739326 Module22OperationalStatus 17062;
BA_ "SigType" SG_ 2364739326 Module21OperationalStatus 5;
BA_ "SPN" SG_ 2364739326 Module21OperationalStatus 17061;
BA_ "SigType" SG_ 2364739326 Module20OperationalStatus 5;
BA_ "SPN" SG_ 2364739326 Module20OperationalStatus 17060;
BA_ "SigType" SG_ 2364739326 Module19OperationalStatus 5;
BA_ "SPN" SG_ 2364739326 Module19OperationalStatus 17059;
BA_ "SigType" SG_ 2364739326 Module18OperationalStatus 5;
BA_ "SPN" SG_ 2364739326 Module18OperationalStatus 17058;
BA_ "SigType" SG_ 2364739326 Module17OperationalStatus 5;
BA_ "SPN" SG_ 2364739326 Module17OperationalStatus 17057;
BA_ "SigType" SG_ 2364739326 Module16OperationalStatus 5;
BA_ "SPN" SG_ 2364739326 Module16OperationalStatus 17056;
BA_ "SigType" SG_ 2364739326 Module15OperationalStatus 5;
BA_ "SPN" SG_ 2364739326 Module15OperationalStatus 17055;
BA_ "SigType" SG_ 2364739326 Module14OperationalStatus 5;
BA_ "SPN" SG_ 2364739326 Module14OperationalStatus 17054;
BA_ "SigType" SG_ 2364739326 Module13OperationalStatus 5;
BA_ "SPN" SG_ 2364739326 Module13OperationalStatus 17053;
BA_ "SigType" SG_ 2364739326 Module12OperationalStatus 5;
BA_ "SPN" SG_ 2364739326 Module12OperationalStatus 17052;
BA_ "SigType" SG_ 2364739326 Module11OperationalStatus 5;
BA_ "SPN" SG_ 2364739326 Module11OperationalStatus 17051;
BA_ "SigType" SG_ 2364739326 Module10OperationalStatus 5;
BA_ "SPN" SG_ 2364739326 Module10OperationalStatus 17050;
BA_ "SigType" SG_ 2364739326 Module9OperationalStatus 5;
BA_ "SPN" SG_ 2364739326 Module9OperationalStatus 17049;
BA_ "SigType" SG_ 2364739326 Module8OperationalStatus 5;
BA_ "SPN" SG_ 2364739326 Module8OperationalStatus 17048;
BA_ "SigType" SG_ 2364739326 Module7OperationalStatus 5;
BA_ "SPN" SG_ 2364739326 Module7OperationalStatus 17047;
BA_ "SigType" SG_ 2364739326 Module6OperationalStatus 5;
BA_ "SPN" SG_ 2364739326 Module6OperationalStatus 17046;
BA_ "SigType" SG_ 2364739326 Module5OperationalStatus 5;
BA_ "SPN" SG_ 2364739326 Module5OperationalStatus 17045;
BA_ "SigType" SG_ 2364739326 Module4OperationalStatus 5;
BA_ "SPN" SG_ 2364739326 Module4OperationalStatus 17044;
BA_ "SigType" SG_ 2364739326 Module3OperationalStatus 5;
BA_ "SPN" SG_ 2364739326 Module3OperationalStatus 17043;
BA_ "SigType" SG_ 2364739326 Module2OperationalStatus 5;
BA_ "SPN" SG_ 2364739326 Module2OperationalStatus 17042;
BA_ "SigType" SG_ 2364739326 Module1OperationalStatus 5;
BA_ "SPN" SG_ 2364739326 Module1OperationalStatus 17041;
BA_ "SigType" SG_ 2364739070 MaxChargeVLmt 1;
BA_ "SPN" SG_ 2364739070 MaxChargeVLmt 17040;
BA_ "SPN" SG_ 2364739070 ChargeEnergyCapacity 17039;
BA_ "SPN" SG_ 2364739070 DisEnergyCapacity 17038;
BA_ "SigType" SG_ 2364738814 Status1CRC 12;
BA_ "SPN" SG_ 2364738814 Status1CRC 17037;
BA_ "SigType" SG_ 2364738814 Status1Counter 11;
BA_ "SPN" SG_ 2364738814 Status1Counter 17036;
BA_ "SPN" SG_ 2364738814 OperationalStatus 17035;
BA_ "SPN" SG_ 2364738814 HVBusConnectionStatus 17034;
BA_ "SigType" SG_ 2364738814 InternalChargerStatus 5;
BA_ "SPN" SG_ 2364738814 InternalChargerStatus 17033;
BA_ "SigType" SG_ 2364738814 CellBalancingActive 4;
BA_ "SPN" SG_ 2364738814 CellBalancingActive 17032;
BA_ "SigType" SG_ 2364738814 CellBalanceStatus 4;
BA_ "SPN" SG_ 2364738814 CellBalanceStatus 17031;
BA_ "SPN" SG_ 2364738814 StOfChargeStatus 17030;
BA_ "SigType" SG_ 2364738814 InertiaSwStatus 4;
BA_ "SPN" SG_ 2364738814 InertiaSwStatus 17029;
BA_ "SigType" SG_ 2364738814 HVILStatus 4;
BA_ "SPN" SG_ 2364738814 HVILStatus 17028;
BA_ "SPN" SG_ 2364738814 HVBusPassiveIsolTestStatus 17027;
BA_ "SPN" SG_ 2364738814 HVBusActiveIsolTestStatus 17026;
BA_ "SigType" SG_ 2364738814 CenterOfPackContactorSt 4;
BA_ "SPN" SG_ 2364738814 CenterOfPackContactorSt 17025;
BA_ "SigType" SG_ 2364738814 HVBusPreChargeRelaySt 4;
BA_ "SPN" SG_ 2364738814 HVBusPreChargeRelaySt 17024;
BA_ "SPN" SG_ 2364738814 HVBusDisconnectForewarning 17023;
BA_ "SigType" SG_ 2364738814 HVBusContactorSt17022 4;
BA_ "SPN" SG_ 2364738814 HVBusContactorSt17022 17022;
BA_ "SigType" SG_ 2364738814 HVBusContactorSt 4;
BA_ "SPN" SG_ 2364738814 HVBusContactorSt 17021;
BA_ "SigType" SG_ 2364738558 Temp 1;
BA_ "SPN" SG_ 2364738558 Temp 17020;
BA_ "SigType" SG_ 2364738558 ETemp 1;
BA_ "SPN" SG_ 2364738558 ETemp 17019;
BA_ "SigType" SG_ 2364738558 OutCoolantTemp 1;
BA_ "SPN" SG_ 2364738558 OutCoolantTemp 17018;
BA_ "SigType" SG_ 2364738558 InCoolantTemp 1;
BA_ "SPN" SG_ 2364738558 InCoolantTemp 17017;
BA_ "SigType" SG_ 2364738558 IgntV 1;
BA_ "SPN" SG_ 2364738558 IgntV 17016;
BA_ "SigType" SG_ 2364738558 BusV 1;
BA_ "SPN" SG_ 2364738558 BusV 17015;
BA_ "SigType" SG_ 2364738302 HighestCellStOfCharge 1;
BA_ "SPN" SG_ 2364738302 HighestCellStOfCharge 17014;
BA_ "SigType" SG_ 2364738302 LowestCellStOfCharge 1;
BA_ "SPN" SG_ 2364738302 LowestCellStOfCharge 17013;
BA_ "SigType" SG_ 2364738302 ChargeCurLmt 1;
BA_ "GenSigStartValue" SG_ 2364738302 ChargeCurLmt 32000;
BA_ "SPN" SG_ 2364738302 ChargeCurLmt 17012;
BA_ "SigType" SG_ 2364738302 DisCurLmt 1;
BA_ "SPN" SG_ 2364738302 DisCurLmt 17011;
BA_ "SigType" SG_ 2364738046 CellBalancingCount 1;
BA_ "SPN" SG_ 2364738046 CellBalancingCount 17010;
BA_ "SigType" SG_ 2364738046 ChargeCapacity 1;
BA_ "SPN" SG_ 2364738046 ChargeCapacity 17009;
BA_ "SigType" SG_ 2364738046 DisCapacity 1;
BA_ "SPN" SG_ 2364738046 DisCapacity 17008;
BA_ "SigType" SG_ 2364737790 CellTempDiffStatus 4;
BA_ "SPN" SG_ 2364737790 CellTempDiffStatus 17007;
BA_ "SigType" SG_ 2364737790 AvgCellTemp 1;
BA_ "SPN" SG_ 2364737790 AvgCellTemp 17006;
BA_ "SigType" SG_ 2364737790 LowestCellTemp 1;
BA_ "SPN" SG_ 2364737790 LowestCellTemp 17005;
BA_ "SigType" SG_ 2364737790 HighestCellTemp 1;
BA_ "SPN" SG_ 2364737790 HighestCellTemp 17004;
BA_ "SPN" SG_ 2364737534 CellVDiffStatus 17003;
BA_ "SigType" SG_ 2364737534 LowestCellV 1;
BA_ "SPN" SG_ 2364737534 LowestCellV 17002;
BA_ "SigType" SG_ 2364737534 HighestCellV 1;
BA_ "SPN" SG_ 2364737534 HighestCellV 17001;
BA_ "SigType" SG_ 2364737534 FastUpdateStOfCharge 1;
BA_ "SPN" SG_ 2364737534 FastUpdateStOfCharge 17000;
BA_ "SigType" SG_ 2364737278 Cur 1;
BA_ "SPN" SG_ 2364737278 Cur 16999;
BA_ "SigType" SG_ 2364737278 Lvl 1;
BA_ "SPN" SG_ 2364737278 Lvl 16998;
BA_ "SigType" SG_ 2364737278 AvailableChargePwr 1;
BA_ "SPN" SG_ 2364737278 AvailableChargePwr 16997;
BA_ "SigType" SG_ 2364737278 AvailableDisPwr 1;
BA_ "SPN" SG_ 2364737278 AvailableDisPwr 16996;
BA_ "SigType" SG_ 2364737022 ChargePLDueToAnUndefinedCause 4;
BA_ "SPN" SG_ 2364737022 ChargePLDueToAnUndefinedCause 16995;
BA_ "SigType" SG_ 2364737022 ChargePLDueToBatCur 4;
BA_ "SPN" SG_ 2364737022 ChargePLDueToBatCur 16994;
BA_ "SigType" SG_ 2364737022 ChargePLDueToBatOrCellV 4;
BA_ "SPN" SG_ 2364737022 ChargePLDueToBatOrCellV 16993;
BA_ "SigType" SG_ 2364737022 ChargePLDueToBatDiagCondition 4;
BA_ "SPN" SG_ 2364737022 ChargePLDueToBatDiagCondition 16992;
BA_ "SigType" SG_ 2364737022 ChargePLDueToBatTemp 4;
BA_ "SPN" SG_ 2364737022 ChargePLDueToBatTemp 16991;
BA_ "SigType" SG_ 2364737022 ChargePLDueToStOfCharge 4;
BA_ "SPN" SG_ 2364737022 ChargePLDueToStOfCharge 16990;
BA_ "SigType" SG_ 2364737022 DisPLDueToAnUndefinedCause 4;
BA_ "SPN" SG_ 2364737022 DisPLDueToAnUndefinedCause 16989;
BA_ "SigType" SG_ 2364737022 DisPLDueToBatCur 4;
BA_ "SPN" SG_ 2364737022 DisPLDueToBatCur 16988;
BA_ "SigType" SG_ 2364737022 DisPLDueToBatOrCellV 4;
BA_ "SPN" SG_ 2364737022 DisPLDueToBatOrCellV 16987;
BA_ "SigType" SG_ 2364737022 DisPLDueToBatDiagCondition 4;
BA_ "SPN" SG_ 2364737022 DisPLDueToBatDiagCondition 16986;
BA_ "SigType" SG_ 2364737022 DisPLDueToBatTemp 4;
BA_ "SPN" SG_ 2364737022 DisPLDueToBatTemp 16985;
BA_ "SigType" SG_ 2364737022 DisPLDueToStOfCharge 4;
BA_ "SPN" SG_ 2364737022 DisPLDueToStOfCharge 16984;
BA_ "SigType" SG_ 2364736766 ActualChargeRate 1;
BA_ "SPN" SG_ 2364736766 ActualChargeRate 16956;
BA_ "SigType" SG_ 2364736766 LvlNegToChassisGroundV 1;
BA_ "SPN" SG_ 2364736766 LvlNegToChassisGroundV 16955;
BA_ "SigType" SG_ 2364736766 BusVNegToChassisGroundV 1;
BA_ "SPN" SG_ 2364736766 BusVNegToChassisGroundV 16954;
BA_ "SigType" SG_ 2364736510 HVBusPassiveIsolTestResults 1;
BA_ "SPN" SG_ 2364736510 HVBusPassiveIsolTestResults 16953;
BA_ "SigType" SG_ 2364736510 HVBusActiveIsolTestResults 1;
BA_ "SPN" SG_ 2364736510 HVBusActiveIsolTestResults 16952;
BA_ "SigType" SG_ 2364736510 LowestCellStOfChargeCellNum 1;
BA_ "SPN" SG_ 2364736510 LowestCellStOfChargeCellNum 16951;
BA_ "SigType" SG_ 2364736510 LowestCellStOfChargeModuleNum 1;
BA_ "SPN" SG_ 2364736510 LowestCellStOfChargeModuleNum 16950;
BA_ "SigType" SG_ 2364736510 HighestCellStOfChargeCellNum 1;
BA_ "SPN" SG_ 2364736510 HighestCellStOfChargeCellNum 16949;
BA_ "SigType" SG_ 2364736510 HighestCellStOfChargeModuleNum 1;
BA_ "SPN" SG_ 2364736510 HighestCellStOfChargeModuleNum 16948;
BA_ "SigType" SG_ 2364736254 Data9CRC 12;
BA_ "SPN" SG_ 2364736254 Data9CRC 23039;
BA_ "SigType" SG_ 2364736254 Data9Counter 11;
BA_ "SPN" SG_ 2364736254 Data9Counter 23038;
BA_ "SigType" SG_ 2364736254 Data9EmbeddedIntegritySupport 5;
BA_ "SPN" SG_ 2364736254 Data9EmbeddedIntegritySupport 23037;
BA_ "SigType" SG_ 2364736254 HVESS22ThermalEventDetected 4;
BA_ "SPN" SG_ 2364736254 HVESS22ThermalEventDetected 21309;
BA_ "SigType" SG_ 2364736254 LowestCellTempCellNum 1;
BA_ "SPN" SG_ 2364736254 LowestCellTempCellNum 16947;
BA_ "SigType" SG_ 2364736254 LowestCellTempModuleNum 1;
BA_ "SPN" SG_ 2364736254 LowestCellTempModuleNum 16946;
BA_ "SigType" SG_ 2364736254 HighestCellTempCellNum 1;
BA_ "SPN" SG_ 2364736254 HighestCellTempCellNum 16945;
BA_ "SigType" SG_ 2364736254 HighestCellTempModuleNum 1;
BA_ "SPN" SG_ 2364736254 HighestCellTempModuleNum 16944;
BA_ "SigType" SG_ 2364735998 AvgCellV 1;
BA_ "SPN" SG_ 2364735998 AvgCellV 16943;
BA_ "SigType" SG_ 2364735998 LowestCellVCellNum 1;
BA_ "SPN" SG_ 2364735998 LowestCellVCellNum 16942;
BA_ "SigType" SG_ 2364735998 LowestCellVModuleNum 1;
BA_ "SPN" SG_ 2364735998 LowestCellVModuleNum 16941;
BA_ "SigType" SG_ 2364735998 HighestCellVCellNum 1;
BA_ "SPN" SG_ 2364735998 HighestCellVCellNum 16940;
BA_ "SigType" SG_ 2364735998 HighestCellVModuleNum 1;
BA_ "SPN" SG_ 2364735998 HighestCellVModuleNum 16939;
BA_ "SigType" SG_ 2364735742 TMSCoolantLvl 4;
BA_ "SPN" SG_ 2364735742 TMSCoolantLvl 16938;
BA_ "SPN" SG_ 2364735742 TMSMode 16937;
BA_ "SigType" SG_ 2364735742 TMSHVILStatus 4;
BA_ "SPN" SG_ 2364735742 TMSHVILStatus 16936;
BA_ "SigType" SG_ 2364735742 TMSHtrStatus 5;
BA_ "SPN" SG_ 2364735742 TMSHtrStatus 16935;
BA_ "SigType" SG_ 2364735742 TMSRelHumidty 1;
BA_ "SPN" SG_ 2364735742 TMSRelHumidty 16934;
BA_ "SigType" SG_ 2364735742 TMSCompressorSpd 1;
BA_ "SPN" SG_ 2364735742 TMSCompressorSpd 16933;
BA_ "SigType" SG_ 2364735742 TMSHVInputPwr 1;
BA_ "SPN" SG_ 2364735742 TMSHVInputPwr 16932;
BA_ "SigType" SG_ 2364735742 TMSSLIInputPwr 1;
BA_ "SPN" SG_ 2364735742 TMSSLIInputPwr 16931;
BA_ "SigType" SG_ 2364735486 Module32OperationalStatus 5;
BA_ "SPN" SG_ 2364735486 Module32OperationalStatus 16930;
BA_ "SigType" SG_ 2364735486 Module31OperationalStatus 5;
BA_ "SPN" SG_ 2364735486 Module31OperationalStatus 16929;
BA_ "SigType" SG_ 2364735486 Module30OperationalStatus 5;
BA_ "SPN" SG_ 2364735486 Module30OperationalStatus 16928;
BA_ "SigType" SG_ 2364735486 Module29OperationalStatus 5;
BA_ "SPN" SG_ 2364735486 Module29OperationalStatus 16927;
BA_ "SigType" SG_ 2364735486 Module28OperationalStatus 5;
BA_ "SPN" SG_ 2364735486 Module28OperationalStatus 16926;
BA_ "SigType" SG_ 2364735486 Module27OperationalStatus 5;
BA_ "SPN" SG_ 2364735486 Module27OperationalStatus 16925;
BA_ "SigType" SG_ 2364735486 Module26OperationalStatus 5;
BA_ "SPN" SG_ 2364735486 Module26OperationalStatus 16924;
BA_ "SigType" SG_ 2364735486 Module25OperationalStatus 5;
BA_ "SPN" SG_ 2364735486 Module25OperationalStatus 16923;
BA_ "SigType" SG_ 2364735486 Module24OperationalStatus 5;
BA_ "SPN" SG_ 2364735486 Module24OperationalStatus 16922;
BA_ "SigType" SG_ 2364735486 Module23OperationalStatus 5;
BA_ "SPN" SG_ 2364735486 Module23OperationalStatus 16921;
BA_ "SigType" SG_ 2364735486 Module22OperationalStatus 5;
BA_ "SPN" SG_ 2364735486 Module22OperationalStatus 16920;
BA_ "SigType" SG_ 2364735486 Module21OperationalStatus 5;
BA_ "SPN" SG_ 2364735486 Module21OperationalStatus 16919;
BA_ "SigType" SG_ 2364735486 Module20OperationalStatus 5;
BA_ "SPN" SG_ 2364735486 Module20OperationalStatus 16918;
BA_ "SigType" SG_ 2364735486 Module19OperationalStatus 5;
BA_ "SPN" SG_ 2364735486 Module19OperationalStatus 16917;
BA_ "SigType" SG_ 2364735486 Module18OperationalStatus 5;
BA_ "SPN" SG_ 2364735486 Module18OperationalStatus 16916;
BA_ "SigType" SG_ 2364735486 Module17OperationalStatus 5;
BA_ "SPN" SG_ 2364735486 Module17OperationalStatus 16915;
BA_ "SigType" SG_ 2364735486 Module16OperationalStatus 5;
BA_ "SPN" SG_ 2364735486 Module16OperationalStatus 16914;
BA_ "SigType" SG_ 2364735486 Module15OperationalStatus 5;
BA_ "SPN" SG_ 2364735486 Module15OperationalStatus 16913;
BA_ "SigType" SG_ 2364735486 Module14OperationalStatus 5;
BA_ "SPN" SG_ 2364735486 Module14OperationalStatus 16912;
BA_ "SigType" SG_ 2364735486 Module13OperationalStatus 5;
BA_ "SPN" SG_ 2364735486 Module13OperationalStatus 16911;
BA_ "SigType" SG_ 2364735486 Module12OperationalStatus 5;
BA_ "SPN" SG_ 2364735486 Module12OperationalStatus 16910;
BA_ "SigType" SG_ 2364735486 Module11OperationalStatus 5;
BA_ "SPN" SG_ 2364735486 Module11OperationalStatus 16909;
BA_ "SigType" SG_ 2364735486 Module10OperationalStatus 5;
BA_ "SPN" SG_ 2364735486 Module10OperationalStatus 16908;
BA_ "SigType" SG_ 2364735486 Module9OperationalStatus 5;
BA_ "SPN" SG_ 2364735486 Module9OperationalStatus 16907;
BA_ "SigType" SG_ 2364735486 Module8OperationalStatus 5;
BA_ "SPN" SG_ 2364735486 Module8OperationalStatus 16906;
BA_ "SigType" SG_ 2364735486 Module7OperationalStatus 5;
BA_ "SPN" SG_ 2364735486 Module7OperationalStatus 16905;
BA_ "SigType" SG_ 2364735486 Module6OperationalStatus 5;
BA_ "SPN" SG_ 2364735486 Module6OperationalStatus 16904;
BA_ "SigType" SG_ 2364735486 Module5OperationalStatus 5;
BA_ "SPN" SG_ 2364735486 Module5OperationalStatus 16903;
BA_ "SigType" SG_ 2364735486 Module4OperationalStatus 5;
BA_ "SPN" SG_ 2364735486 Module4OperationalStatus 16902;
BA_ "SigType" SG_ 2364735486 Module3OperationalStatus 5;
BA_ "SPN" SG_ 2364735486 Module3OperationalStatus 16901;
BA_ "SigType" SG_ 2364735486 Module2OperationalStatus 5;
BA_ "SPN" SG_ 2364735486 Module2OperationalStatus 16900;
BA_ "SigType" SG_ 2364735486 Module1OperationalStatus 5;
BA_ "SPN" SG_ 2364735486 Module1OperationalStatus 16899;
BA_ "SigType" SG_ 2364735230 MaxChargeVLmt 1;
BA_ "SPN" SG_ 2364735230 MaxChargeVLmt 16898;
BA_ "SPN" SG_ 2364735230 ChargeEnergyCapacity 16897;
BA_ "SPN" SG_ 2364735230 DisEnergyCapacity 16896;
BA_ "SigType" SG_ 2364734974 Status1CRC 12;
BA_ "SPN" SG_ 2364734974 Status1CRC 16895;
BA_ "SigType" SG_ 2364734974 Status1Counter 11;
BA_ "SPN" SG_ 2364734974 Status1Counter 16894;
BA_ "SPN" SG_ 2364734974 OperationalStatus 16893;
BA_ "SPN" SG_ 2364734974 HVBusConnectionStatus 16892;
BA_ "SigType" SG_ 2364734974 InternalChargerStatus 5;
BA_ "SPN" SG_ 2364734974 InternalChargerStatus 16891;
BA_ "SigType" SG_ 2364734974 CellBalancingActive 4;
BA_ "SPN" SG_ 2364734974 CellBalancingActive 16890;
BA_ "SigType" SG_ 2364734974 CellBalanceStatus 4;
BA_ "SPN" SG_ 2364734974 CellBalanceStatus 16889;
BA_ "SPN" SG_ 2364734974 StOfChargeStatus 16888;
BA_ "SigType" SG_ 2364734974 InertiaSwStatus 4;
BA_ "SPN" SG_ 2364734974 InertiaSwStatus 16887;
BA_ "SigType" SG_ 2364734974 HVILStatus 4;
BA_ "SPN" SG_ 2364734974 HVILStatus 16886;
BA_ "SPN" SG_ 2364734974 HVBusPassiveIsolTestStatus 16885;
BA_ "SPN" SG_ 2364734974 HVBusActiveIsolTestStatus 16884;
BA_ "SigType" SG_ 2364734974 CenterOfPackContactorSt 4;
BA_ "SPN" SG_ 2364734974 CenterOfPackContactorSt 16883;
BA_ "SigType" SG_ 2364734974 HVBusPreChargeRelaySt 4;
BA_ "SPN" SG_ 2364734974 HVBusPreChargeRelaySt 16882;
BA_ "SPN" SG_ 2364734974 HVBusDisconnectForewarning 16881;
BA_ "SigType" SG_ 2364734974 HVBusContactorSt16880 4;
BA_ "SPN" SG_ 2364734974 HVBusContactorSt16880 16880;
BA_ "SigType" SG_ 2364734974 HVBusContactorSt 4;
BA_ "SPN" SG_ 2364734974 HVBusContactorSt 16879;
BA_ "SigType" SG_ 2364734718 Temp 1;
BA_ "SPN" SG_ 2364734718 Temp 16878;
BA_ "SigType" SG_ 2364734718 ETemp 1;
BA_ "SPN" SG_ 2364734718 ETemp 16877;
BA_ "SigType" SG_ 2364734718 OutCoolantTemp 1;
BA_ "SPN" SG_ 2364734718 OutCoolantTemp 16876;
BA_ "SigType" SG_ 2364734718 InCoolantTemp 1;
BA_ "SPN" SG_ 2364734718 InCoolantTemp 16875;
BA_ "SigType" SG_ 2364734718 IgntV 1;
BA_ "SPN" SG_ 2364734718 IgntV 16874;
BA_ "SigType" SG_ 2364734718 BusV 1;
BA_ "SPN" SG_ 2364734718 BusV 16873;
BA_ "SigType" SG_ 2364734462 HighestCellStOfCharge 1;
BA_ "SPN" SG_ 2364734462 HighestCellStOfCharge 16872;
BA_ "SigType" SG_ 2364734462 LowestCellStOfCharge 1;
BA_ "SPN" SG_ 2364734462 LowestCellStOfCharge 16871;
BA_ "SigType" SG_ 2364734462 ChargeCurLmt 1;
BA_ "GenSigStartValue" SG_ 2364734462 ChargeCurLmt 32000;
BA_ "SPN" SG_ 2364734462 ChargeCurLmt 16870;
BA_ "SigType" SG_ 2364734462 DisCurLmt 1;
BA_ "SPN" SG_ 2364734462 DisCurLmt 16869;
BA_ "SigType" SG_ 2364734206 CellBalancingCount 1;
BA_ "SPN" SG_ 2364734206 CellBalancingCount 16868;
BA_ "SigType" SG_ 2364734206 ChargeCapacity 1;
BA_ "SPN" SG_ 2364734206 ChargeCapacity 16867;
BA_ "SigType" SG_ 2364734206 DisCapacity 1;
BA_ "SPN" SG_ 2364734206 DisCapacity 16866;
BA_ "SigType" SG_ 2364733950 CellTempDiffStatus 4;
BA_ "SPN" SG_ 2364733950 CellTempDiffStatus 16865;
BA_ "SigType" SG_ 2364733950 AvgCellTemp 1;
BA_ "SPN" SG_ 2364733950 AvgCellTemp 16864;
BA_ "SigType" SG_ 2364733950 LowestCellTemp 1;
BA_ "SPN" SG_ 2364733950 LowestCellTemp 16863;
BA_ "SigType" SG_ 2364733950 HighestCellTemp 1;
BA_ "SPN" SG_ 2364733950 HighestCellTemp 16862;
BA_ "SPN" SG_ 2364733694 CellVDiffStatus 16861;
BA_ "SigType" SG_ 2364733694 LowestCellV 1;
BA_ "SPN" SG_ 2364733694 LowestCellV 16860;
BA_ "SigType" SG_ 2364733694 HighestCellV 1;
BA_ "SPN" SG_ 2364733694 HighestCellV 16859;
BA_ "SigType" SG_ 2364733694 FastUpdateStOfCharge 1;
BA_ "SPN" SG_ 2364733694 FastUpdateStOfCharge 16858;
VAL_ 2364743934 Data9EmbeddedIntegritySupport 3 "CRC and Counter are not supported by the sender" 2 "Reserved" 1 "Protection is supported using J1939-76 SHM" 0 "Embedded CRC and Counter are supported by the sender" ;
VAL_ 2364743934 HVESS24ThermalEventDetected 3 "Not available" 2 "Error" 1 "Thermal Event Detected" 0 "No Thermal Event Detected" ;
VAL_ 2364743422 TMSCoolantLvl 3 "Not Available" 2 "Error" 1 "Coolant Level is sufficient" 0 "Coolant Level is not sufficient" ;
VAL_ 2364743422 TMSMode 15 "Not Available" 14 "Faulted" 13 "Reserved" 12 "Reserved" 11 "Reserved" 10 "Reserved" 9 "Reserved" 8 "Reserved" 7 "Reserved" 6 "Reserved" 5 "Maintaining" 4 "Drying" 3 "Heating" 2 "Cooling" 1 "Circulating" 0 "Off" ;
VAL_ 2364743422 TMSHVILStatus 3 "Not Available" 2 "Error" 1 "HVIL Open" 0 "HVIL Closed" ;
VAL_ 2364743422 TMSHtrStatus 3 "Not Available" 2 "Error" 1 "Heater On" 0 "Heater Off" ;
VAL_ 2364743166 Module32OperationalStatus 3 "Not Available" 2 "Error" 1 "Operational" 0 "Not Operational" ;
VAL_ 2364743166 Module31OperationalStatus 3 "Not Available" 2 "Error" 1 "Operational" 0 "Not Operational" ;
VAL_ 2364743166 Module30OperationalStatus 3 "Not Available" 2 "Error" 1 "Operational" 0 "Not Operational" ;
VAL_ 2364743166 Module29OperationalStatus 3 "Not Available" 2 "Error" 1 "Operational" 0 "Not Operational" ;
VAL_ 2364743166 Module28OperationalStatus 3 "Not Available" 2 "Error" 1 "Operational" 0 "Not Operational" ;
VAL_ 2364743166 Module27OperationalStatus 3 "Not Available" 2 "Error" 1 "Operational" 0 "Not Operational" ;
VAL_ 2364743166 Module26OperationalStatus 3 "Not Available" 2 "Error" 1 "Operational" 0 "Not Operational" ;
VAL_ 2364743166 Module25OperationalStatus 3 "Not Available" 2 "Error" 1 "Operational" 0 "Not Operational" ;
VAL_ 2364743166 Module24OperationalStatus 3 "Not Available" 2 "Error" 1 "Operational" 0 "Not Operational" ;
VAL_ 2364743166 Module23OperationalStatus 3 "Not Available" 2 "Error" 1 "Operational" 0 "Not Operational" ;
VAL_ 2364743166 Module22OperationalStatus 3 "Not Available" 2 "Error" 1 "Operational" 0 "Not Operational" ;
VAL_ 2364743166 Module21OperationalStatus 3 "Not Available" 2 "Error" 1 "Operational" 0 "Not Operational" ;
VAL_ 2364743166 Module20OperationalStatus 3 "Not Available" 2 "Error" 1 "Operational" 0 "Not Operational" ;
VAL_ 2364743166 Module19OperationalStatus 3 "Not Available" 2 "Error" 1 "Operational" 0 "Not Operational" ;
VAL_ 2364743166 Module18OperationalStatus 3 "Not Available" 2 "Error" 1 "Operational" 0 "Not Operational" ;
VAL_ 2364743166 Module17OperationalStatus 3 "Not Available" 2 "Error" 1 "Operational" 0 "Not Operational" ;
VAL_ 2364743166 Module16OperationalStatus 3 "Not Available" 2 "Error" 1 "Operational" 0 "Not Operational" ;
VAL_ 2364743166 Module15OperationalStatus 3 "Not Available" 2 "Error" 1 "Operational" 0 "Not Operational" ;
VAL_ 2364743166 Module14OperationalStatus 3 "Not Available" 2 "Error" 1 "Operational" 0 "Not Operational" ;
VAL_ 2364743166 Module13OperationalStatus 3 "Not Available" 2 "Error" 1 "Operational" 0 "Not Operational" ;
VAL_ 2364743166 Module12OperationalStatus 3 "Not Available" 2 "Error" 1 "Operational" 0 "Not Operational" ;
VAL_ 2364743166 Module11OperationalStatus 3 "Not Available" 2 "Error" 1 "Operational" 0 "Not Operational" ;
VAL_ 2364743166 Module10OperationalStatus 3 "Not Available" 2 "Error" 1 "Operational" 0 "Not Operational" ;
VAL_ 2364743166 Module9OperationalStatus 3 "Not Available" 2 "Error" 1 "Operational" 0 "Not Operational" ;
VAL_ 2364743166 Module8OperationalStatus 3 "Not Available" 2 "Error" 1 "Operational" 0 "Not Operational" ;
VAL_ 2364743166 Module7OperationalStatus 3 "Not Available" 2 "Error" 1 "Operational" 0 "Not Operational" ;
VAL_ 2364743166 Module6OperationalStatus 3 "Not Available" 2 "Error" 1 "Operational" 0 "Not Operational" ;
VAL_ 2364743166 Module5OperationalStatus 3 "Not Available" 2 "Error" 1 "Operational" 0 "Not Operational" ;
VAL_ 2364743166 Module4OperationalStatus 3 "Not Available" 2 "Error" 1 "Operational" 0 "Not Operational" ;
VAL_ 2364743166 Module3OperationalStatus 3 "Not Available" 2 "Error" 1 "Operational" 0 "Not Operational" ;
VAL_ 2364743166 Module2OperationalStatus 3 "Not Available" 2 "Error" 1 "Operational" 0 "Not Operational" ;
VAL_ 2364743166 Module1OperationalStatus 3 "Not Available" 2 "Error" 1 "Operational" 0 "Not Operational" ;
VAL_ 2364742654 OperationalStatus 15 "Not Available" 14 "Error" 13 "Reserved" 12 "Reserved" 11 "Reserved" 10 "Reserved" 9 "Reserved" 8 "Reserved" 7 "Reserved" 6 "Disabled by internal decision of HVES controller" 5 "Disabled by external command" 4 "Emergency Power-Down In Process" 3 "Normal Power-Down in Process" 2 "Operational." 1 "Initialization Complete" 0 "Initialization in process" ;
VAL_ 2364742654 HVBusConnectionStatus 15 "Not Available" 14 "Error" 13 "Reserved" 12 "Reserved" 11 "Reserved" 10 "Reserved" 9 "Reserved" 8 "Reserved" 7 "Reserved" 6 "Reserved" 5 "Reserved" 4 "Disconnected,  Precharge Failed" 3 "Disconnection in Process" 2 "Connection in Process" 1 "Connected" 0 "Disconnected, One or more contactors are open" ;
VAL_ 2364742654 InternalChargerStatus 3 "Not Available" 2 "Error" 1 "Charging on" 0 "Charging off" ;
VAL_ 2364742654 CellBalancingActive 3 "Not Available" 2 "Error" 1 "Cell balancing is active" 0 "Cell balancing is not active" ;
VAL_ 2364742654 CellBalanceStatus 3 "Not Available" 2 "Error" 1 "Cells are unbalanced" 0 "Cells are balanced" ;
VAL_ 2364742654 StOfChargeStatus 15 "Not  Available" 14 "Error" 13 "Reserved" 12 "Reserved" 11 "Reserved" 10 "Reserved" 9 "Reserved" 8 "Reserved" 7 "Reserved" 6 "SOC is above its recommended upper limit" 5 "SOC is at its recommended upper limit" 4 "SOC is approaching its recommended upper limit" 3 "SOC is below its recommended lower limit" 2 "SOC is at its recommended lower limit" 1 "SOC is approaching its recommended lower limit" 0 "SOC level is acceptable" ;
VAL_ 2364742654 InertiaSwStatus 3 "Not Available" 2 "Error" 1 "Impact sensed" 0 "No impact sensed" ;
VAL_ 2364742654 HVILStatus 3 "Not Available" 2 "Error" 1 "HVIL Open" 0 "HVIL Closed" ;
VAL_ 2364742654 HVBusPassiveIsolTestStatus 15 "Not available" 14 "Error" 13 "Reserved" 12 "Reserved" 11 "Reserved" 10 "Reserved" 9 "Reserved" 8 "Reserved" 7 "Reserved" 6 "Reserved" 5 "Test complete,  isolation fault" 4 "Test complete,  isolation marginal" 3 "Test complete,  isolation acceptable" 2 "Test in process" 1 "Test requested but not yet in process" 0 "No test requested / No test in process" ;
VAL_ 2364742654 HVBusActiveIsolTestStatus 15 "Not available" 14 "Error" 13 "Reserved" 12 "Reserved" 11 "Reserved" 10 "Reserved" 9 "Reserved" 8 "Reserved" 7 "Reserved" 6 "Reserved" 5 "Test complete,  isolation fault" 4 "Test complete,  isolation marginal" 3 "Test complete,  isolation acceptable" 2 "Test in process" 1 "Test requested but not yet in process" 0 "No test requested / No test in process" ;
VAL_ 2364742654 CenterOfPackContactorSt 3 "Not Available" 2 "Error" 1 "Contactor Closed" 0 "Contactor Open" ;
VAL_ 2364742654 HVBusPreChargeRelaySt 3 "Not Available" 2 "Error" 1 "Relay Closed" 0 "Relay Open" ;
VAL_ 2364742654 HVBusDisconnectForewarning 15 "Not Available" 14 "Error" 13 "Disconnect imminent" 12 "Reserved" 11 "Reserved" 10 "Reserved" 9 "Reserved" 8 "Reserved" 7 "Disconnect imminent due to battery pack current approaching maximum acceptable level" 6 "Disconnect imminent due to cell voltage approaching maximum acceptable level" 5 "Disconnect imminent due to cell voltage approaching minimum acceptable level" 4 "Disconnect imminent due to module voltage approaching maximum acceptable level" 3 "Disconnect imminent due to module voltage approaching minimum acceptable level" 2 "Disconnect imminent due to battery pack voltage approaching maximum acceptable level" 1 "Disconnect imminent due to battery pack voltage approaching minimum acceptable level" 0 "Disconnect not pending" ;
VAL_ 2364742654 HVBusContactorSt17164 3 "Not Available" 2 "Error" 1 "Contactor Closed" 0 "Contactor Open" ;
VAL_ 2364742654 HVBusContactorSt 3 "Not Available" 2 "Error" 1 "Contactor Closed" 0 "Contactor Open" ;
VAL_ 2364741630 CellTempDiffStatus 3 "Not Available" 2 "Error" 1 "Cell-to-cell temperature differential exceeds acceptable limits" 0 "Cell-to-cell temperature differential is within acceptable limits" ;
VAL_ 2364741374 CellVDiffStatus 15 "Not Available" 14 "Error" 13 "Reserved" 12 "Reserved" 11 "Reserved" 10 "Reserved" 9 "Reserved" 8 "Reserved" 7 "Reserved" 6 "Reserved" 5 "Reserved" 4 "Exceeds limits and it is not known whether balancing can restore performance" 3 "Exceeds limits and external maintenance balancing cannot restore performance" 2 "Exceeds limits and external maintenance balancing is required" 1 "Exceeds limits and can be corrected via auto-balancing" 0 "Is within acceptable limits" ;
VAL_ 2364740862 ChargePLDueToAnUndefinedCause 3 "Not Available" 2 "Error" 1 "Power limited for this reason" 0 "No power limit for this reason" ;
VAL_ 2364740862 ChargePLDueToBatCur 3 "Not Available" 2 "Error" 1 "Power limited for this reason" 0 "No power limit for this reason" ;
VAL_ 2364740862 ChargePLDueToBatOrCellV 3 "Not Available" 2 "Error" 1 "Power limited for this reason" 0 "No power limit for this reason" ;
VAL_ 2364740862 ChargePLDueToBatDiagCondition 3 "Not Available" 2 "Error" 1 "Power limited for this reason" 0 "No power limit for this reason" ;
VAL_ 2364740862 ChargePLDueToBatTemp 3 "Not Available" 2 "Error" 1 "Power limited for this reason" 0 "No power limit for this reason" ;
VAL_ 2364740862 ChargePLDueToStOfCharge 3 "Not Available" 2 "Error" 1 "Power limited for this reason" 0 "No power limit for this reason" ;
VAL_ 2364740862 DisPLDueToAnUndefinedCause 3 "Not Available" 2 "Error" 1 "Power limited for this reason" 0 "No power limit for this reason" ;
VAL_ 2364740862 DisPLDueToBatCur 3 "Not Available" 2 "Error" 1 "Power limited for this reason" 0 "No power limit for this reason" ;
VAL_ 2364740862 DisPLDueToBatOrCellV 3 "Not Available" 2 "Error" 1 "Power limited for this reason" 0 "No power limit for this reason" ;
VAL_ 2364740862 DisPLDueToBatDiagCondition 3 "Not Available" 2 "Error" 1 "Power limited for this reason" 0 "No power limit for this reason" ;
VAL_ 2364740862 DisPLDueToBatTemp 3 "Not Available" 2 "Error" 1 "Power limited for this reason" 0 "No power limit for this reason" ;
VAL_ 2364740862 DisPLDueToStOfCharge 3 "Not Available" 2 "Error" 1 "Power limited for this reason" 0 "No power limit for this reason" ;
VAL_ 2364740094 Data9EmbeddedIntegritySupport 3 "CRC and Counter are not supported by the sender" 2 "Reserved" 1 "Protection is supported using J1939-76 SHM" 0 "Embedded CRC and Counter are supported by the sender" ;
VAL_ 2364740094 HVESS23ThermalEventDetected 3 "Not available" 2 "Error" 1 "Thermal Event Detected" 0 "No Thermal Event Detected" ;
VAL_ 2364739582 TMSCoolantLvl 3 "Not Available" 2 "Error" 1 "Coolant Level is sufficient" 0 "Coolant Level is not sufficient" ;
VAL_ 2364739582 TMSMode 15 "Not Available" 14 "Faulted" 13 "Reserved" 12 "Reserved" 11 "Reserved" 10 "Reserved" 9 "Reserved" 8 "Reserved" 7 "Reserved" 6 "Reserved" 5 "Maintaining" 4 "Drying" 3 "Heating" 2 "Cooling" 1 "Circulating" 0 "Off" ;
VAL_ 2364739582 TMSHVILStatus 3 "Not Available" 2 "Error" 1 "HVIL Open" 0 "HVIL Closed" ;
VAL_ 2364739582 TMSHtrStatus 3 "Not Available" 2 "Error" 1 "Heater On" 0 "Heater Off" ;
VAL_ 2364739326 Module32OperationalStatus 3 "Not Available" 2 "Error" 1 "Operational" 0 "Not Operational" ;
VAL_ 2364739326 Module31OperationalStatus 3 "Not Available" 2 "Error" 1 "Operational" 0 "Not Operational" ;
VAL_ 2364739326 Module30OperationalStatus 3 "Not Available" 2 "Error" 1 "Operational" 0 "Not Operational" ;
VAL_ 2364739326 Module29OperationalStatus 3 "Not Available" 2 "Error" 1 "Operational" 0 "Not Operational" ;
VAL_ 2364739326 Module28OperationalStatus 3 "Not Available" 2 "Error" 1 "Operational" 0 "Not Operational" ;
VAL_ 2364739326 Module27OperationalStatus 3 "Not Available" 2 "Error" 1 "Operational" 0 "Not Operational" ;
VAL_ 2364739326 Module26OperationalStatus 3 "Not Available" 2 "Error" 1 "Operational" 0 "Not Operational" ;
VAL_ 2364739326 Module25OperationalStatus 3 "Not Available" 2 "Error" 1 "Operational" 0 "Not Operational" ;
VAL_ 2364739326 Module24OperationalStatus 3 "Not Available" 2 "Error" 1 "Operational" 0 "Not Operational" ;
VAL_ 2364739326 Module23OperationalStatus 3 "Not Available" 2 "Error" 1 "Operational" 0 "Not Operational" ;
VAL_ 2364739326 Module22OperationalStatus 3 "Not Available" 2 "Error" 1 "Operational" 0 "Not Operational" ;
VAL_ 2364739326 Module21OperationalStatus 3 "Not Available" 2 "Error" 1 "Operational" 0 "Not Operational" ;
VAL_ 2364739326 Module20OperationalStatus 3 "Not Available" 2 "Error" 1 "Operational" 0 "Not Operational" ;
VAL_ 2364739326 Module19OperationalStatus 3 "Not Available" 2 "Error" 1 "Operational" 0 "Not Operational" ;
VAL_ 2364739326 Module18OperationalStatus 3 "Not Available" 2 "Error" 1 "Operational" 0 "Not Operational" ;
VAL_ 2364739326 Module17OperationalStatus 3 "Not Available" 2 "Error" 1 "Operational" 0 "Not Operational" ;
VAL_ 2364739326 Module16OperationalStatus 3 "Not Available" 2 "Error" 1 "Operational" 0 "Not Operational" ;
VAL_ 2364739326 Module15OperationalStatus 3 "Not Available" 2 "Error" 1 "Operational" 0 "Not Operational" ;
VAL_ 2364739326 Module14OperationalStatus 3 "Not Available" 2 "Error" 1 "Operational" 0 "Not Operational" ;
VAL_ 2364739326 Module13OperationalStatus 3 "Not Available" 2 "Error" 1 "Operational" 0 "Not Operational" ;
VAL_ 2364739326 Module12OperationalStatus 3 "Not Available" 2 "Error" 1 "Operational" 0 "Not Operational" ;
VAL_ 2364739326 Module11OperationalStatus 3 "Not Available" 2 "Error" 1 "Operational" 0 "Not Operational" ;
VAL_ 2364739326 Module10OperationalStatus 3 "Not Available" 2 "Error" 1 "Operational" 0 "Not Operational" ;
VAL_ 2364739326 Module9OperationalStatus 3 "Not Available" 2 "Error" 1 "Operational" 0 "Not Operational" ;
VAL_ 2364739326 Module8OperationalStatus 3 "Not Available" 2 "Error" 1 "Operational" 0 "Not Operational" ;
VAL_ 2364739326 Module7OperationalStatus 3 "Not Available" 2 "Error" 1 "Operational" 0 "Not Operational" ;
VAL_ 2364739326 Module6OperationalStatus 3 "Not Available" 2 "Error" 1 "Operational" 0 "Not Operational" ;
VAL_ 2364739326 Module5OperationalStatus 3 "Not Available" 2 "Error" 1 "Operational" 0 "Not Operational" ;
VAL_ 2364739326 Module4OperationalStatus 3 "Not Available" 2 "Error" 1 "Operational" 0 "Not Operational" ;
VAL_ 2364739326 Module3OperationalStatus 3 "Not Available" 2 "Error" 1 "Operational" 0 "Not Operational" ;
VAL_ 2364739326 Module2OperationalStatus 3 "Not Available" 2 "Error" 1 "Operational" 0 "Not Operational" ;
VAL_ 2364739326 Module1OperationalStatus 3 "Not Available" 2 "Error" 1 "Operational" 0 "Not Operational" ;
VAL_ 2364738814 OperationalStatus 15 "Not Available" 14 "Error" 13 "Reserved" 12 "Reserved" 11 "Reserved" 10 "Reserved" 9 "Reserved" 8 "Reserved" 7 "Reserved" 6 "Disabled by internal decision of HVES controller" 5 "Disabled by external command" 4 "Emergency Power-Down In Process" 3 "Normal Power-Down in Process" 2 "Operational." 1 "Initialization Complete" 0 "Initialization in process" ;
VAL_ 2364738814 HVBusConnectionStatus 15 "Not Available" 14 "Error" 13 "Reserved" 12 "Reserved" 11 "Reserved" 10 "Reserved" 9 "Reserved" 8 "Reserved" 7 "Reserved" 6 "Reserved" 5 "Reserved" 4 "Disconnected,  Precharge Failed" 3 "Disconnection in Process" 2 "Connection in Process" 1 "Connected" 0 "Disconnected, One or more contactors are open" ;
VAL_ 2364738814 InternalChargerStatus 3 "Not Available" 2 "Error" 1 "Charging on" 0 "Charging off" ;
VAL_ 2364738814 CellBalancingActive 3 "Not Available" 2 "Error" 1 "Cell balancing is active" 0 "Cell balancing is not active" ;
VAL_ 2364738814 CellBalanceStatus 3 "Not Available" 2 "Error" 1 "Cells are unbalanced" 0 "Cells are balanced" ;
VAL_ 2364738814 StOfChargeStatus 15 "Not  Available" 14 "Error" 13 "Reserved" 12 "Reserved" 11 "Reserved" 10 "Reserved" 9 "Reserved" 8 "Reserved" 7 "Reserved" 6 "SOC is above its recommended upper limit" 5 "SOC is at its recommended upper limit" 4 "SOC is approaching its recommended upper limit" 3 "SOC is below its recommended lower limit" 2 "SOC is at its recommended lower limit" 1 "SOC is approaching its recommended lower limit" 0 "SOC level is acceptable" ;
VAL_ 2364738814 InertiaSwStatus 3 "Not Available" 2 "Error" 1 "Impact sensed" 0 "No impact sensed" ;
VAL_ 2364738814 HVILStatus 3 "Not Available" 2 "Error" 1 "HVIL Open" 0 "HVIL Closed" ;
VAL_ 2364738814 HVBusPassiveIsolTestStatus 15 "Not available" 14 "Error" 13 "Reserved" 12 "Reserved" 11 "Reserved" 10 "Reserved" 9 "Reserved" 8 "Reserved" 7 "Reserved" 6 "Reserved" 5 "Test complete,  isolation fault" 4 "Test complete,  isolation marginal" 3 "Test complete,  isolation acceptable" 2 "Test in process" 1 "Test requested but not yet in process" 0 "No test requested / No test in process" ;
VAL_ 2364738814 HVBusActiveIsolTestStatus 15 "Not available" 14 "Error" 13 "Reserved" 12 "Reserved" 11 "Reserved" 10 "Reserved" 9 "Reserved" 8 "Reserved" 7 "Reserved" 6 "Reserved" 5 "Test complete,  isolation fault" 4 "Test complete,  isolation marginal" 3 "Test complete,  isolation acceptable" 2 "Test in process" 1 "Test requested but not yet in process" 0 "No test requested / No test in process" ;
VAL_ 2364738814 CenterOfPackContactorSt 3 "Not Available" 2 "Error" 1 "Contactor Closed" 0 "Contactor Open" ;
VAL_ 2364738814 HVBusPreChargeRelaySt 3 "Not Available" 2 "Error" 1 "Relay Closed" 0 "Relay Open" ;
VAL_ 2364738814 HVBusDisconnectForewarning 15 "Not Available" 14 "Error" 13 "Disconnect imminent" 12 "Reserved" 11 "Reserved" 10 "Reserved" 9 "Reserved" 8 "Reserved" 7 "Disconnect imminent due to battery pack current approaching maximum acceptable level" 6 "Disconnect imminent due to cell voltage approaching maximum acceptable level" 5 "Disconnect imminent due to cell voltage approaching minimum acceptable level" 4 "Disconnect imminent due to module voltage approaching maximum acceptable level" 3 "Disconnect imminent due to module voltage approaching minimum acceptable level" 2 "Disconnect imminent due to battery pack voltage approaching maximum acceptable level" 1 "Disconnect imminent due to battery pack voltage approaching minimum acceptable level" 0 "Disconnect not pending" ;
VAL_ 2364738814 HVBusContactorSt17022 3 "Not Available" 2 "Error" 1 "Contactor Closed" 0 "Contactor Open" ;
VAL_ 2364738814 HVBusContactorSt 3 "Not Available" 2 "Error" 1 "Contactor Closed" 0 "Contactor Open" ;
VAL_ 2364737790 CellTempDiffStatus 3 "Not Available" 2 "Error" 1 "Cell-to-cell temperature differential exceeds acceptable limits" 0 "Cell-to-cell temperature differential is within acceptable limits" ;
VAL_ 2364737534 CellVDiffStatus 15 "Not Available" 14 "Error" 13 "Reserved" 12 "Reserved" 11 "Reserved" 10 "Reserved" 9 "Reserved" 8 "Reserved" 7 "Reserved" 6 "Reserved" 5 "Reserved" 4 "Exceeds limits and it is not known whether balancing can restore performance" 3 "Exceeds limits and external maintenance balancing cannot restore performance" 2 "Exceeds limits and external maintenance balancing is required" 1 "Exceeds limits and can be corrected via auto-balancing" 0 "Is within acceptable limits" ;
VAL_ 2364737022 ChargePLDueToAnUndefinedCause 3 "Not Available" 2 "Error" 1 "Power limited for this reason" 0 "No power limit for this reason" ;
VAL_ 2364737022 ChargePLDueToBatCur 3 "Not Available" 2 "Error" 1 "Power limited for this reason" 0 "No power limit for this reason" ;
VAL_ 2364737022 ChargePLDueToBatOrCellV 3 "Not Available" 2 "Error" 1 "Power limited for this reason" 0 "No power limit for this reason" ;
VAL_ 2364737022 ChargePLDueToBatDiagCondition 3 "Not Available" 2 "Error" 1 "Power limited for this reason" 0 "No power limit for this reason" ;
VAL_ 2364737022 ChargePLDueToBatTemp 3 "Not Available" 2 "Error" 1 "Power limited for this reason" 0 "No power limit for this reason" ;
VAL_ 2364737022 ChargePLDueToStOfCharge 3 "Not Available" 2 "Error" 1 "Power limited for this reason" 0 "No power limit for this reason" ;
VAL_ 2364737022 DisPLDueToAnUndefinedCause 3 "Not Available" 2 "Error" 1 "Power limited for this reason" 0 "No power limit for this reason" ;
VAL_ 2364737022 DisPLDueToBatCur 3 "Not Available" 2 "Error" 1 "Power limited for this reason" 0 "No power limit for this reason" ;
VAL_ 2364737022 DisPLDueToBatOrCellV 3 "Not Available" 2 "Error" 1 "Power limited for this reason" 0 "No power limit for this reason" ;
VAL_ 2364737022 DisPLDueToBatDiagCondition 3 "Not Available" 2 "Error" 1 "Power limited for this reason" 0 "No power limit for this reason" ;
VAL_ 2364737022 DisPLDueToBatTemp 3 "Not Available" 2 "Error" 1 "Power limited for this reason" 0 "No power limit for this reason" ;
VAL_ 2364737022 DisPLDueToStOfCharge 3 "Not Available" 2 "Error" 1 "Power limited for this reason" 0 "No power limit for this reason" ;
VAL_ 2364736254 Data9EmbeddedIntegritySupport 3 "CRC and Counter are not supported by the sender" 2 "Reserved" 1 "Protection is supported using J1939-76 SHM" 0 "Embedded CRC and Counter are supported by the sender" ;
VAL_ 2364736254 HVESS22ThermalEventDetected 3 "Not available" 2 "Error" 1 "Thermal Event Detected" 0 "No Thermal Event Detected" ;
VAL_ 2364735742 TMSCoolantLvl 3 "Not Available" 2 "Error" 1 "Coolant Level is sufficient" 0 "Coolant Level is not sufficient" ;
VAL_ 2364735742 TMSMode 15 "Not Available" 14 "Faulted" 13 "Reserved" 12 "Reserved" 11 "Reserved" 10 "Reserved" 9 "Reserved" 8 "Reserved" 7 "Reserved" 6 "Reserved" 5 "Maintaining" 4 "Drying" 3 "Heating" 2 "Cooling" 1 "Circulating" 0 "Off" ;
VAL_ 2364735742 TMSHVILStatus 3 "Not Available" 2 "Error" 1 "HVIL Open" 0 "HVIL Closed" ;
VAL_ 2364735742 TMSHtrStatus 3 "Not Available" 2 "Error" 1 "Heater On" 0 "Heater Off" ;
VAL_ 2364735486 Module32OperationalStatus 3 "Not Available" 2 "Error" 1 "Operational" 0 "Not Operational" ;
VAL_ 2364735486 Module31OperationalStatus 3 "Not Available" 2 "Error" 1 "Operational" 0 "Not Operational" ;
VAL_ 2364735486 Module30OperationalStatus 3 "Not Available" 2 "Error" 1 "Operational" 0 "Not Operational" ;
VAL_ 2364735486 Module29OperationalStatus 3 "Not Available" 2 "Error" 1 "Operational" 0 "Not Operational" ;
VAL_ 2364735486 Module28OperationalStatus 3 "Not Available" 2 "Error" 1 "Operational" 0 "Not Operational" ;
VAL_ 2364735486 Module27OperationalStatus 3 "Not Available" 2 "Error" 1 "Operational" 0 "Not Operational" ;
VAL_ 2364735486 Module26OperationalStatus 3 "Not Available" 2 "Error" 1 "Operational" 0 "Not Operational" ;
VAL_ 2364735486 Module25OperationalStatus 3 "Not Available" 2 "Error" 1 "Operational" 0 "Not Operational" ;
VAL_ 2364735486 Module24OperationalStatus 3 "Not Available" 2 "Error" 1 "Operational" 0 "Not Operational" ;
VAL_ 2364735486 Module23OperationalStatus 3 "Not Available" 2 "Error" 1 "Operational" 0 "Not Operational" ;
VAL_ 2364735486 Module22OperationalStatus 3 "Not Available" 2 "Error" 1 "Operational" 0 "Not Operational" ;
VAL_ 2364735486 Module21OperationalStatus 3 "Not Available" 2 "Error" 1 "Operational" 0 "Not Operational" ;
VAL_ 2364735486 Module20OperationalStatus 3 "Not Available" 2 "Error" 1 "Operational" 0 "Not Operational" ;
VAL_ 2364735486 Module19OperationalStatus 3 "Not Available" 2 "Error" 1 "Operational" 0 "Not Operational" ;
VAL_ 2364735486 Module18OperationalStatus 3 "Not Available" 2 "Error" 1 "Operational" 0 "Not Operational" ;
VAL_ 2364735486 Module17OperationalStatus 3 "Not Available" 2 "Error" 1 "Operational" 0 "Not Operational" ;
VAL_ 2364735486 Module16OperationalStatus 3 "Not Available" 2 "Error" 1 "Operational" 0 "Not Operational" ;
VAL_ 2364735486 Module15OperationalStatus 3 "Not Available" 2 "Error" 1 "Operational" 0 "Not Operational" ;
VAL_ 2364735486 Module14OperationalStatus 3 "Not Available" 2 "Error" 1 "Operational" 0 "Not Operational" ;
VAL_ 2364735486 Module13OperationalStatus 3 "Not Available" 2 "Error" 1 "Operational" 0 "Not Operational" ;
VAL_ 2364735486 Module12OperationalStatus 3 "Not Available" 2 "Error" 1 "Operational" 0 "Not Operational" ;
VAL_ 2364735486 Module11OperationalStatus 3 "Not Available" 2 "Error" 1 "Operational" 0 "Not Operational" ;
VAL_ 2364735486 Module10OperationalStatus 3 "Not Available" 2 "Error" 1 "Operational" 0 "Not Operational" ;
VAL_ 2364735486 Module9OperationalStatus 3 "Not Available" 2 "Error" 1 "Operational" 0 "Not Operational" ;
VAL_ 2364735486 Module8OperationalStatus 3 "Not Available" 2 "Error" 1 "Operational" 0 "Not Operational" ;
VAL_ 2364735486 Module7OperationalStatus 3 "Not Available" 2 "Error" 1 "Operational" 0 "Not Operational" ;
VAL_ 2364735486 Module6OperationalStatus 3 "Not Available" 2 "Error" 1 "Operational" 0 "Not Operational" ;
VAL_ 2364735486 Module5OperationalStatus 3 "Not Available" 2 "Error" 1 "Operational" 0 "Not Operational" ;
VAL_ 2364735486 Module4OperationalStatus 3 "Not Available" 2 "Error" 1 "Operational" 0 "Not Operational" ;
VAL_ 2364735486 Module3OperationalStatus 3 "Not Available" 2 "Error" 1 "Operational" 0 "Not Operational" ;
VAL_ 2364735486 Module2OperationalStatus 3 "Not Available" 2 "Error" 1 "Operational" 0 "Not Operational" ;
VAL_ 2364735486 Module1OperationalStatus 3 "Not Available" 2 "Error" 1 "Operational" 0 "Not Operational" ;
VAL_ 2364734974 OperationalStatus 15 "Not Available" 14 "Error" 13 "Reserved" 12 "Reserved" 11 "Reserved" 10 "Reserved" 9 "Reserved" 8 "Reserved" 7 "Reserved" 6 "Disabled by internal decision of HVES controller" 5 "Disabled by external command" 4 "Emergency Power-Down In Process" 3 "Normal Power-Down in Process" 2 "Operational." 1 "Initialization Complete" 0 "Initialization in process" ;
VAL_ 2364734974 HVBusConnectionStatus 15 "Not Available" 14 "Error" 13 "Reserved" 12 "Reserved" 11 "Reserved" 10 "Reserved" 9 "Reserved" 8 "Reserved" 7 "Reserved" 6 "Reserved" 5 "Reserved" 4 "Disconnected,  Precharge Failed" 3 "Disconnection in Process" 2 "Connection in Process" 1 "Connected" 0 "Disconnected, One or more contactors are open" ;
VAL_ 2364734974 InternalChargerStatus 3 "Not Available" 2 "Error" 1 "Charging on" 0 "Charging off" ;
VAL_ 2364734974 CellBalancingActive 3 "Not Available" 2 "Error" 1 "Cell balancing is active" 0 "Cell balancing is not active" ;
VAL_ 2364734974 CellBalanceStatus 3 "Not Available" 2 "Error" 1 "Cells are unbalanced" 0 "Cells are balanced" ;
VAL_ 2364734974 StOfChargeStatus 15 "Not  Available" 14 "Error" 13 "Reserved" 12 "Reserved" 11 "Reserved" 10 "Reserved" 9 "Reserved" 8 "Reserved" 7 "Reserved" 6 "SOC is above its recommended upper limit" 5 "SOC is at its recommended upper limit" 4 "SOC is approaching its recommended upper limit" 3 "SOC is below its recommended lower limit" 2 "SOC is at its recommended lower limit" 1 "SOC is approaching its recommended lower limit" 0 "SOC level is acceptable" ;
VAL_ 2364734974 InertiaSwStatus 3 "Not Available" 2 "Error" 1 "Impact sensed" 0 "No impact sensed" ;
VAL_ 2364734974 HVILStatus 3 "Not Available" 2 "Error" 1 "HVIL Open" 0 "HVIL Closed" ;
VAL_ 2364734974 HVBusPassiveIsolTestStatus 15 "Not available" 14 "Error" 13 "Reserved" 12 "Reserved" 11 "Reserved" 10 "Reserved" 9 "Reserved" 8 "Reserved" 7 "Reserved" 6 "Reserved" 5 "Test complete,  isolation fault" 4 "Test complete,  isolation marginal" 3 "Test complete,  isolation acceptable" 2 "Test in process" 1 "Test requested but not yet in process" 0 "No test requested / No test in process" ;
VAL_ 2364734974 HVBusActiveIsolTestStatus 15 "Not available" 14 "Error" 13 "Reserved" 12 "Reserved" 11 "Reserved" 10 "Reserved" 9 "Reserved" 8 "Reserved" 7 "Reserved" 6 "Reserved" 5 "Test complete,  isolation fault" 4 "Test complete,  isolation marginal" 3 "Test complete,  isolation acceptable" 2 "Test in process" 1 "Test requested but not yet in process" 0 "No test requested / No test in process" ;
VAL_ 2364734974 CenterOfPackContactorSt 3 "Not Available" 2 "Error" 1 "Contactor Closed" 0 "Contactor Open" ;
VAL_ 2364734974 HVBusPreChargeRelaySt 3 "Not Available" 2 "Error" 1 "Relay Closed" 0 "Relay Open" ;
VAL_ 2364734974 HVBusDisconnectForewarning 15 "Not Available" 14 "Error" 13 "Disconnect imminent" 12 "Reserved" 11 "Reserved" 10 "Reserved" 9 "Reserved" 8 "Reserved" 7 "Disconnect imminent due to battery pack current approaching maximum acceptable level" 6 "Disconnect imminent due to cell voltage approaching maximum acceptable level" 5 "Disconnect imminent due to cell voltage approaching minimum acceptable level" 4 "Disconnect imminent due to module voltage approaching maximum acceptable level" 3 "Disconnect imminent due to module voltage approaching minimum acceptable level" 2 "Disconnect imminent due to battery pack voltage approaching maximum acceptable level" 1 "Disconnect imminent due to battery pack voltage approaching minimum acceptable level" 0 "Disconnect not pending" ;
VAL_ 2364734974 HVBusContactorSt16880 3 "Not Available" 2 "Error" 1 "Contactor Closed" 0 "Contactor Open" ;
VAL_ 2364734974 HVBusContactorSt 3 "Not Available" 2 "Error" 1 "Contactor Closed" 0 "Contactor Open" ;
VAL_ 2364733950 CellTempDiffStatus 3 "Not Available" 2 "Error" 1 "Cell-to-cell temperature differential exceeds acceptable limits" 0 "Cell-to-cell temperature differential is within acceptable limits" ;
VAL_ 2364733694 CellVDiffStatus 15 "Not Available" 14 "Error" 13 "Reserved" 12 "Reserved" 11 "Reserved" 10 "Reserved" 9 "Reserved" 8 "Reserved" 7 "Reserved" 6 "Reserved" 5 "Reserved" 4 "Exceeds limits and it is not known whether balancing can restore performance" 3 "Exceeds limits and external maintenance balancing cannot restore performance" 2 "Exceeds limits and external maintenance balancing is required" 1 "Exceeds limits and can be corrected via auto-balancing" 0 "Is within acceptable limits" ;
